VERSION ""

NS_ :

BS_:

BU_: WPC2 RLPSU DPSU APSU PSB SHVU_RR vHS_B2 FCS EMCU SLB ARS RCM CGW_CCU vDummy_HS_B ATS RLHV SGU PFSU ALBCU DSAU SWRC SHVU_FR RCS RRPSU BLTN_CAM SCM DLBCU OHCL RWPC RRHV WPC HOD ASAU

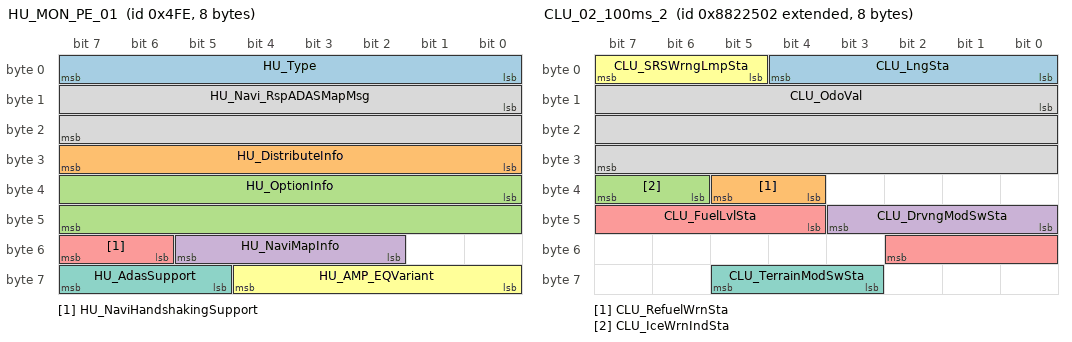
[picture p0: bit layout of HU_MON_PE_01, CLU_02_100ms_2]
BO_ 1278 HU_MON_PE_01: 8 CGW_CCU
 SG_ HU_Type : 0|8@1+ (1,0) [0|0] ""  BLTN_CAM
 SG_ HU_DistributeInfo : 24|8@1+ (1,0) [0|0] ""  BLTN_CAM
 SG_ HU_OptionInfo : 32|16@1+ (1,0) [0|0] ""  RCM,BLTN_CAM,WPC2
 SG_ HU_NaviMapInfo : 50|4@1+ (1,0) [0|0] ""  Vector__XXX
 SG_ HU_NaviHandshakingSupport : 54|2@1+ (1,0) [0|0] ""  Vector__XXX
 SG_ HU_AMP_EQVariant : 56|5@1+ (1,0) [0|0] ""  Vector__XXX
 SG_ HU_AdasSupport : 61|3@1+ (1,0) [0|0] ""  Vector__XXX
 SG_ HU_Navi_RspADASMapMsg : 8|16@1+ (1,0) [0|0] ""  Vector__XXX

BO_ 1279 HU_USM_E_10: 8 CGW_CCU
 SG_ USM_SmartRegen_Map_Set : 11|2@1+ (1,0) [0|0] ""  Vector__XXX
 SG_ USM_SmartRegen_Sens_Set : 13|3@1+ (1,0) [0|0] ""  Vector__XXX
 SG_ AVN_SeatPosMemory_Btn : 16|3@1+ (1,0) [0|0] ""  Vector__XXX
 SG_ AVN_SeatPosPlyBck_Btn : 19|3@1+ (1,0) [0|0] ""  DPSU
 SG_ USM_RhstaLvlEnaSetReq : 22|2@1+ (1,0) [0|0] ""  Vector__XXX
 SG_ USM_CMSDayBrgtnsLvlLHSetReq : 24|4@1+ (1,0) [0|0] ""  Vector__XXX
 SG_ USM_CMSNgtBrgtnsLvlLHSetReq : 28|4@1+ (1,0) [0|0] ""  Vector__XXX
 SG_ USM_CMSDayBrgtnsLvlRHSetReq : 32|4@1+ (1,0) [0|0] ""  Vector__XXX
 SG_ USM_CMSNgtBrgtnsLvlRHSetReq : 36|4@1+ (1,0) [0|0] ""  Vector__XXX
 SG_ USM_CMSBrgtnsReset : 40|2@1+ (1,0) [0|0] ""  Vector__XXX
 SG_ USM_TurnDistLnDispSetReq : 42|2@1+ (1,0) [0|0] ""  Vector__XXX
 SG_ PCA_FrSd_NValueSet : 44|2@1+ (1,0) [0|0] ""  Vector__XXX
 SG_ CF_AVN_1stRrStRmndNValueSet : 46|2@1+ (1,0) [0|0] ""  Vector__XXX
 SG_ C_AllDrOpnNValueSet : 52|3@1+ (1,0) [0|0] ""  Vector__XXX
 SG_ USM_RpmECOSet : 55|2@1+ (1,0) [0|0] ""  Vector__XXX
 SG_ VESS_ChgGuideMdLvl : 57|3@1+ (1,0) [0|0] ""  Vector__XXX
 SG_ Usm_RpmSPORTSet : 60|2@1+ (1,0) [0|0] ""  Vector__XXX
 SG_ Usm_RpmSPORTPLUSSet : 62|2@1+ (1,0) [0|0] ""  Vector__XXX

BO_ 2290230530 CLU_02_100ms_2: 8 CGW_CCU
 SG_ CLU_LngSta : 0|5@1+ (1,0) [0|0] ""  Vector__XXX
 SG_ CLU_RefuelWrnSta : 36|2@1+ (1,0) [0|0] ""  Vector__XXX
 SG_ CLU_IceWrnIndSta : 38|2@1+ (1,0) [0|0] ""  Vector__XXX
 SG_ CLU_DrvngModSwSta : 40|4@1+ (1,0) [0|0] ""  SWRC
 SG_ CLU_FuelLvlSta : 44|7@1+ (1,0) [0|0] "%"  Vector__XXX
 SG_ CLU_SRSWrngLmpSta : 5|3@1+ (1,0) [0|0] ""  Vector__XXX
 SG_ CLU_TerrainModSwSta : 59|3@1+ (1,0) [0|0] ""  SWRC
 SG_ CLU_OdoVal : 8|24@1+ (0.1,0) [0|0] "km"  Vector__XXX

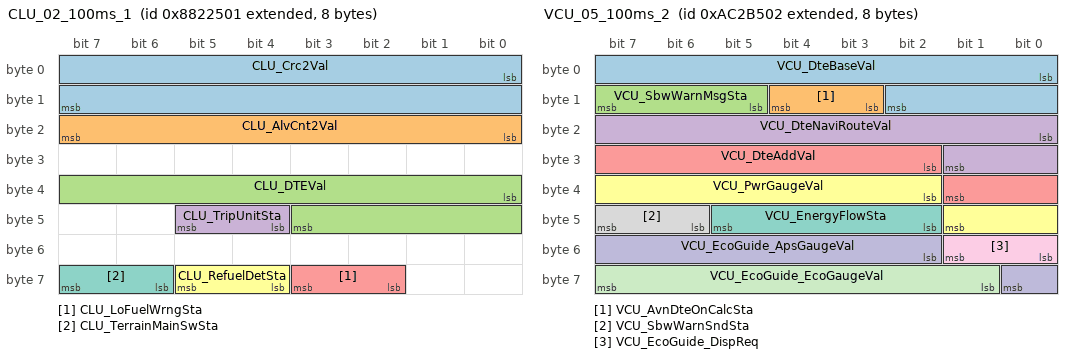
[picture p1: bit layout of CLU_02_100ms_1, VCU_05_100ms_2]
BO_ 2290230529 CLU_02_100ms_1: 8 CGW_CCU
 SG_ CLU_Crc2Val : 0|16@1+ (1,0) [0|0] ""  Vector__XXX
 SG_ CLU_AlvCnt2Val : 16|8@1+ (1,0) [0|0] ""  Vector__XXX
 SG_ CLU_DTEVal : 32|12@1+ (1,0) [0|0] ""  Vector__XXX
 SG_ CLU_TripUnitSta : 44|2@1+ (1,0) [0|0] ""  Vector__XXX
 SG_ CLU_LoFuelWrngSta : 58|2@1+ (1,0) [0|0] ""  Vector__XXX
 SG_ CLU_RefuelDetSta : 60|2@1+ (1,0) [0|0] ""  Vector__XXX
 SG_ CLU_TerrainMainSwSta : 62|2@1+ (1,0) [0|0] ""  Vector__XXX

BO_ 2328016129 VCU_05_100ms_1: 8 CGW_CCU
 SG_ VCU_Crc5Val : 0|16@1+ (1,0) [0|0] ""  Vector__XXX
 SG_ VCU_AlvCnt5Val : 16|8@1+ (1,0) [0|0] ""  Vector__XXX
 SG_ VCU_EvDrvRdyCluDispSta : 24|2@1+ (1,0) [0|3] ""  SWRC
 SG_ VCU_PwrDnModeSta : 26|2@1+ (1,0) [0|3] ""  Vector__XXX
 SG_ VCU_CluWarnMsgSta : 28|4@1+ (1,0) [0|15] ""  Vector__XXX
 SG_ VCU_DteOffDispSta : 32|2@1+ (1,0) [0|0] "flag"  Vector__XXX
 SG_ VCU_LowSocAlertSta : 34|3@1+ (1,0) [0|7] ""  Vector__XXX
 SG_ VCU_VcrmReq : 38|2@1+ (1,0) [0|3] ""  Vector__XXX
 SG_ VCU_PdlWarnMsgSta : 40|2@1+ (1,0) [0|3] ""  Vector__XXX
 SG_ VCU_AwdDiagDispSta : 42|2@1+ (1,0) [0|0] ""  Vector__XXX
 SG_ VCU_AwdLockDispSta : 44|2@1+ (1,0) [0|0] ""  Vector__XXX
 SG_ VCU_VirtualApsActSta : 46|2@1+ (1,0) [0|3] ""  Vector__XXX
 SG_ VCU_VirtualApsVal : 48|8@1+ (0.3906,0) [0|99.61] "%"  Vector__XXX
 SG_ VCU_ServiceLampReq : 56|2@1+ (1,0) [0|3] ""  Vector__XXX
 SG_ VCU_ServiceModeSta : 58|2@1+ (1,0) [0|3] ""  Vector__XXX
 SG_ VCU_NPosWshModSta : 60|2@1+ (1,0) [0|0] "flag"  Vector__XXX
 SG_ VCU_PowerTrainType : 62|2@1+ (1,0) [0|3] ""  Vector__XXX

BO_ 2328016130 VCU_05_100ms_2: 8 CGW_CCU
 SG_ VCU_DteBaseVal : 0|11@1+ (1,0) [0|2047] "km"  Vector__XXX
 SG_ VCU_AvnDteOnCalcSta : 11|2@1+ (1,0) [0|3] ""  Vector__XXX
 SG_ VCU_SbwWarnMsgSta : 13|3@1+ (1,0) [0|0] "flag"  Vector__XXX
 SG_ VCU_DteNaviRouteVal : 16|10@1+ (2,0) [0|1026] "km"  Vector__XXX
 SG_ VCU_DteAddVal : 26|8@1+ (1,0) [0|255] "km"  Vector__XXX
 SG_ VCU_PwrGaugeVal : 34|8@1- (1,0) [-100|100] "%"  Vector__XXX
 SG_ VCU_EnergyFlowSta : 42|4@1+ (1,0) [0|15] ""  Vector__XXX
 SG_ VCU_SbwWarnSndSta : 46|2@1+ (1,0) [0|0] "flag"  Vector__XXX
 SG_ VCU_EcoGuide_DispReq : 48|2@1+ (1,0) [0|3] ""  Vector__XXX
 SG_ VCU_EcoGuide_ApsGaugeVal : 50|7@1+ (1,0) [0|100] "%"  Vector__XXX
 SG_ VCU_EcoGuide_EcoGaugeVal : 57|7@1+ (1,0) [0|100] "%"  Vector__XXX

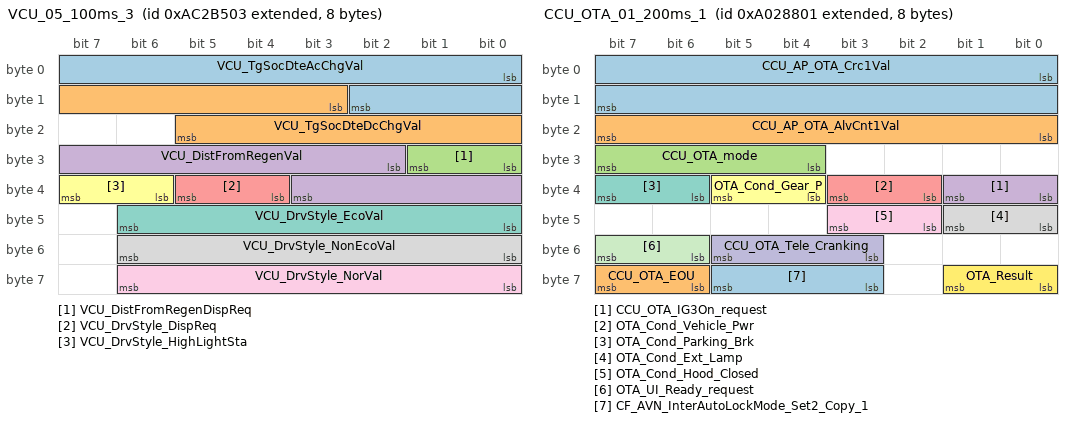
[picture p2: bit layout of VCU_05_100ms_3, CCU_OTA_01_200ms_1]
BO_ 2328016131 VCU_05_100ms_3: 8 CGW_CCU
 SG_ VCU_TgSocDteAcChgVal : 0|11@1+ (1,0) [0|2047] "km"  Vector__XXX
 SG_ VCU_TgSocDteDcChgVal : 11|11@1+ (1,0) [0|2047] "km"  Vector__XXX
 SG_ VCU_DistFromRegenDispReq : 24|2@1+ (1,0) [0|3] ""  Vector__XXX
 SG_ VCU_DistFromRegenVal : 26|10@1+ (10,0) [0|10230] "m"  Vector__XXX
 SG_ VCU_DrvStyle_DispReq : 36|2@1+ (1,0) [0|3] ""  Vector__XXX
 SG_ VCU_DrvStyle_HighLightSta : 38|2@1+ (1,0) [0|3] ""  Vector__XXX
 SG_ VCU_DrvStyle_EcoVal : 40|7@1+ (1,0) [0|100] "%"  Vector__XXX
 SG_ VCU_DrvStyle_NonEcoVal : 48|7@1+ (1,0) [0|100] "%"  Vector__XXX
 SG_ VCU_DrvStyle_NorVal : 56|7@1+ (1,0) [0|100] "%"  Vector__XXX

BO_ 2315421697 CCU_OTA_01_200ms_1: 8 CGW_CCU
 SG_ CCU_AP_OTA_Crc1Val : 0|16@1+ (1,0) [0|0] ""  vDummy_HS_B
 SG_ CCU_AP_OTA_AlvCnt1Val : 16|8@1+ (1,0) [0|0] ""  vDummy_HS_B
 SG_ CCU_OTA_mode : 28|4@1+ (1,0) [0|0] ""  Vector__XXX
 SG_ CCU_OTA_IG3On_request : 32|2@1+ (1,0) [0|0] ""  Vector__XXX
 SG_ OTA_Cond_Vehicle_Pwr : 34|2@1+ (1,0) [0|0] "flag"  Vector__XXX
 SG_ OTA_Cond_Gear_P : 36|2@1+ (1,0) [0|0] "flag"  Vector__XXX
 SG_ OTA_Cond_Parking_Brk : 38|2@1+ (1,0) [0|0] "flag"  Vector__XXX
 SG_ OTA_Cond_Ext_Lamp : 40|2@1+ (1,0) [0|0] "flag"  Vector__XXX
 SG_ OTA_Cond_Hood_Closed : 42|2@1+ (1,0) [0|0] "flag"  Vector__XXX
 SG_ CCU_OTA_Tele_Cranking : 51|3@1+ (1,0) [0|0] ""  Vector__XXX
 SG_ OTA_UI_Ready_request : 54|2@1+ (1,0) [0|0] ""  Vector__XXX
 SG_ OTA_Result : 56|2@1+ (1,0) [0|0] "flag"  Vector__XXX
 SG_ CF_AVN_InterAutoLockMode_Set2_Copy_1 : 59|3@1+ (1,0) [0|0] ""  Vector__XXX
 SG_ CCU_OTA_EOU : 62|2@1+ (1,0) [0|0] ""  Vector__XXX

BO_ 2470763009 CLU_09_00ms_1: 8 CGW_CCU
 SG_ CLU_Crc9Val : 0|16@1+ (1,0) [0|0] ""  Vector__XXX
 SG_ CLU_AlvCnt9Val : 16|8@1+ (1,0) [0|0] ""  Vector__XXX
 SG_ USM_MdLmpClrSetReq : 24|4@1+ (1,0) [0|0] ""  Vector__XXX
 SG_ USM_RrWiperRevSetReq : 28|2@1+ (1,0) [0|0] ""  Vector__XXX
 SG_ USM_RrStRemindSetReq : 30|2@1+ (1,0) [0|0] ""  Vector__XXX
 SG_ USM_RrWpcSetReq : 32|2@1+ (1,0) [0|0] ""  Vector__XXX
 SG_ USM_WpcSetReq : 34|2@1+ (1,0) [0|0] ""  WPC,WPC2
 SG_ USM_SeqLmpSetReq : 36|2@1+ (1,0) [0|0] ""  Vector__XXX
 SG_ USM_UnlckWlcmSetReq : 38|2@1+ (1,0) [0|0] ""  Vector__XXX
 SG_ USM_SmrtWlcmSetReq : 40|2@1+ (1,0) [0|0] ""  Vector__XXX
 SG_ USM_UipSetReq : 42|2@1+ (1,0) [0|0] ""  Vector__XXX
 SG_ USM_DigitalKeyEnblSetReq : 44|2@1+ (1,0) [0|0] ""  Vector__XXX
 SG_ USM_OwnerPhnRegSetReq : 46|2@1+ (1,0) [0|0] ""  Vector__XXX
 SG_ USM_NFCCard1RegSetReq : 48|2@1+ (1,0) [0|0] ""  Vector__XXX
 SG_ USM_NFCCard2RegSetReq : 50|2@1+ (1,0) [0|0] ""  Vector__XXX
 SG_ USM_ProcStpReq : 52|1@1+ (1,0) [0|0] ""  Vector__XXX
 SG_ USM_PwrAutoOffTimeSetReq : 54|3@1+ (1,0) [0|0] ""  Vector__XXX
 SG_ USM_RrStRemindSetReq_RestMode : 57|3@1+ (1,0) [0|0] ""  Vector__XXX
 SG_ USM_1stRrStRemindSetReq : 60|2@1+ (1,0) [0|0] ""  Vector__XXX
 SG_ USM_Wpc2SetReq : 62|2@1+ (1,0) [0|0] ""  WPC2

BO_ 200 HU_USM_E_12: 8 CGW_CCU
 SG_ CF_AVN_ADrLNValueSet_2 : 0|3@1+ (1,0) [0|0] ""  Vector__XXX
 SG_ CF_AVN_FCA_JC_OnOffEquipNvalueSet : 12|2@1+ (1,0) [0|0] ""  Vector__XXX
 SG_ CF_AVN_FCA_FrSdOnOffEquipNvalueSet : 14|2@1+ (1,0) [0|0] ""  Vector__XXX
 SG_ CF_AVN_LKA_OnOffEquip2NvalueSet : 16|2@1+ (1,0) [0|0] ""  Vector__XXX
 SG_ CF_AVN_BCA_OnOffEquip2NvalueSet : 18|2@1+ (1,0) [0|0] ""  Vector__XXX
 SG_ CF_AVN_BVM_OnOffEquipNvalueSet : 20|2@1+ (1,0) [0|0] ""  Vector__XXX
 SG_ CF_AVN_SEA_OnOffEquip3NvalueSet : 22|2@1+ (1,0) [0|0] ""  Vector__XXX
 SG_ CF_AVN_BodySpprtSet_AST : 24|2@1+ (1,0) [0|0] ""  ALBCU
 SG_ CF_AVN_SEW_OnOffEquip3NvalueSet : 26|2@1+ (1,0) [0|0] ""  Vector__XXX
 SG_ CF_AVN_HudImsAutoSave : 28|2@1+ (1,0) [0|0] ""  Vector__XXX
 SG_ USM_PwrDrBuzzerNValueSet : 3|2@1+ (1,0) [0|0] ""  Vector__XXX
 SG_ CF_AVN_DWLNValueSet : 30|3@1+ (1,0) [0|0] ""  Vector__XXX
 SG_ CF_AVN_AirSptTimeNValueSet_AST : 33|3@1+ (1,0) [0|0] ""  ALBCU
 SG_ CF_AVN_AirSptStrNValue_AST : 36|2@1+ (1,0) [0|0] ""  ALBCU
 SG_ CF_AVN_SeatDrvModNvalueSet_AST : 38|2@1+ (1,0) [0|0] ""  ALBCU
 SG_ CF_AVN_TPMS_TireReplaceNValueSet : 40|3@1+ (1,0) [0|0] ""  Vector__XXX
 SG_ CF_AVN_TowModeSet : 43|3@1+ (1,0) [0|0] ""  Vector__XXX
 SG_ USM_PwrDrCloseByBraekNValueSet : 46|2@1+ (1,0) [0|0] ""  Vector__XXX
 SG_ CF_AVN_ISLANAOffstNvalueSet : 50|3@1+ (1,0) [0|0] ""  Vector__XXX
 SG_ CF_Gway_WPC2_NValueSet : 53|2@1+ (1,0) [0|0] ""  WPC2
 SG_ USM_DrvGhostDoorReq : 56|2@1+ (1,0) [0|0] ""  Vector__XXX
 SG_ USM_AstGhostDoorReq : 58|2@1+ (1,0) [0|0] ""  Vector__XXX
 SG_ USM_RLGhostDoorReq : 60|2@1+ (1,0) [0|0] ""  Vector__XXX
 SG_ USM_RRGhostDoorReq : 62|2@1+ (1,0) [0|0] ""  Vector__XXX
 SG_ CF_AVN_FCA_FrOnOffEquipNvalueSet : 7|2@1+ (1,0) [0|0] ""  Vector__XXX
 SG_ CF_AVN_FCA_WarnTimeNvalueSet : 9|3@1+ (1,0) [0|0] ""  Vector__XXX

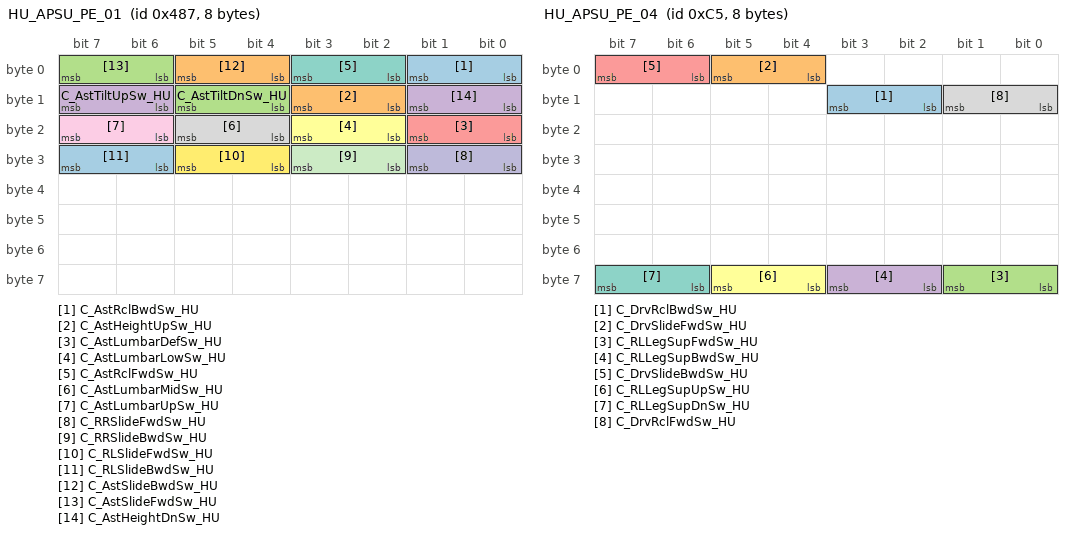
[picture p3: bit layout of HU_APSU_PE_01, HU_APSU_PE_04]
BO_ 1159 HU_APSU_PE_01: 8 CGW_CCU
 SG_ C_AstRclBwdSw_HU : 0|2@1+ (1,0) [0|0] ""  APSU
 SG_ C_AstHeightUpSw_HU : 10|2@1+ (1,0) [0|0] ""  APSU
 SG_ C_AstTiltDnSw_HU : 12|2@1+ (1,0) [0|0] ""  APSU
 SG_ C_AstTiltUpSw_HU : 14|2@1+ (1,0) [0|0] ""  APSU
 SG_ C_AstLumbarDefSw_HU : 16|2@1+ (1,0) [0|0] ""  ASAU,ALBCU
 SG_ C_AstLumbarLowSw_HU : 18|2@1+ (1,0) [0|0] ""  ASAU,ALBCU
 SG_ C_AstRclFwdSw_HU : 2|2@1+ (1,0) [0|0] ""  APSU
 SG_ C_AstLumbarMidSw_HU : 20|2@1+ (1,0) [0|0] ""  ASAU,ALBCU
 SG_ C_AstLumbarUpSw_HU : 22|2@1+ (1,0) [0|0] ""  ASAU,ALBCU
 SG_ C_RRSlideFwdSw_HU : 24|2@1+ (1,0) [0|0] ""  APSU,RRPSU,RLPSU
 SG_ C_RRSlideBwdSw_HU : 26|2@1+ (1,0) [0|0] ""  APSU,RRPSU,RLPSU
 SG_ C_RLSlideFwdSw_HU : 28|2@1+ (1,0) [0|0] ""  APSU,RRPSU,RLPSU
 SG_ C_RLSlideBwdSw_HU : 30|2@1+ (1,0) [0|0] ""  APSU,RRPSU,RLPSU
 SG_ C_AstSlideBwdSw_HU : 4|2@1+ (1,0) [0|0] ""  APSU
 SG_ C_AstSlideFwdSw_HU : 6|2@1+ (1,0) [0|0] ""  APSU
 SG_ C_AstHeightDnSw_HU : 8|2@1+ (1,0) [0|0] ""  APSU

BO_ 197 HU_APSU_PE_04: 8 CGW_CCU
 SG_ C_DrvRclBwdSw_HU : 10|2@1+ (1,0) [0|0] ""  DPSU
 SG_ C_DrvSlideFwdSw_HU : 4|2@1+ (1,0) [0|0] ""  DPSU
 SG_ C_RLLegSupFwdSw_HU : 56|2@1+ (1,0) [0|0] ""  APSU,RRPSU,RLPSU
 SG_ C_RLLegSupBwdSw_HU : 58|2@1+ (1,0) [0|0] ""  APSU,RRPSU,RLPSU
 SG_ C_DrvSlideBwdSw_HU : 6|2@1+ (1,0) [0|0] ""  DPSU
 SG_ C_RLLegSupUpSw_HU : 60|2@1+ (1,0) [0|0] ""  APSU,RRPSU,RLPSU
 SG_ C_RLLegSupDnSw_HU : 62|2@1+ (1,0) [0|0] ""  APSU,RRPSU,RLPSU
 SG_ C_DrvRclFwdSw_HU : 8|2@1+ (1,0) [0|0] ""  DPSU

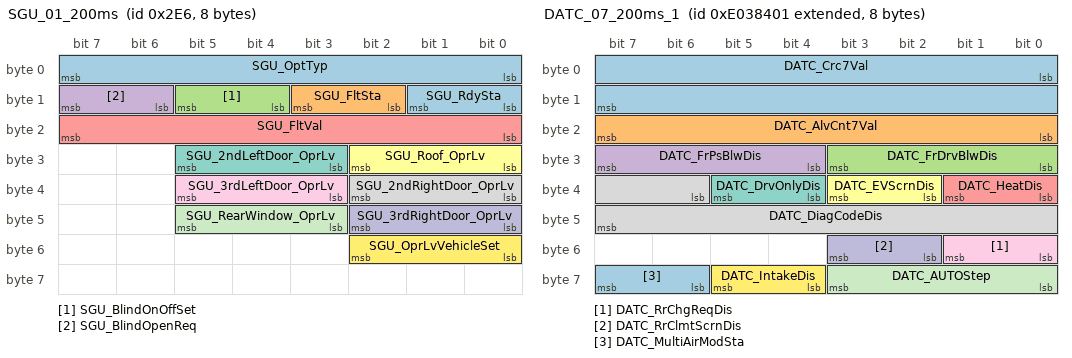
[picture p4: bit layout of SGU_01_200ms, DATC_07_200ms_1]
BO_ 742 SGU_01_200ms: 8 SGU
 SG_ SGU_OptTyp : 0|8@1+ (1,0) [0|0] ""  Vector__XXX
 SG_ SGU_FltSta : 10|2@1+ (1,0) [0|0] ""  Vector__XXX
 SG_ SGU_BlindOnOffSet : 12|2@1+ (1,0) [0|0] ""  CGW_CCU
 SG_ SGU_BlindOpenReq : 14|2@1+ (1,0) [0|0] ""  RCM
 SG_ SGU_FltVal : 16|8@1+ (1,0) [0|0] ""  Vector__XXX
 SG_ SGU_Roof_OprLv : 24|3@1+ (1,0) [0|0] ""  CGW_CCU
 SG_ SGU_2ndLeftDoor_OprLv : 27|3@1+ (1,0) [0|0] ""  CGW_CCU
 SG_ SGU_2ndRightDoor_OprLv : 32|3@1+ (1,0) [0|0] ""  CGW_CCU
 SG_ SGU_3rdLeftDoor_OprLv : 35|3@1+ (1,0) [0|0] ""  CGW_CCU
 SG_ SGU_3rdRightDoor_OprLv : 40|3@1+ (1,0) [0|0] ""  CGW_CCU
 SG_ SGU_RearWindow_OprLv : 43|3@1+ (1,0) [0|0] ""  CGW_CCU
 SG_ SGU_OprLvVehicleSet : 48|3@1+ (1,0) [0|0] ""  CGW_CCU
 SG_ SGU_RdySta : 8|2@1+ (1,0) [0|0] ""  Vector__XXX

BO_ 2382595073 DATC_07_200ms_1: 8 CGW_CCU
 SG_ DATC_Crc7Val : 0|16@1+ (1,0) [0|0] ""  Vector__XXX
 SG_ DATC_AlvCnt7Val : 16|8@1+ (1,0) [0|0] ""  Vector__XXX
 SG_ DATC_FrDrvBlwDis : 24|4@1+ (1,0) [0|0] ""  ATS
 SG_ DATC_FrPsBlwDis : 28|4@1+ (1,0) [0|0] ""  ATS
 SG_ DATC_HeatDis : 32|2@1+ (1,0) [0|0] "flag"  ATS
 SG_ DATC_EVScrnDis : 34|2@1+ (1,0) [0|0] ""  Vector__XXX
 SG_ DATC_DrvOnlyDis : 36|2@1+ (1,0) [0|0] ""  ATS
 SG_ DATC_DiagCodeDis : 38|10@1+ (1,-1) [0|0] ""  Vector__XXX
 SG_ DATC_RrChgReqDis : 48|2@1+ (1,0) [0|0] ""  Vector__XXX
 SG_ DATC_RrClmtScrnDis : 50|2@1+ (1,0) [0|0] ""  ATS
 SG_ DATC_AUTOStep : 56|4@1+ (1,0) [0|0] ""  ATS
 SG_ DATC_IntakeDis : 60|2@1+ (1,0) [0|0] ""  ATS
 SG_ DATC_MultiAirModSta : 62|2@1+ (1,0) [0|0] ""  Vector__XXX

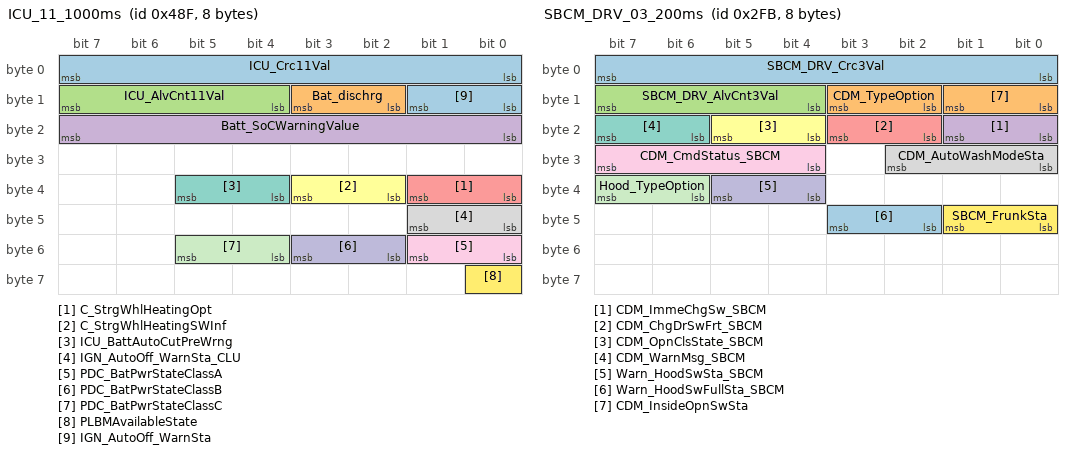
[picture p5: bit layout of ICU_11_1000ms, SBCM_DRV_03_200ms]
BO_ 1167 ICU_11_1000ms: 8 CGW_CCU
 SG_ ICU_Crc11Val : 0|8@1+ (1,0) [0|0] ""  Vector__XXX
 SG_ Bat_dischrg : 10|2@1+ (1,0) [0|0] ""  Vector__XXX
 SG_ ICU_AlvCnt11Val : 12|4@1+ (1,0) [0|0] ""  Vector__XXX
 SG_ Batt_SoCWarningValue : 16|8@1+ (1,0) [0|0] "%"  Vector__XXX
 SG_ C_StrgWhlHeatingOpt : 32|2@1+ (1,0) [0|0] ""  Vector__XXX
 SG_ C_StrgWhlHeatingSWInf : 34|2@1+ (1,0) [0|0] ""  Vector__XXX
 SG_ ICU_BattAutoCutPreWrng : 36|2@1+ (1,0) [0|0] ""  BLTN_CAM
 SG_ IGN_AutoOff_WarnSta_CLU : 40|2@1+ (1,0) [0|0] ""  Vector__XXX
 SG_ PDC_BatPwrStateClassA : 48|2@1+ (1,0) [0|0] ""  Vector__XXX
 SG_ PDC_BatPwrStateClassB : 50|2@1+ (1,0) [0|0] ""  Vector__XXX
 SG_ PDC_BatPwrStateClassC : 52|2@1+ (1,0) [0|0] ""  Vector__XXX
 SG_ PLBMAvailableState : 56|1@1+ (1,0) [0|0] ""  Vector__XXX
 SG_ IGN_AutoOff_WarnSta : 8|2@1+ (1,0) [0|0] ""  Vector__XXX

BO_ 763 SBCM_DRV_03_200ms: 8 CGW_CCU
 SG_ SBCM_DRV_Crc3Val : 0|8@1+ (1,0) [0|0] ""  Vector__XXX
 SG_ CDM_TypeOption : 10|2@1+ (1,0) [0|0] ""  Vector__XXX
 SG_ SBCM_DRV_AlvCnt3Val : 12|4@1+ (1,0) [0|0] ""  Vector__XXX
 SG_ CDM_ImmeChgSw_SBCM : 16|2@1+ (1,0) [0|0] ""  Vector__XXX
 SG_ CDM_ChgDrSwFrt_SBCM : 18|2@1+ (1,0) [0|0] ""  Vector__XXX
 SG_ CDM_OpnClsState_SBCM : 20|2@1+ (1,0) [0|0] ""  Vector__XXX
 SG_ CDM_WarnMsg_SBCM : 22|2@1+ (1,0) [0|0] ""  Vector__XXX
 SG_ CDM_AutoWashModeSta : 24|3@1+ (1,0) [0|0] ""  Vector__XXX
 SG_ CDM_CmdStatus_SBCM : 28|4@1+ (1,0) [0|0] ""  Vector__XXX
 SG_ Warn_HoodSwSta_SBCM : 36|2@1+ (1,0) [0|0] ""  BLTN_CAM
 SG_ Hood_TypeOption : 38|2@1+ (1,0) [0|0] ""  BLTN_CAM
 SG_ SBCM_FrunkSta : 40|2@1+ (1,0) [0|0] ""  Vector__XXX
 SG_ Warn_HoodSwFullSta_SBCM : 42|2@1+ (1,0) [0|0] ""  Vector__XXX
 SG_ CDM_InsideOpnSwSta : 8|2@1+ (1,0) [0|0] ""  Vector__XXX

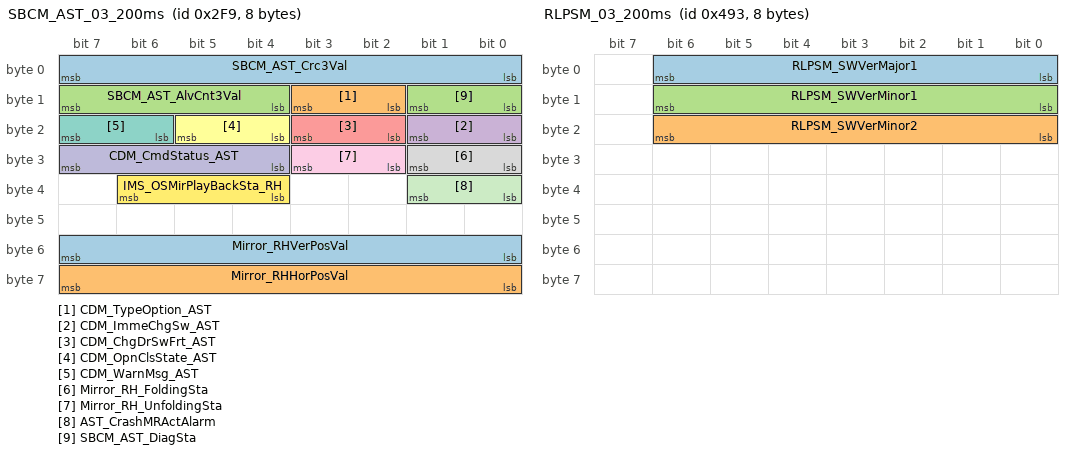
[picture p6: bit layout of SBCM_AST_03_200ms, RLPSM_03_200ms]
BO_ 761 SBCM_AST_03_200ms: 8 CGW_CCU
 SG_ SBCM_AST_Crc3Val : 0|8@1+ (1,0) [0|0] ""  Vector__XXX
 SG_ CDM_TypeOption_AST : 10|2@1+ (1,0) [0|0] ""  Vector__XXX
 SG_ SBCM_AST_AlvCnt3Val : 12|4@1+ (1,0) [0|0] ""  Vector__XXX
 SG_ CDM_ImmeChgSw_AST : 16|2@1+ (1,0) [0|0] ""  Vector__XXX
 SG_ CDM_ChgDrSwFrt_AST : 18|2@1+ (1,0) [0|0] ""  Vector__XXX
 SG_ CDM_OpnClsState_AST : 20|2@1+ (1,0) [0|0] ""  Vector__XXX
 SG_ CDM_WarnMsg_AST : 22|2@1+ (1,0) [0|0] ""  Vector__XXX
 SG_ Mirror_RH_FoldingSta : 24|2@1+ (1,0) [0|0] ""  Vector__XXX
 SG_ Mirror_RH_UnfoldingSta : 26|2@1+ (1,0) [0|0] ""  Vector__XXX
 SG_ CDM_CmdStatus_AST : 28|4@1+ (1,0) [0|0] ""  Vector__XXX
 SG_ AST_CrashMRActAlarm : 32|2@1+ (1,0) [0|0] ""  Vector__XXX
 SG_ IMS_OSMirPlayBackSta_RH : 36|3@1+ (1,0) [0|0] ""  DPSU
 SG_ Mirror_RHVerPosVal : 48|8@1+ (0.02,0) [0|0] "V"  Vector__XXX
 SG_ Mirror_RHHorPosVal : 56|8@1+ (0.02,0) [0|0] "V"  Vector__XXX
 SG_ SBCM_AST_DiagSta : 8|2@1+ (1,0) [0|0] ""  Vector__XXX

BO_ 1171 RLPSM_03_200ms: 8 RLPSU
 SG_ RLPSM_SWVerMajor1 : 0|7@1+ (1,0) [0|0] ""  Vector__XXX
 SG_ RLPSM_SWVerMinor2 : 16|7@1+ (1,0) [0|0] ""  Vector__XXX
 SG_ RLPSM_SWVerMinor1 : 8|7@1+ (1,0) [0|0] ""  Vector__XXX

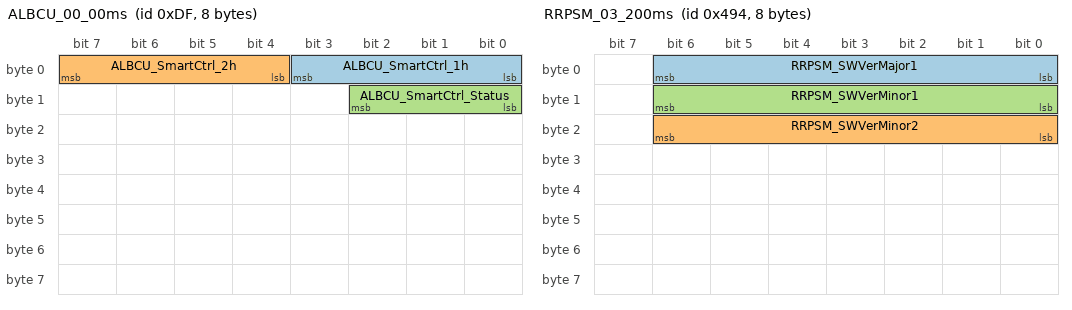
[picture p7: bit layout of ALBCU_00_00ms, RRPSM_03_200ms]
BO_ 223 ALBCU_00_00ms: 8 ALBCU
 SG_ ALBCU_SmartCtrl_1h : 0|4@1+ (1,0) [0|0] ""  CGW_CCU
 SG_ ALBCU_SmartCtrl_2h : 4|4@1+ (1,0) [0|0] ""  CGW_CCU
 SG_ ALBCU_SmartCtrl_Status : 8|3@1+ (1,0) [0|0] ""  CGW_CCU

BO_ 1172 RRPSM_03_200ms: 8 RRPSU
 SG_ RRPSM_SWVerMajor1 : 0|7@1+ (1,0) [0|0] ""  Vector__XXX
 SG_ RRPSM_SWVerMinor2 : 16|7@1+ (1,0) [0|0] ""  Vector__XXX
 SG_ RRPSM_SWVerMinor1 : 8|7@1+ (1,0) [0|0] ""  Vector__XXX

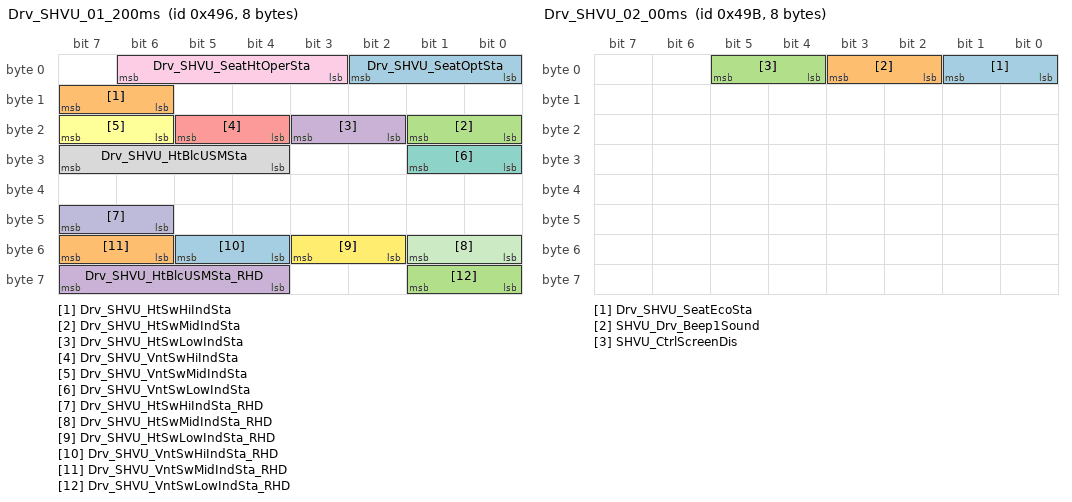
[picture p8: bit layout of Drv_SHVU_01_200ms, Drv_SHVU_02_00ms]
BO_ 1174 Drv_SHVU_01_200ms: 8 APSU
 SG_ Drv_SHVU_SeatOptSta : 0|3@1+ (1,0) [0|0] ""  CGW_CCU,FCS,CGW_CCU
 SG_ Drv_SHVU_HtSwHiIndSta : 14|2@1+ (1,0) [0|0] ""  FCS,CGW_CCU
 SG_ Drv_SHVU_HtSwMidIndSta : 16|2@1+ (1,0) [0|0] ""  FCS,CGW_CCU
 SG_ Drv_SHVU_HtSwLowIndSta : 18|2@1+ (1,0) [0|0] ""  FCS,CGW_CCU
 SG_ Drv_SHVU_VntSwHiIndSta : 20|2@1+ (1,0) [0|0] ""  FCS,CGW_CCU
 SG_ Drv_SHVU_VntSwMidIndSta : 22|2@1+ (1,0) [0|0] ""  FCS,CGW_CCU
 SG_ Drv_SHVU_VntSwLowIndSta : 24|2@1+ (1,0) [0|0] ""  FCS,CGW_CCU
 SG_ Drv_SHVU_HtBlcUSMSta : 28|4@1+ (1,0) [0|0] ""  CGW_CCU
 SG_ Drv_SHVU_SeatHtOperSta : 3|4@1+ (1,0) [0|0] ""  CGW_CCU
 SG_ Drv_SHVU_HtSwHiIndSta_RHD : 46|2@1+ (1,0) [0|0] ""  FCS,CGW_CCU
 SG_ Drv_SHVU_HtSwMidIndSta_RHD : 48|2@1+ (1,0) [0|0] ""  FCS,CGW_CCU
 SG_ Drv_SHVU_HtSwLowIndSta_RHD : 50|2@1+ (1,0) [0|0] ""  FCS,CGW_CCU
 SG_ Drv_SHVU_VntSwHiIndSta_RHD : 52|2@1+ (1,0) [0|0] ""  FCS,CGW_CCU
 SG_ Drv_SHVU_VntSwMidIndSta_RHD : 54|2@1+ (1,0) [0|0] ""  FCS,CGW_CCU
 SG_ Drv_SHVU_VntSwLowIndSta_RHD : 56|2@1+ (1,0) [0|0] ""  FCS,CGW_CCU
 SG_ Drv_SHVU_HtBlcUSMSta_RHD : 60|4@1+ (1,0) [0|0] ""  CGW_CCU

BO_ 1179 Drv_SHVU_02_00ms: 8 APSU
 SG_ Drv_SHVU_SeatEcoSta : 0|2@1+ (1,0) [0|0] ""  CGW_CCU
 SG_ SHVU_Drv_Beep1Sound : 2|2@1+ (1,0) [0|0] ""  CGW_CCU
 SG_ SHVU_CtrlScreenDis : 4|2@1+ (1,0) [0|0] ""  CGW_CCU

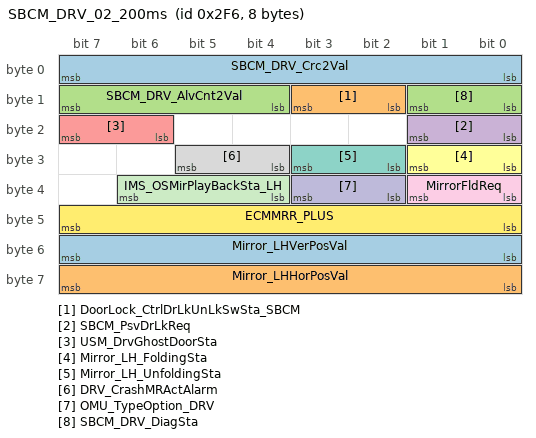
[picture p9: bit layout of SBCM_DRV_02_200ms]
BO_ 758 SBCM_DRV_02_200ms: 8 CGW_CCU
 SG_ SBCM_DRV_Crc2Val : 0|8@1+ (1,0) [0|0] ""  Vector__XXX
 SG_ DoorLock_CtrlDrLkUnLkSwSta_SBCM : 10|2@1+ (1,0) [0|0] ""  Vector__XXX
 SG_ SBCM_DRV_AlvCnt2Val : 12|4@1+ (1,0) [0|0] ""  Vector__XXX
 SG_ SBCM_PsvDrLkReq : 16|2@1+ (1,0) [0|0] ""  Vector__XXX
 SG_ USM_DrvGhostDoorSta : 22|2@1+ (1,0) [0|0] ""  Vector__XXX
 SG_ Mirror_LH_FoldingSta : 24|2@1+ (1,0) [0|0] ""  Vector__XXX
 SG_ Mirror_LH_UnfoldingSta : 26|2@1+ (1,0) [0|0] ""  Vector__XXX
 SG_ DRV_CrashMRActAlarm : 28|2@1+ (1,0) [0|0] ""  Vector__XXX
 SG_ MirrorFldReq : 32|2@1+ (1,0) [0|0] ""  Vector__XXX
 SG_ OMU_TypeOption_DRV : 34|2@1+ (1,0) [0|0] ""  Vector__XXX
 SG_ IMS_OSMirPlayBackSta_LH : 36|3@1+ (1,0) [0|0] ""  DPSU
 SG_ ECMMRR_PLUS : 40|8@1+ (1,0) [0|0] ""  Vector__XXX
 SG_ Mirror_LHVerPosVal : 48|8@1+ (0.02,0) [0|0] "V"  Vector__XXX
 SG_ Mirror_LHHorPosVal : 56|8@1+ (0.02,0) [0|0] "V"  Vector__XXX
 SG_ SBCM_DRV_DiagSta : 8|2@1+ (1,0) [0|0] ""  Vector__XXX

BO_ 208 RR_SHVU_03_200ms: 8 RRHV
 SG_ RR_SHVU_DTCdisplay : 0|8@1+ (1,0) [0|0] ""  ATS
 SG_ RR_SHVU_DiagMode : 8|2@1+ (1,0) [0|0] ""  ATS

BO_ 1180 Ast_SHVU_02_00ms: 8 SHVU_FR
 SG_ SHVU_Ast_Beep1Sound : 2|2@1+ (1,0) [0|0] ""  CGW_CCU
 SG_ Ast_SHVU_SeatEcoSta : 26|2@1+ (1,0) [0|0] ""  CGW_CCU

BO_ 1181 RL_SHVU_02_00ms: 8 SHVU_RR
 SG_ RL_SHVU_SeatEcoSta : 0|2@1+ (1,0) [0|0] ""  ATS,CGW_CCU

BO_ 1182 RR_SHVU_02_00ms: 8 SHVU_FR
 SG_ RR_SHVU_SeatEcoSta : 0|2@1+ (1,0) [0|0] ""  ATS,CGW_CCU

BO_TX_BU_ 1174 : APSU,SHVU_FR,DPSU;
BO_TX_BU_ 1179 : APSU,SHVU_FR;
BO_TX_BU_ 208 : RRHV,SHVU_FR,SHVU_RR;
BO_TX_BU_ 1181 : SHVU_RR,SHVU_FR,RLHV,RLPSU;
BO_TX_BU_ 1182 : SHVU_FR,RRPSU,SHVU_RR,RRHV;
CM_ BO_ 223 "[EC] On Event and On Change";
CM_ SG_ 223 ALBCU_SmartCtrl_1h "Smart Posture Adjust 1hr";
CM_ SG_ 223 ALBCU_SmartCtrl_2h "Smart Posture Adjust AVN Display (2hr)";
CM_ SG_ 223 ALBCU_SmartCtrl_Status "Smart Posture Adjust 2nd Interlocked Move AVN popup request";
CM_ BO_ 1180 "[EC] On Event and On Change";
CM_ SG_ 1180 SHVU_Ast_Beep1Sound "SHVU_FR Assistant's Seat Heater or Ventilation Switch input Beep Request";
CM_ SG_ 1180 Ast_SHVU_SeatEcoSta "Assistant (Passenger) Seat Eco+ Mode Status";
CM_ BO_ 2315421697 "[PE] Periodic and On Event";
CM_ SG_ 2315421697 CCU_OTA_mode "OTA_mode";
CM_ SG_ 2315421697 CCU_OTA_IG3On_request "IG3 Rly ON request";
CM_ SG_ 2315421697 CCU_OTA_Tele_Cranking "Vehicle cranking request signfal for OTA Update";
CM_ SG_ 2315421697 OTA_UI_Ready_request "OTA UI Ready";
CM_ SG_ 2315421697 OTA_Result "¾÷µ¥ÀÌÆ® °á°ú";
CM_ SG_ 2315421697 CF_AVN_InterAutoLockMode_Set2_Copy_1 "USM Request for Charing Connector Locking Mode (Auto/Lock/Unlock)";
CM_ BO_ 2290230529 "[P] Periodic";
CM_ SG_ 2290230529 CLU_Crc2Val "CLU_CyclicRedundancyCheck2Value";
CM_ SG_ 2290230529 CLU_AlvCnt2Val "CLU_AliveCounter2Value";
CM_ SG_ 2290230529 CLU_DTEVal "CLU_DTEValue";
CM_ SG_ 2290230529 CLU_TripUnitSta "CLU_TripUnitStatus";
CM_ SG_ 2290230529 CLU_LoFuelWrngSta "CLU_LowFuelWarningStatus";
CM_ SG_ 2290230529 CLU_RefuelDetSta "CLU_RefuelDetectedStatus";
CM_ SG_ 2290230529 CLU_TerrainMainSwSta "CLU_TerrainMainSwitchStatus";
CM_ BO_ 2290230530 "[P] Periodic";
CM_ SG_ 2290230530 CLU_LngSta "CLU_LanguageStatus";
CM_ SG_ 2290230530 CLU_RefuelWrnSta "CLU_RefuelWarningStatus";
CM_ SG_ 2290230530 CLU_IceWrnIndSta "CLU_IceWarnIndicatorStatus";
CM_ SG_ 2290230530 CLU_DrvngModSwSta "CLU_DrivingModeSwitchStatus";
CM_ SG_ 2290230530 CLU_FuelLvlSta "CLU_FuelLevelStatus";
CM_ SG_ 2290230530 CLU_SRSWrngLmpSta "CLU_SRSWarningLampStatus";
CM_ SG_ 2290230530 CLU_TerrainModSwSta "CLU_TerrainModeSwitchStatus";
CM_ SG_ 2290230530 CLU_OdoVal "CLU_OdometerValue";
CM_ BO_ 2470763009 "[EC] On Event and On Change";
CM_ SG_ 2470763009 CLU_Crc9Val "CLU_CyclicRedundancyCheck9Value";
CM_ SG_ 2470763009 CLU_AlvCnt9Val "CLU_AliveCounter9Value";
CM_ SG_ 2470763009 USM_MdLmpClrSetReq "USM_MoodLampColorSetRequest";
CM_ SG_ 2470763009 USM_RrWiperRevSetReq "USM_RearWiperReverseSetRequest";
CM_ SG_ 2470763009 USM_RrStRemindSetReq "USM_RrseatReminderSetRequest(2nd :General: CLU20/CF_Clu_RrSeatRemindNValueSet)";
CM_ SG_ 2470763009 USM_RrWpcSetReq "USM_RearWpcSetRequest";
CM_ SG_ 2470763009 USM_WpcSetReq "USM_WpcSetRequest";
CM_ SG_ 2470763009 USM_SeqLmpSetReq "USM_SequencialLampSetRequest";
CM_ SG_ 2470763009 USM_UnlckWlcmSetReq "USM_UnlockWelcomeSetRequest";
CM_ SG_ 2470763009 USM_SmrtWlcmSetReq "USM_SmartWelcomeSetRequest";
CM_ SG_ 2470763009 USM_UipSetReq "2nd General: CF_Clu_UIPNValueSet";
CM_ SG_ 2470763009 USM_DigitalKeyEnblSetReq "Request to set the Digital Key ON or OFF(2nd General DB: CF_Clu_DigitalKeyNValueSet)";
CM_ SG_ 2470763009 USM_OwnerPhnRegSetReq "2nd general DB: CF_Clu_OwnerPhoneNValueSet";
CM_ SG_ 2470763009 USM_NFCCard1RegSetReq "2nd General DB:CF_Clu_NFCCard1NValueSet";
CM_ SG_ 2470763009 USM_NFCCard2RegSetReq "2nd General DB:CF_Clu_NFCCard2NValueSet";
CM_ SG_ 2470763009 USM_ProcStpReq "2nd General DB:CF_Clu_ProcessStopReq";
CM_ SG_ 2470763009 USM_PwrAutoOffTimeSetReq "USM_PowerAutoofftimeSetRequest";
CM_ SG_ 2470763009 USM_RrStRemindSetReq_RestMode "Request to set  Restmod of Rear Seat remind";
CM_ SG_ 2470763009 USM_1stRrStRemindSetReq "USM_RrseatReminderSetRequest(2nd :General: CLU21/CF_Clu_1stRrSeatRemindNValueSet)";
CM_ SG_ 2470763009 USM_Wpc2SetReq "USM_Wpc2SetRequest";
CM_ BO_ 2382595073 "[PE] Periodic and On Event";
CM_ SG_ 2382595073 DATC_Crc7Val "DATC_CyclicRedundancyCheck7Value";
CM_ SG_ 2382595073 DATC_AlvCnt7Val "DATC_AliveCounter7Value";
CM_ SG_ 2382595073 DATC_FrDrvBlwDis "DATC_FrontDriverBlowerDisplay";
CM_ SG_ 2382595073 DATC_FrPsBlwDis "DATC_FrontPassengerBlowerDisplay";
CM_ SG_ 2382595073 DATC_HeatDis "DATC_HeatDisplay";
CM_ SG_ 2382595073 DATC_EVScrnDis "DATC_EVScreenDisplay";
CM_ SG_ 2382595073 DATC_DrvOnlyDis "DATC_DriverOnlyDisplay";
CM_ SG_ 2382595073 DATC_DiagCodeDis "DATC_DiagnosisCodeDisplay";
CM_ SG_ 2382595073 DATC_RrChgReqDis "DATC_RearChangeRequestDisplay";
CM_ SG_ 2382595073 DATC_RrClmtScrnDis "DATC_RearClimateScreenDisplay";
CM_ SG_ 2382595073 DATC_AUTOStep "This signal indicates AUTO step status in case Multi Auto Blower type.";
CM_ SG_ 2382595073 DATC_IntakeDis "This signal indicates intake indicator & display";
CM_ SG_ 2382595073 DATC_MultiAirModSta "This signal indicates MultiAirModeStatus";
CM_ BO_ 1174 "[PE] Periodic and On Event";
CM_ SG_ 1174 Drv_SHVU_SeatOptSta "Drv Seat Heater/Vent option info";
CM_ SG_ 1174 Drv_SHVU_HtSwHiIndSta "Drv Seat Heater Switch High Indicator Status";
CM_ SG_ 1174 Drv_SHVU_HtSwMidIndSta "Drv Seat Heater Switch Mid Indicator Status";
CM_ SG_ 1174 Drv_SHVU_HtSwLowIndSta "Drv Seat Heater Switch Low Indicator Status";
CM_ SG_ 1174 Drv_SHVU_VntSwHiIndSta "Drv Seat Vent Switch High Indicator Status";
CM_ SG_ 1174 Drv_SHVU_VntSwMidIndSta "Drv Seat Vent Switch Mid Indicator Status";
CM_ SG_ 1174 Drv_SHVU_VntSwLowIndSta "Drv Seat Vent Switch Low Indicator Status";
CM_ SG_ 1174 Drv_SHVU_HtBlcUSMSta "Hetaer Balance Driver USM R vaule";
CM_ SG_ 1174 Drv_SHVU_SeatHtOperSta "Drv Seat Heater/Vent current operation state";
CM_ SG_ 1174 Drv_SHVU_HtSwHiIndSta_RHD "Drv Seat Heater Switch High Indicator Status(RHD)";
CM_ SG_ 1174 Drv_SHVU_HtSwMidIndSta_RHD "Drv Seat Heater Switch Mid Indicator Status(RHD)";
CM_ SG_ 1174 Drv_SHVU_HtSwLowIndSta_RHD "Drv Seat Heater Switch Low Indicator Status(RHD)";
CM_ SG_ 1174 Drv_SHVU_VntSwHiIndSta_RHD "Drv Seat Vent Switch High Indicator Status(RHD)";
CM_ SG_ 1174 Drv_SHVU_VntSwMidIndSta_RHD "Drv Seat Vent Switch Mid Indicator Status(RHD)";
CM_ SG_ 1174 Drv_SHVU_VntSwLowIndSta_RHD "Drv Seat Vent Switch Low Indicator Status(RHD)";
CM_ SG_ 1174 Drv_SHVU_HtBlcUSMSta_RHD "Hetaer Balance Driver USM R vaule(RHD)";
CM_ BO_ 1179 "[EC] On Event and On Change";
CM_ SG_ 1179 Drv_SHVU_SeatEcoSta "Driver Seat Eco+ Mode Status";
CM_ SG_ 1179 SHVU_Drv_Beep1Sound "SHVU_FR Driver's Seat Heater or Ventilation Switch input Beep Request";
CM_ SG_ 1179 SHVU_CtrlScreenDis "Request AVN screen change for controlling Seat Heater or Ventilation";
CM_ BO_ 1159 "[PE] Periodic and On Event";
CM_ SG_ 1159 C_AstRclBwdSw_HU "Assistant seat Moving control :Recline Backward";
CM_ SG_ 1159 C_AstHeightUpSw_HU "Assistant seat Moving control : Height Up";
CM_ SG_ 1159 C_AstTiltDnSw_HU "Assistant seat Moving control : Tilt Down";
CM_ SG_ 1159 C_AstTiltUpSw_HU "Assistant seat Moving Switch : Tilt Up";
CM_ SG_ 1159 C_AstLumbarDefSw_HU "Assistant seat moving switch: Deflate";
CM_ SG_ 1159 C_AstLumbarLowSw_HU "Assistant seat moving switch:Lumbar Low";
CM_ SG_ 1159 C_AstRclFwdSw_HU "Assistant seat Moving Switch : Recline Forward";
CM_ SG_ 1159 C_AstLumbarMidSw_HU "Assistant seat Moving control : Lumbar Mid";
CM_ SG_ 1159 C_AstLumbarUpSw_HU "Assistant seat Moving control : Lumbar Up";
CM_ SG_ 1159 C_RRSlideFwdSw_HU "2nd Right side seat Moving control :Power Slide Forward";
CM_ SG_ 1159 C_RRSlideBwdSw_HU "2nd Right side seat Moving control :Power Slide Backward";
CM_ SG_ 1159 C_RLSlideFwdSw_HU "2nd Left side seat Moving control :Power Slide Forward";
CM_ SG_ 1159 C_RLSlideBwdSw_HU "2nd Left side seat Moving control :Power Slide Backward";
CM_ SG_ 1159 C_AstSlideBwdSw_HU "Assistant seat moving switch : Slide Backward";
CM_ SG_ 1159 C_AstSlideFwdSw_HU "Assistant seat Moving switch : Slide Forward";
CM_ SG_ 1159 C_AstHeightDnSw_HU "Assistant seat Moving control : Height Down";
CM_ BO_ 197 "[PE] Periodic and On Event";
CM_ SG_ 197 C_DrvRclBwdSw_HU "Driver Seat Recline Backward Control";
CM_ SG_ 197 C_DrvSlideFwdSw_HU "Driver Seat Slide Forward Control";
CM_ SG_ 197 C_RLLegSupFwdSw_HU "2nd Left side seat Moving control : Leg Support Forward";
CM_ SG_ 197 C_RLLegSupBwdSw_HU "2nd Left side seat Moving control : Leg Support Backward";
CM_ SG_ 197 C_DrvSlideBwdSw_HU "Driver Seat Slide Backward Control";
CM_ SG_ 197 C_RLLegSupUpSw_HU "2nd Left side seat Moving control : Leg Support Up";
CM_ SG_ 197 C_RLLegSupDnSw_HU "2nd Left side seat Moving control : Leg Support Down";
CM_ SG_ 197 C_DrvRclFwdSw_HU "Driver Seat Recline Forward Control";
CM_ BO_ 1278 "[PE] Periodic and On Event";
CM_ SG_ 1278 HU_Type "Information for H/U Platform type
- Integrated AVN 1.0 use different value depends on development company (Mobis:0x68/LG:0x70)
- Integrated AVN 1.0 Mobis is developed based on Display Audio
- Integrated AVN 1.0 LG is developed based on Compact AVN

Information for China OPIO Platform
- 0xFC: China OPIO w/o CLU interface (most of phase1)
- 0xFD: China OPIO w/CLU interface (parts of phase1, phase2)

Information for Audio Platform Type
- 0x43 : Audio 4.0 Value";
CM_ SG_ 1278 HU_DistributeInfo "Region :Europe/North America/
Vehicle Type : RHD/LHD
Positionning information";
CM_ SG_ 1278 HU_OptionInfo "Information of H/U functions";
CM_ SG_ 1278 HU_NaviMapInfo "Information about map data  used in Navigation";
CM_ SG_ 1278 HU_NaviHandshakingSupport "This is a signal to send whether handshaking logic is applied related to Navigation's 'Map based ADAS' specification";
CM_ SG_ 1278 HU_AMP_EQVariant "Set EQ Variant for various vehicle cases.
During the AMP initializing process, This signal should be sent before AMP unmute.
This signal is only needed for models that have variant EQ for vehicle types. (Hatchback, Wagon, Hybrid etc..)
Models that doesn¡¯t have variant EQ for vehicle types shouldn¡¯t have this signal.";
CM_ SG_ 1278 HU_AdasSupport "Information about ADAS support
-Classify between General Map and Precise Map Transmission Function
-AVN System Transmission Signal";
CM_ SG_ 1278 HU_Navi_RspADASMapMsg "HU_ResponseADASMapMessage";
CM_ BO_ 1279 "[EC] On Event and On Change";
CM_ SG_ 1279 USM_SmartRegen_Map_Set "Smart Regeneration 2.0 Map information USM User set signal";
CM_ SG_ 1279 USM_SmartRegen_Sens_Set "Smart Regeneration User Personality of Reduction Set Signal";
CM_ SG_ 1279 AVN_SeatPosMemory_Btn "Seat position save signal";
CM_ SG_ 1279 AVN_SeatPosPlyBck_Btn "Seat position move signal";
CM_ SG_ 1279 USM_CMSBrgtnsReset "CMS Brightness Reset (LH/RH)";
CM_ SG_ 1279 CF_AVN_1stRrStRmndNValueSet "This signal is for setting the ROA function when IBU control ROA Function.";
CM_ SG_ 1279 VESS_ChgGuideMdLvl "Releated to VESS Alarm Sound Level";
CM_ BO_ 200 "[EC] On Event and On Change";
CM_ SG_ 200 CF_AVN_BodySpprtSet_AST "This signal is for the Ergo-Motion seat (AST) body support (Smart Posture Assist) USM";
CM_ SG_ 200 CF_AVN_AirSptTimeNValueSet_AST "This signal is for the Ergo-Motion seat (AST) massage function time setting";
CM_ SG_ 200 CF_AVN_AirSptStrNValue_AST "This signal is for the ERGO seat (AST) massage intensity USM";
CM_ SG_ 200 CF_AVN_SeatDrvModNvalueSet_AST "This signal is for the Ergo-Motion seat (AST) smart support (Smart Support) USM";
CM_ BO_ 1167 "[PE] Periodic and On Event";
CM_ SG_ 1167 ICU_Crc11Val "ICU_CyclicRedundancyCheck11Value";
CM_ SG_ 1167 Bat_dischrg "Battery discharge notification flag #2G# Bat_dischrg";
CM_ SG_ 1167 ICU_AlvCnt11Val "ICU_AliveCounter11Value";
CM_ SG_ 1167 Batt_SoCWarningValue "Value of SoC warning level. ##2G## -  - Batt_SoCWarningValue";
CM_ SG_ 1167 ICU_BattAutoCutPreWrng "This is a warning signal before blocking the dark current of the ICU by the battery SOC.";
CM_ SG_ 1167 IGN_AutoOff_WarnSta_CLU "this signal is defined as the warning signal related with battery discharge";
CM_ SG_ 1167 PDC_BatPwrStateClassA "Battery Power State ClassA";
CM_ SG_ 1167 PDC_BatPwrStateClassB "Battery Power State ClassB";
CM_ SG_ 1167 PDC_BatPwrStateClassC "Battery Power State ClassC";
CM_ SG_ 1167 IGN_AutoOff_WarnSta "this signal is defined as the warning signal related with battery discharge";
CM_ BO_ 1171 "[PE] Periodic and On Event";
CM_ SG_ 1171 RLPSM_SWVerMajor1 "First Word(ASCII) in RLPSM S/W Ver";
CM_ SG_ 1171 RLPSM_SWVerMinor2 "Third Word(ASCII) in RLPSM S/W Ver";
CM_ SG_ 1171 RLPSM_SWVerMinor1 "Second Word(ASCII) in RLPSM S/W Ver";
CM_ BO_ 1181 "[EC] On Event and On Change";
CM_ SG_ 1181 RL_SHVU_SeatEcoSta "Rear LH Seat Eco+ Mode Status";
CM_ BO_ 1172 "[PE] Periodic and On Event";
CM_ SG_ 1172 RRPSM_SWVerMajor1 "First Word(ASCII) in RRPSM S/W Ver";
CM_ SG_ 1172 RRPSM_SWVerMinor2 "Third Word(ASCII) in RRPSM S/W Ver";
CM_ SG_ 1172 RRPSM_SWVerMinor1 "Second Word(ASCII) in RRPSM S/W Ver";
CM_ BO_ 1182 "[EC] On Event and On Change";
CM_ SG_ 1182 RR_SHVU_SeatEcoSta "Rear RH Seat Eco+ Mode Status";
CM_ BO_ 208 "[PE] Periodic and On Event";
CM_ SG_ 208 RR_SHVU_DTCdisplay "0x00: DTC is not exist(Fail is not exist)/0x01:IGN2 Fuse Open Detection/0x02:Switch Input Detection at Same Time/0x03:NTC/Heating wire Open Detection/0x04:NTC+/NTC- Terminal Short Detection/0x05:NTC+/Heater+ Terminal Short Detection/0x06:NTC+/Heater-, Heater+/Heater-, Heater+/NTC- Terminal Short Detection/0x07:NTC+/Heater- Wiring Short Detection/0x08:NTC+/Heater-, Heater+/Heater-, Heater+/NTC- Wiring Short Detection/0x09:Target Temperature Dissatisfied/0x0A:Blower+/Blower- Short, Blower+/Blower Speed, Blower-/Blower Speed Wiring Short Detection/0x0B:Blower+/Blower RPM, Blower-/Blower RPM, Blower Speed/Blower RPM Short Detection/0x0C:Blower+, Blower-, Blower Speed Signal open Detection/0x0D:Blower RPM signal Open Detection/0x0E~0xFD:Unused/0xFE:No Display/0xFF:Invalid";
CM_ SG_ 208 RR_SHVU_DiagMode "0x0:Default/0x1:DTC Mode/0x2:Normal Mode/0x3:Invalid";
CM_ BO_ 761 "[PE] Periodic and On Event";
CM_ SG_ 761 SBCM_AST_Crc3Val "SBCM_AST_CyclicRedundancyCheck3Value";
CM_ SG_ 761 SBCM_AST_AlvCnt3Val "SBCM_AST_AliveCounter3Value";
CM_ SG_ 761 Mirror_RHVerPosVal "RH Outside Mirror Vertical Position sensor value";
CM_ SG_ 761 Mirror_RHHorPosVal "RH Outside Mirror Horizontal Position sensor value";
CM_ BO_ 758 "[PE] Periodic and On Event";
CM_ SG_ 758 SBCM_DRV_Crc2Val "SBCM_DRV_CyclicRedundancyCheck2Value";
CM_ SG_ 758 DoorLock_CtrlDrLkUnLkSwSta_SBCM "Central Door Lock/Unlock Switch State";
CM_ SG_ 758 SBCM_DRV_AlvCnt2Val "SBCM_DRV_AliveCounter2Value";
CM_ SG_ 758 ECMMRR_PLUS "ECM Voltage value";
CM_ SG_ 758 Mirror_LHVerPosVal "LH Outside Mirror Vertical Position sensor value";
CM_ SG_ 758 Mirror_LHHorPosVal "LH Outside Mirror Horizontal Position Sensor Voltage";
CM_ BO_ 763 "[PE] Periodic and On Event";
CM_ SG_ 763 SBCM_DRV_Crc3Val "SBCM_DRV_CyclicRedundancyCheck3Value";
CM_ SG_ 763 CDM_TypeOption "CDM_HS_OptionType";
CM_ SG_ 763 SBCM_DRV_AlvCnt3Val "SBCM_DRV_AliveCounter3Value";
CM_ SG_ 763 CDM_ImmeChgSw_SBCM "State of Immediate Charging Switch";
CM_ SG_ 763 CDM_OpnClsState_SBCM "CDM_HS_ OpenCloseState";
CM_ SG_ 763 CDM_WarnMsg_SBCM "CDM_HS_WarningMessage";
CM_ SG_ 763 CDM_CmdStatus_SBCM "CDM_HS_CommandStatus";
CM_ SG_ 763 Hood_TypeOption "E-Hood_Option Type";
CM_ BO_ 742 "[PE] Periodic and On Event";
CM_ SG_ 742 SGU_FltSta "It indicates if SGU is normal or fault";
CM_ SG_ 742 SGU_BlindOnOffSet "It indicates smart glass user setting for roll blind operation.";
CM_ SG_ 742 SGU_BlindOpenReq "Blind Open Command by SGU";
CM_ SG_ 742 SGU_FltVal "It indicates details of SGU fault status";
CM_ SG_ 742 SGU_Roof_OprLv "It indicates tranmittance of Roof Smart Glass";
CM_ SG_ 742 SGU_2ndLeftDoor_OprLv "It indicates tranmittance of 2nd Row Left Door Smart Glass";
CM_ SG_ 742 SGU_2ndRightDoor_OprLv "It indicates transmittance of 2nd Row Right Door Smart Glass";
CM_ SG_ 742 SGU_3rdLeftDoor_OprLv "It Indicates transmittance of 3rd Row Left Door Smart Glass";
CM_ SG_ 742 SGU_3rdRightDoor_OprLv "It Indicates transmittance of 3rd Row Right Door Smart Glass";
CM_ SG_ 742 SGU_RearWindow_OprLv "It indicates transmittance of Rear Window Smart Glass";
CM_ SG_ 742 SGU_OprLvVehicleSet "It indicates Smart Glass Maximum Operation Level Setting Value for each vehicles.";
CM_ SG_ 742 SGU_RdySta "It indicates if SGU is ready or not to operate smart glass";
CM_ BO_ 2328016129 "[P] Periodic";
CM_ SG_ 2328016129 VCU_Crc5Val "VCU_CyclicRedundancyCheck5Value";
CM_ SG_ 2328016129 VCU_AlvCnt5Val "VCU_AliveCounter5Value";
CM_ SG_ 2328016129 VCU_EvDrvRdyCluDispSta "VCU_EvDriveReadyClusterDisplayStatus ##2G##VCU - VCU1 - CF_Vcu_EvRdyClu";
CM_ SG_ 2328016129 VCU_PwrDnModeSta "VCU_PowerDownModeStatus ##2G##VCU - VCU5 - CF_Vcu_PwrDnMode";
CM_ SG_ 2328016129 VCU_CluWarnMsgSta "VCU_ClusterWarningMessageStatus ##2G##VCU - VCU7 - CF_Vcu_WarnMsg";
CM_ SG_ 2328016129 VCU_DteOffDispSta "VCU_DteOffDisplayStatus ##2G##VCU - VCU5 - CF_Vcu_DteOff";
CM_ SG_ 2328016129 VCU_LowSocAlertSta "VCU_LowSocAlertStatus ##2G##VCU - VCU3 - CF_Vcu_LowSocAlert";
CM_ SG_ 2328016129 VCU_VcrmReq "VCU_VcrmRequest ##2G##VCU - VCU3 - CF_Vcu_Vcrm_Req";
CM_ SG_ 2328016129 VCU_PdlWarnMsgSta "VCU_PaddleWarningMassageStatus";
CM_ SG_ 2328016129 VCU_AwdDiagDispSta "VCU_AwdDiagnosisDisplayStatus";
CM_ SG_ 2328016129 VCU_AwdLockDispSta "VCU_AwdLockDisplayStatus";
CM_ SG_ 2328016129 VCU_VirtualApsActSta "VCU_VirtualApsActivatedStatus ##2G##VCU - VCU1 - CF_Vcu_EstApsSel";
CM_ SG_ 2328016129 VCU_VirtualApsVal "VCU_VirtualApsValue ##2G##VCU - VCU1 - CR_Vcu_EstAccPed_PC";
CM_ SG_ 2328016129 VCU_ServiceLampReq "VCU_SeviceLampRequest ##2G##VCU - VCU5 - CF_Vcu_SerLamp";
CM_ SG_ 2328016129 VCU_ServiceModeSta "VCU_ServiceModeStatus ##2G##VCU - VCU2 - CF_Vcu_ServiceMod";
CM_ SG_ 2328016129 VCU_NPosWshModSta "VCU_NPositionWashModeStatus";
CM_ SG_ 2328016129 VCU_PowerTrainType "VCU_PowerTrainType";
CM_ BO_ 2328016130 "[P] Periodic";
CM_ SG_ 2328016130 VCU_DteBaseVal "VCU_DteBaseValue ##2G##VCU - VCU1 - CR_Vcu_DistEmpty_km(VCU6 - CR_Vcu_DistEmpty_km)";
CM_ SG_ 2328016130 VCU_AvnDteOnCalcSta "VCU_AvnDteOnCalculationStatus ##2G##VCU - VCU1 - CF_Vcu_AvnDteCalc(VCU6 - CF_Vcu_AvnDteCalc)";
CM_ SG_ 2328016130 VCU_SbwWarnMsgSta "VCU_SbwWarningMessageStatus ##2G##VCU - VCU20 - CF_Vcu_SbwWarnMsg";
CM_ SG_ 2328016130 VCU_DteNaviRouteVal "VCU_DteNaviRouteValue ##2G##VCU - VCU3 - CR_Vcu_DistEmptyAvn_km";
CM_ SG_ 2328016130 VCU_DteAddVal "VCU_DteAddedValue ##2G##VCU - VCU1 - CR_Vcu_DistEmptyAdd_km(VCU6 - CR_Vcu_DistEmptyAdd_km)";
CM_ SG_ 2328016130 VCU_PwrGaugeVal "VCU_PowerGaugeValue ##2G##VCU - VCU5 - CR_Vcu_TqMotClu_Pc";
CM_ SG_ 2328016130 VCU_EnergyFlowSta "VCU_EnergyFlowStatus ##2G##VCU - VCU5 - CF_Vcu_EvMod";
CM_ SG_ 2328016130 VCU_SbwWarnSndSta "VCU_SbwWarningSoundStatus ##2G##VCU - VCU20 - CF_Vcu_SbwWarnSnd";
CM_ SG_ 2328016130 VCU_EcoGuide_DispReq "VCU_EcoGuide_DisplayRequest ##2G##VCU - VCU7 - CF_Vcu_SmartEcoDisp";
CM_ SG_ 2328016130 VCU_EcoGuide_ApsGaugeVal "VCU_EcoGuide_ApsGaugeValue ##2G##VCU - VCU7 - CR_Vcu_SmartEcoLvl";
CM_ SG_ 2328016130 VCU_EcoGuide_EcoGaugeVal "VCU_EcoGuide_EcoGaugeValue ##2G##VCU - VCU7 - CR_Vcu_SmartEcoRng";
CM_ BO_ 2328016131 "[P] Periodic";
CM_ SG_ 2328016131 VCU_TgSocDteAcChgVal "VCU_TargetSocDte(Sc/Ac)ChargerValue ##2G##VCU - VCU19 - CR_Vcu_TgSocDte_AcChg";
CM_ SG_ 2328016131 VCU_TgSocDteDcChgVal "VCU_TargetSocDte(Qc/Dc)ChargerValue ##2G##VCU - VCU19 - CR_Vcu_TgSocDte_DcChg";
CM_ SG_ 2328016131 VCU_DistFromRegenDispReq "VCU_DistanceFromRegenerationDisplayRequest ##2G##VCU - VCU7 - CR_Vcu_RegenRangeAddSet";
CM_ SG_ 2328016131 VCU_DistFromRegenVal "VCU_DistanceFromRegenerationValue ##2G##VCU - VCU7 - CR_Vcu_RegenRangeAdd";
CM_ SG_ 2328016131 VCU_DrvStyle_DispReq "VCU_DriveStyle_DisplayRequest ##2G##VCU - VCU7 - CF_Vcu_FueEffStat";
CM_ SG_ 2328016131 VCU_DrvStyle_HighLightSta "VCU_DriveStyle_HighLightStatus ##2G##VCU - VCU7 - CF_Vcu_FueEffStatBox";
CM_ SG_ 2328016131 VCU_DrvStyle_EcoVal "VCU_DriveStyle_EcoValue ##2G##VCU - VCU7 - CR_Vcu_HighFueEff_Pc";
CM_ SG_ 2328016131 VCU_DrvStyle_NonEcoVal "VCU_DriveStyle_NonEcoValue ##2G##VCU - VCU7 - CR_Vcu_LowFueEff_Pc";
CM_ SG_ 2328016131 VCU_DrvStyle_NorVal "VCU_DriveStyle_NorValue ##2G##VCU - VCU7 - CR_Vcu_NorFueEff_Pc";
BA_DEF_ BO_ "DiagState" ENUM "No","Yes" ;
BA_DEF_ BO_ "DiagResponse" ENUM "No","Yes" ;
BA_DEF_ BO_ "DiagRequest" ENUM "No","Yes" ;
BA_DEF_ BO_ "TpMessage" ENUM "No","Yes" ;
BA_DEF_ BO_ "UsrMsgIDSforwardDeviation" INT 0 100 ;
BA_DEF_ BO_ "UsrMsgIDSbackwardDeviation" INT 50 1000 ;
BA_DEF_ BO_ "GenMsgCycleTime" INT 0 2000 ;
BA_DEF_ BO_ "GenMsgStartDelayTime" INT 0 2000 ;
BA_DEF_ BO_ "GenMsgSendType" ENUM "Cyclic","NoMsgSendType" ;
BA_DEF_ BO_ "GenMsgCycleTimeFast" INT 0 500 ;
BA_DEF_ BO_ "GenMsgDelayTime" INT 0 20 ;
BA_DEF_ BO_ "GenMsgILSupport" ENUM "No","Yes" ;
BA_DEF_ BO_ "GenMsgNrOfRepetition" INT 0 3 ;
BA_DEF_ BO_ "NmMessage" ENUM "No","Yes" ;
BA_DEF_ BO_ "NWM-Botschaft" ENUM "No","Yes" ;
BA_DEF_ BO_ "TpTxIndex" INT 0 255 ;
BA_DEF_ BO_ "VFrameFormat" ENUM "StandardCAN","ExtendedCAN","reserved","reserved","reserved","reserved","reserved","reserved","reserved","reserved","reserved","reserved","reserved","reserved","StandardCAN_FD","ExtendedCAN_FD" ;
BA_DEF_ SG_ "UserSigValidity" ENUM "B+","ACC","IG","IG1","IG2","IG3","IG1 or IG2","IG1 or IG3","Undef" ;
BA_DEF_ SG_ "TimeoutValue" STRING ;
BA_DEF_ SG_ "UsrSigPurpose" ENUM "Undef","FN","DIAG","DIAG(Req)","DIAG(Res)","DIAG(Phy)","DEV","CCP(Req)","CCP(Res)","NM","TP" ;
BA_DEF_ SG_ "GenSigStartValue" INT 0 1215752192 ;
BA_DEF_ SG_ "NetworkRequest" ENUM "Yes","No" ;
BA_DEF_ SG_ "NetworkRequestHoldingTime" INT 0 65535 ;
BA_DEF_ SG_ "Description" STRING ;
BA_DEF_ SG_ "Version" STRING ;
BA_DEF_ SG_ "GenSigEnvVarType" ENUM "Int","Float","Undef" ;
BA_DEF_ SG_ "GenSigSendType" ENUM "Cyclic","OnWrite","OnWriteWithRepetition","OnChange","OnChangeWithRepetition","IfActive","IfActiveWithRepetition","NoSigSendType","OnChangeAndIfActive","OnChangeAndIfActiveWithRepetition" ;
BA_DEF_ SG_ "GwSigLatencyTime" INT 0 65536 ;
BA_DEF_ SG_ "GwSigMissingSourceType" ENUM "Undef","OldValue","DefaultValue","InitialValue" ;
BA_DEF_ SG_ "NWM-WakeupAllowed" ENUM "<n.a.>" ;
BA_DEF_ SG_ "RoutingFactor" INT 1 1215752192 ;
BA_DEF_REL_ BU_SG_REL_ "GenSigTimeoutTime" INT 0 7000 ;
BA_DEF_DEF_ "DiagState" "No" ;
BA_DEF_DEF_ "DiagResponse" "No" ;
BA_DEF_DEF_ "DiagRequest" "No" ;
BA_DEF_DEF_ "TpMessage" "No" ;
BA_DEF_DEF_ "UsrMsgIDSforwardDeviation" 10 ;
BA_DEF_DEF_ "UsrMsgIDSbackwardDeviation" 100 ;
BA_DEF_DEF_ "GenMsgCycleTime" 200 ;
BA_DEF_DEF_ "GenMsgStartDelayTime" 0 ;
BA_DEF_DEF_ "GenMsgSendType" "NoMsgSendType" ;
BA_DEF_DEF_ "GenMsgCycleTimeFast" 40 ;
BA_DEF_DEF_ "GenMsgDelayTime" 20 ;
BA_DEF_DEF_ "GenMsgILSupport" "Yes" ;
BA_DEF_DEF_ "GenMsgNrOfRepetition" 3 ;
BA_DEF_DEF_ "NmMessage" "No" ;
BA_DEF_DEF_ "NWM-Botschaft" "No" ;
BA_DEF_DEF_ "TpTxIndex" 0 ;
BA_DEF_DEF_ "VFrameFormat" "StandardCAN" ;
BA_DEF_DEF_ "UserSigValidity" "IG" ;
BA_DEF_DEF_ "TimeoutValue" "" ;
BA_DEF_DEF_ "UsrSigPurpose" "FN" ;
BA_DEF_DEF_ "GenSigStartValue" 0 ;
BA_DEF_DEF_ "NetworkRequest" "No" ;
BA_DEF_DEF_ "NetworkRequestHoldingTime" 0 ;
BA_DEF_DEF_ "Description" "" ;
BA_DEF_DEF_ "Version" "" ;
BA_DEF_DEF_ "GenSigEnvVarType" "Undef" ;
BA_DEF_DEF_ "GenSigSendType" "NoSigSendType" ;
BA_DEF_DEF_ "GwSigLatencyTime" 40 ;
BA_DEF_DEF_ "GwSigMissingSourceType" "Undef" ;
BA_DEF_DEF_ "NWM-WakeupAllowed" "<n.a.>" ;
BA_DEF_DEF_ "RoutingFactor" 1 ;
BA_DEF_DEF_REL_ "GenSigTimeoutTime" 500 ;
BA_ "GenMsgCycleTime" BO_ 223 0;
BA_ "Description" SG_ 223 ALBCU_SmartCtrl_1h "Smart Posture Adjust AVN Display (1hr)";
BA_ "GenSigSendType" SG_ 223 ALBCU_SmartCtrl_1h 4;
BA_ "UserSigValidity" SG_ 223 ALBCU_SmartCtrl_1h 1;
BA_REL_ "GenSigTimeoutTime" BU_SG_REL_ CGW_CCU SG_ 223 ALBCU_SmartCtrl_1h 0;
BA_ "RoutingFactor" SG_ 223 ALBCU_SmartCtrl_1h 0;
BA_ "Version" SG_ 223 ALBCU_SmartCtrl_1h "20.10.02";
BA_ "Description" SG_ 223 ALBCU_SmartCtrl_2h "Smart Posture Adjust AVN Display (2hr)";
BA_ "GenSigSendType" SG_ 223 ALBCU_SmartCtrl_2h 4;
BA_ "UserSigValidity" SG_ 223 ALBCU_SmartCtrl_2h 1;
BA_REL_ "GenSigTimeoutTime" BU_SG_REL_ CGW_CCU SG_ 223 ALBCU_SmartCtrl_2h 0;
BA_ "RoutingFactor" SG_ 223 ALBCU_SmartCtrl_2h 0;
BA_ "Version" SG_ 223 ALBCU_SmartCtrl_2h "20.10.02";
BA_ "Description" SG_ 223 ALBCU_SmartCtrl_Status "Smart Posture Adjust 2nd Interlocked Move AVN popup request";
BA_ "GenSigSendType" SG_ 223 ALBCU_SmartCtrl_Status 4;
BA_ "UserSigValidity" SG_ 223 ALBCU_SmartCtrl_Status 1;
BA_REL_ "GenSigTimeoutTime" BU_SG_REL_ CGW_CCU SG_ 223 ALBCU_SmartCtrl_Status 0;
BA_ "RoutingFactor" SG_ 223 ALBCU_SmartCtrl_Status 0;
BA_ "Version" SG_ 223 ALBCU_SmartCtrl_Status "20.10.02";
BA_ "GenMsgCycleTime" BO_ 1180 0;
BA_ "Description" SG_ 1180 SHVU_Ast_Beep1Sound "Play touch beep sound one time

Beep sound on/off

Default : Off

Goes On when play beep sound";
BA_ "GenSigSendType" SG_ 1180 SHVU_Ast_Beep1Sound 4;
BA_ "UserSigValidity" SG_ 1180 SHVU_Ast_Beep1Sound 3;
BA_REL_ "GenSigTimeoutTime" BU_SG_REL_ CGW_CCU SG_ 1180 SHVU_Ast_Beep1Sound 0;
BA_ "Version" SG_ 1180 SHVU_Ast_Beep1Sound "20.01.02";
BA_ "Description" SG_ 1180 Ast_SHVU_SeatEcoSta "Ast ½ÃÆ® ¿¡ÄÚÇÃ·¯½º ¸ðµå ÁøÀÔ Á¤º¸";
BA_ "GenSigSendType" SG_ 1180 Ast_SHVU_SeatEcoSta 4;
BA_ "UserSigValidity" SG_ 1180 Ast_SHVU_SeatEcoSta 3;
BA_REL_ "GenSigTimeoutTime" BU_SG_REL_ CGW_CCU SG_ 1180 Ast_SHVU_SeatEcoSta 0;
BA_ "NetworkRequest" SG_ 1180 Ast_SHVU_SeatEcoSta 0;
BA_ "NetworkRequestHoldingTime" SG_ 1180 Ast_SHVU_SeatEcoSta 5000;
BA_ "Version" SG_ 1180 Ast_SHVU_SeatEcoSta "20.01.01";
BA_ "GenMsgSendType" BO_ 2315421697 0;
BA_ "VFrameFormat" BO_ 2315421697 1;
BA_ "Description" SG_ 2315421697 CCU_AP_OTA_Crc1Val "The data area for CRC calculation is based on the data length (DLC) of the message DB.

The CRC shall be calculated over the entire data block (excluding the CRC bytes) including the user data, alive counter and Data ID

 

- CRC Polynomial (0x1021) , Initial Value : 0xFFFF, XOR value : 0x0000, Data ID : Message ID + 0xF800 

- The initial value is for CRC calculation and the message should be sent with the calculated result value. 

- The mathematical expression to 16 bit CRC polynomial is given here. G(x) = x16 + x12 + x5 + 1";
BA_ "GenSigSendType" SG_ 2315421697 CCU_AP_OTA_Crc1Val 4;
BA_ "GenSigStartValue" SG_ 2315421697 CCU_AP_OTA_Crc1Val 65535;
BA_ "UserSigValidity" SG_ 2315421697 CCU_AP_OTA_Crc1Val 3;
BA_REL_ "GenSigTimeoutTime" BU_SG_REL_ vDummy_HS_B SG_ 2315421697 CCU_AP_OTA_Crc1Val 1500;
BA_ "Version" SG_ 2315421697 CCU_AP_OTA_Crc1Val "19.12.02";
BA_ "Description" SG_ 2315421697 CCU_AP_OTA_AlvCnt1Val "For the first transmission request for a data element the counter shall be initialized with 0 and shall be incremented by 1 for every subsequent send request. 

When the counter reaches the maximum value(0xFF), then it shall restart with 0 for the next send request";
BA_ "GenSigSendType" SG_ 2315421697 CCU_AP_OTA_AlvCnt1Val 4;
BA_ "UserSigValidity" SG_ 2315421697 CCU_AP_OTA_AlvCnt1Val 3;
BA_REL_ "GenSigTimeoutTime" BU_SG_REL_ vDummy_HS_B SG_ 2315421697 CCU_AP_OTA_AlvCnt1Val 1500;
BA_ "Version" SG_ 2315421697 CCU_AP_OTA_AlvCnt1Val "19.12.02";
BA_ "GenSigSendType" SG_ 2315421697 CCU_OTA_mode 4;
BA_ "UserSigValidity" SG_ 2315421697 CCU_OTA_mode 0;
BA_ "Version" SG_ 2315421697 CCU_OTA_mode "20.01.01";
BA_ "GenSigSendType" SG_ 2315421697 CCU_OTA_IG3On_request 4;
BA_ "UserSigValidity" SG_ 2315421697 CCU_OTA_IG3On_request 0;
BA_ "Version" SG_ 2315421697 CCU_OTA_IG3On_request "20.01.02";
BA_ "GenSigSendType" SG_ 2315421697 OTA_Cond_Vehicle_Pwr 4;
BA_ "GenSigStartValue" SG_ 2315421697 OTA_Cond_Vehicle_Pwr 1;
BA_ "UserSigValidity" SG_ 2315421697 OTA_Cond_Vehicle_Pwr 0;
BA_ "Version" SG_ 2315421697 OTA_Cond_Vehicle_Pwr "20.11.03";
BA_ "GenSigSendType" SG_ 2315421697 OTA_Cond_Gear_P 4;
BA_ "GenSigStartValue" SG_ 2315421697 OTA_Cond_Gear_P 1;
BA_ "UserSigValidity" SG_ 2315421697 OTA_Cond_Gear_P 0;
BA_ "Version" SG_ 2315421697 OTA_Cond_Gear_P "20.11.03";
BA_ "GenSigSendType" SG_ 2315421697 OTA_Cond_Parking_Brk 4;
BA_ "GenSigStartValue" SG_ 2315421697 OTA_Cond_Parking_Brk 1;
BA_ "UserSigValidity" SG_ 2315421697 OTA_Cond_Parking_Brk 0;
BA_ "Version" SG_ 2315421697 OTA_Cond_Parking_Brk "20.11.03";
BA_ "GenSigSendType" SG_ 2315421697 OTA_Cond_Ext_Lamp 4;
BA_ "GenSigStartValue" SG_ 2315421697 OTA_Cond_Ext_Lamp 1;
BA_ "UserSigValidity" SG_ 2315421697 OTA_Cond_Ext_Lamp 0;
BA_ "Version" SG_ 2315421697 OTA_Cond_Ext_Lamp "20.11.03";
BA_ "GenSigSendType" SG_ 2315421697 OTA_Cond_Hood_Closed 4;
BA_ "GenSigStartValue" SG_ 2315421697 OTA_Cond_Hood_Closed 1;
BA_ "UserSigValidity" SG_ 2315421697 OTA_Cond_Hood_Closed 0;
BA_ "Version" SG_ 2315421697 OTA_Cond_Hood_Closed "20.11.03";
BA_ "GenSigSendType" SG_ 2315421697 CCU_OTA_Tele_Cranking 4;
BA_ "UserSigValidity" SG_ 2315421697 CCU_OTA_Tele_Cranking 0;
BA_ "NetworkRequest" SG_ 2315421697 CCU_OTA_Tele_Cranking 0;
BA_ "NetworkRequestHoldingTime" SG_ 2315421697 CCU_OTA_Tele_Cranking 2000;
BA_ "Version" SG_ 2315421697 CCU_OTA_Tele_Cranking "22.02.02";
BA_ "Description" SG_ 2315421697 OTA_UI_Ready_request "OTA User Approval Popup Request Signal (to ccIC)";
BA_ "GenSigSendType" SG_ 2315421697 OTA_UI_Ready_request 4;
BA_ "UserSigValidity" SG_ 2315421697 OTA_UI_Ready_request 0;
BA_ "Version" SG_ 2315421697 OTA_UI_Ready_request "21.04.00";
BA_ "GenSigSendType" SG_ 2315421697 OTA_Result 4;
BA_ "UserSigValidity" SG_ 2315421697 OTA_Result 0;
BA_ "Version" SG_ 2315421697 OTA_Result "21.02.02";
BA_ "GenSigSendType" SG_ 2315421697 CF_AVN_InterAutoLockMode_Set2_Copy_1 4;
BA_ "UserSigValidity" SG_ 2315421697 CF_AVN_InterAutoLockMode_Set2_Copy_1 3;
BA_ "Version" SG_ 2315421697 CF_AVN_InterAutoLockMode_Set2_Copy_1 "20.09.00";
BA_ "GenSigSendType" SG_ 2315421697 CCU_OTA_EOU 4;
BA_ "UserSigValidity" SG_ 2315421697 CCU_OTA_EOU 0;
BA_ "Version" SG_ 2315421697 CCU_OTA_EOU "20.09.00";
BA_ "GenMsgSendType" BO_ 2290230529 0;
BA_ "GenMsgCycleTimeFast" BO_ 2290230529 0;
BA_ "GenMsgNrOfRepetition" BO_ 2290230529 0;
BA_ "VFrameFormat" BO_ 2290230529 1;
BA_ "Description" SG_ 2290230529 CLU_Crc2Val "The data area for CRC calculation is based on the data length (DLC) of the message DB.

The CRC shall be calculated over the entire data block (excluding the CRC bytes) including the user data, alive counter and Data ID

 

- CRC Polynomial (0x1021) , Initial Value : 0xFFFF, XOR value : 0x0000, Data ID : Message ID + 0xF800 

- The initial value is for CRC calculation and the message should be sent with the calculated result value. 

- The mathematical expression to 16 bit CRC polynomial is given here. G(x) = x16 + x12 + x5 + 1";
BA_ "GenSigStartValue" SG_ 2290230529 CLU_Crc2Val 65535;
BA_ "UserSigValidity" SG_ 2290230529 CLU_Crc2Val 3;
BA_ "RoutingFactor" SG_ 2290230529 CLU_Crc2Val 2;
BA_ "Version" SG_ 2290230529 CLU_Crc2Val "18.11.08";
BA_ "Description" SG_ 2290230529 CLU_AlvCnt2Val "For the first transmission request for a data element the counter shall be initialized with 0 and shall be incremented by 1 for every subsequent send request. 

When the counter reaches the maximum value(0xFF), then it shall restart with 0 for the next send request";
BA_ "UserSigValidity" SG_ 2290230529 CLU_AlvCnt2Val 3;
BA_ "RoutingFactor" SG_ 2290230529 CLU_AlvCnt2Val 2;
BA_ "Version" SG_ 2290230529 CLU_AlvCnt2Val "18.11.08";
BA_ "Description" SG_ 2290230529 CLU_DTEVal "This signal indicates DTE.

0x0: Valid DTE 0 (Display '---')

0x1~0xFFE: Valid DTE (1 ~ 4094 km)

(DTE >4094 km : 0xFFE)

0xFFF : Invalid(Display '---' Blink)";
BA_ "UserSigValidity" SG_ 2290230529 CLU_DTEVal 3;
BA_ "RoutingFactor" SG_ 2290230529 CLU_DTEVal 2;
BA_ "Version" SG_ 2290230529 CLU_DTEVal "19.02.07";
BA_ "Description" SG_ 2290230529 CLU_TripUnitSta "This signal indicates Distance to Empty UNIT";
BA_ "UserSigValidity" SG_ 2290230529 CLU_TripUnitSta 3;
BA_ "RoutingFactor" SG_ 2290230529 CLU_TripUnitSta 2;
BA_ "Version" SG_ 2290230529 CLU_TripUnitSta "17.11.00";
BA_ "Description" SG_ 2290230529 CLU_LoFuelWrngSta "This signal indicates that the Low fuel warning in the cluster is On or Off. When Low Fuel Warning is On, its value is 01H otherwise its value is 00H.";
BA_ "UserSigValidity" SG_ 2290230529 CLU_LoFuelWrngSta 3;
BA_ "RoutingFactor" SG_ 2290230529 CLU_LoFuelWrngSta 2;
BA_ "Version" SG_ 2290230529 CLU_LoFuelWrngSta "17.11.00";
BA_ "Description" SG_ 2290230529 CLU_RefuelDetSta "This signal sends the refuel detected status to the tele-matics control unit. 

It transfers 3 times during refuel detected event why if valid one is missing, valid signals are used for extra signal.";
BA_ "UserSigValidity" SG_ 2290230529 CLU_RefuelDetSta 3;
BA_ "RoutingFactor" SG_ 2290230529 CLU_RefuelDetSta 2;
BA_ "Version" SG_ 2290230529 CLU_RefuelDetSta "17.11.00";
BA_ "Description" SG_ 2290230529 CLU_TerrainMainSwSta "This signal represents the terrain mode main switch's state.

0x1:On-Road /0x2:Off-Road";
BA_ "UserSigValidity" SG_ 2290230529 CLU_TerrainMainSwSta 3;
BA_ "RoutingFactor" SG_ 2290230529 CLU_TerrainMainSwSta 2;
BA_ "Version" SG_ 2290230529 CLU_TerrainMainSwSta "18.04.00";
BA_ "GenMsgSendType" BO_ 2290230530 0;
BA_ "GenMsgCycleTimeFast" BO_ 2290230530 0;
BA_ "GenMsgNrOfRepetition" BO_ 2290230530 0;
BA_ "VFrameFormat" BO_ 2290230530 1;
BA_ "Description" SG_ 2290230530 CLU_LngSta "Language Info. for Display Font";
BA_ "UserSigValidity" SG_ 2290230530 CLU_LngSta 3;
BA_ "RoutingFactor" SG_ 2290230530 CLU_LngSta 2;
BA_ "Version" SG_ 2290230530 CLU_LngSta "17.11.00";
BA_ "Description" SG_ 2290230530 CLU_RefuelWrnSta "This signal indicates that the Refuel popup is the cluster is On or Off.

When Refuel popup is on, its value is 0x1 otherwise its value is 0x0.";
BA_ "UserSigValidity" SG_ 2290230530 CLU_RefuelWrnSta 3;
BA_ "RoutingFactor" SG_ 2290230530 CLU_RefuelWrnSta 2;
BA_ "Version" SG_ 2290230530 CLU_RefuelWrnSta "17.11.00";
BA_ "Description" SG_ 2290230530 CLU_IceWrnIndSta "This signal indicates that the Ice warning indicator in the cluster is on or off.

When Ice warning indicator is on, its value is 0x1 otherwise its value is 0x0.";
BA_ "UserSigValidity" SG_ 2290230530 CLU_IceWrnIndSta 3;
BA_ "RoutingFactor" SG_ 2290230530 CLU_IceWrnIndSta 2;
BA_ "Version" SG_ 2290230530 CLU_IceWrnIndSta "17.11.00";
BA_ "Description" SG_ 2290230530 CLU_DrvngModSwSta "This signal occurs when drive mode switch is selected either 'Normal' or 'Eco' or 'Sport' or 'Sport+' or 'Smart' or 'Custom' or 'N-mode'.";
BA_ "UserSigValidity" SG_ 2290230530 CLU_DrvngModSwSta 3;
BA_REL_ "GenSigTimeoutTime" BU_SG_REL_ SWRC SG_ 2290230530 CLU_DrvngModSwSta 1500;
BA_ "RoutingFactor" SG_ 2290230530 CLU_DrvngModSwSta 2;
BA_ "Version" SG_ 2290230530 CLU_DrvngModSwSta "20.04.02";
BA_ "Description" SG_ 2290230530 CLU_FuelLvlSta "The signal is fuel level of the cluster that fuel gauge indicate (Unit: %)";
BA_ "UserSigValidity" SG_ 2290230530 CLU_FuelLvlSta 3;
BA_ "RoutingFactor" SG_ 2290230530 CLU_FuelLvlSta 2;
BA_ "Version" SG_ 2290230530 CLU_FuelLvlSta "17.12.03";
BA_ "Description" SG_ 2290230530 CLU_SRSWrngLmpSta "This signal is generated by one of the following 5 self-diagnostic result of micro-controller of Cluster.

1) ¡°Lamp ON¡± status as a self-status diagnostic result of cluster

2) ¡°Lamp OFF¡± status as a self-status diagnostic result of cluster

3) ¡°Lamp flashing with 1hz frequency / 50% duty ratio¡± as a self-status result diagnostic result of cluster

4) ¡°Lamp Circuit Failure¡± as a self-diagnostic result of cluster circuit 

5) ¡°No Valid ACU message¡± as ACU4 message check result by cluster



Note to be taken that CLU2 message does not include judgment on ¡°SRS W/Lamp failure in terms of airbag system¡±. CLU2 message only contains ¡°status and diagnostic result of Cluster itself¡±.";
BA_ "UserSigValidity" SG_ 2290230530 CLU_SRSWrngLmpSta 3;
BA_ "RoutingFactor" SG_ 2290230530 CLU_SRSWrngLmpSta 2;
BA_ "Version" SG_ 2290230530 CLU_SRSWrngLmpSta "17.12.03";
BA_ "Description" SG_ 2290230530 CLU_TerrainModSwSta "This signal occurs when terrain mode switch is selected either 'Snow' or 'Sand' or 'Mud' or 'Auto'.";
BA_ "UserSigValidity" SG_ 2290230530 CLU_TerrainModSwSta 3;
BA_REL_ "GenSigTimeoutTime" BU_SG_REL_ SWRC SG_ 2290230530 CLU_TerrainModSwSta 1500;
BA_ "RoutingFactor" SG_ 2290230530 CLU_TerrainModSwSta 2;
BA_ "Version" SG_ 2290230530 CLU_TerrainModSwSta "20.09.00";
BA_ "Description" SG_ 2290230530 CLU_OdoVal "This signal indicates mileage counter of a vehicle. Cluster calculates total mileage and sends it to SCC and CUBIS. This value shall be the same with the mileage that is displayed to a driver.";
BA_ "UserSigValidity" SG_ 2290230530 CLU_OdoVal 3;
BA_ "RoutingFactor" SG_ 2290230530 CLU_OdoVal 2;
BA_ "Version" SG_ 2290230530 CLU_OdoVal "17.11.00";
BA_ "GenMsgCycleTime" BO_ 2470763009 0;
BA_ "VFrameFormat" BO_ 2470763009 1;
BA_ "Description" SG_ 2470763009 CLU_Crc9Val "The data area for CRC calculation is based on the data length (DLC) of the message DB.

The CRC shall be calculated over the entire data block (excluding the CRC bytes) including the user data, alive counter and Data ID

 

- CRC Polynomial (0x1021) , Initial Value : 0xFFFF, XOR value : 0x0000, Data ID : Message ID + 0xF800 

- The initial value is for CRC calculation and the message should be sent with the calculated result value. 

- The mathematical expression to 16 bit CRC polynomial is given here. G(x) = x16 + x12 + x5 + 1";
BA_ "GenSigSendType" SG_ 2470763009 CLU_Crc9Val 4;
BA_ "GenSigStartValue" SG_ 2470763009 CLU_Crc9Val 65535;
BA_ "UserSigValidity" SG_ 2470763009 CLU_Crc9Val 3;
BA_ "Version" SG_ 2470763009 CLU_Crc9Val "18.11.08";
BA_ "Description" SG_ 2470763009 CLU_AlvCnt9Val "For the first transmission request for a data element the counter shall be initialized with 0 and shall be incremented by 1 for every subsequent send request. 

When the counter reaches the maximum value(0xFF), then it shall restart with 0 for the next send request";
BA_ "GenSigSendType" SG_ 2470763009 CLU_AlvCnt9Val 4;
BA_ "UserSigValidity" SG_ 2470763009 CLU_AlvCnt9Val 3;
BA_ "Version" SG_ 2470763009 CLU_AlvCnt9Val "18.11.08";
BA_ "Description" SG_ 2470763009 USM_MdLmpClrSetReq "Request set the Mood Lamp Color";
BA_ "GenSigSendType" SG_ 2470763009 USM_MdLmpClrSetReq 4;
BA_ "UserSigValidity" SG_ 2470763009 USM_MdLmpClrSetReq 3;
BA_ "Version" SG_ 2470763009 USM_MdLmpClrSetReq "20.08.06";
BA_ "Description" SG_ 2470763009 USM_RrWiperRevSetReq "Request to set RearWiper Reverse Mode";
BA_ "GenSigSendType" SG_ 2470763009 USM_RrWiperRevSetReq 4;
BA_ "UserSigValidity" SG_ 2470763009 USM_RrWiperRevSetReq 3;
BA_ "Version" SG_ 2470763009 USM_RrWiperRevSetReq "17.11.00";
BA_ "Description" SG_ 2470763009 USM_RrStRemindSetReq "USM Function for RearSeatReminder on/off SW";
BA_ "GenSigSendType" SG_ 2470763009 USM_RrStRemindSetReq 4;
BA_ "UserSigValidity" SG_ 2470763009 USM_RrStRemindSetReq 3;
BA_ "Version" SG_ 2470763009 USM_RrStRemindSetReq "19.01.04";
BA_ "Description" SG_ 2470763009 USM_RrWpcSetReq "USM Function for REAR WPC(Wireless Phone Chager) on/off SW";
BA_ "GenSigSendType" SG_ 2470763009 USM_RrWpcSetReq 4;
BA_ "UserSigValidity" SG_ 2470763009 USM_RrWpcSetReq 3;
BA_ "Version" SG_ 2470763009 USM_RrWpcSetReq "17.11.00";
BA_ "Description" SG_ 2470763009 USM_WpcSetReq "USM Function for WPC(Wireless Phone Chager) on/off SW";
BA_ "GenSigSendType" SG_ 2470763009 USM_WpcSetReq 4;
BA_ "UserSigValidity" SG_ 2470763009 USM_WpcSetReq 3;
BA_REL_ "GenSigTimeoutTime" BU_SG_REL_ WPC SG_ 2470763009 USM_WpcSetReq 0;
BA_REL_ "GenSigTimeoutTime" BU_SG_REL_ WPC2 SG_ 2470763009 USM_WpcSetReq 0;
BA_ "Version" SG_ 2470763009 USM_WpcSetReq "17.11.00";
BA_ "Description" SG_ 2470763009 USM_SeqLmpSetReq "This signal is used for a request to set the value of USM Menus. This signal requests to change status of SequencialLamp ON/OFF setting.





When this signal change, the message (CLU18) is sent 3 times.";
BA_ "GenSigSendType" SG_ 2470763009 USM_SeqLmpSetReq 4;
BA_ "UserSigValidity" SG_ 2470763009 USM_SeqLmpSetReq 3;
BA_ "Version" SG_ 2470763009 USM_SeqLmpSetReq "17.11.00";
BA_ "Description" SG_ 2470763009 USM_UnlckWlcmSetReq "This signal is used for a request to set the value of USM Menus. This signal requests to change status of Welcome System setting.





When this signal change, the message (CLU18) is sent 3 times.";
BA_ "GenSigSendType" SG_ 2470763009 USM_UnlckWlcmSetReq 4;
BA_ "UserSigValidity" SG_ 2470763009 USM_UnlckWlcmSetReq 3;
BA_ "Version" SG_ 2470763009 USM_UnlckWlcmSetReq "17.11.00";
BA_ "Description" SG_ 2470763009 USM_SmrtWlcmSetReq "This signal is used for a request to set the value of USM Menus. This signal requests to change status of Welcome System setting.





When this signal change, the message (CLU18) is sent 3 times.";
BA_ "GenSigSendType" SG_ 2470763009 USM_SmrtWlcmSetReq 4;
BA_ "UserSigValidity" SG_ 2470763009 USM_SmrtWlcmSetReq 3;
BA_ "Version" SG_ 2470763009 USM_SmrtWlcmSetReq "17.11.00";
BA_ "Description" SG_ 2470763009 USM_UipSetReq "Request to set Uip(Ultrasonic Intrusion Protection)

This signal is used for a request to set the value of USM Menus. 

When this signal change, the message is sent 3 times.";
BA_ "GenSigSendType" SG_ 2470763009 USM_UipSetReq 4;
BA_ "UserSigValidity" SG_ 2470763009 USM_UipSetReq 3;
BA_ "Version" SG_ 2470763009 USM_UipSetReq "18.11.07";
BA_ "Description" SG_ 2470763009 USM_DigitalKeyEnblSetReq "This signal is used for a request to set the value of USM Menus. This signal requests to set Digital Key On/Off.";
BA_ "GenSigSendType" SG_ 2470763009 USM_DigitalKeyEnblSetReq 4;
BA_ "UserSigValidity" SG_ 2470763009 USM_DigitalKeyEnblSetReq 3;
BA_ "Version" SG_ 2470763009 USM_DigitalKeyEnblSetReq "18.11.00";
BA_ "Description" SG_ 2470763009 USM_OwnerPhnRegSetReq "This signal is used for a request to set the value of USM Menus.

This signal requests to set Digital Key On/Off";
BA_ "GenSigSendType" SG_ 2470763009 USM_OwnerPhnRegSetReq 4;
BA_ "UserSigValidity" SG_ 2470763009 USM_OwnerPhnRegSetReq 3;
BA_ "Version" SG_ 2470763009 USM_OwnerPhnRegSetReq "18.11.00";
BA_ "Description" SG_ 2470763009 USM_NFCCard1RegSetReq "This signal is used for a request to set the value of USM Menus. This signal requests to go through the process for NFC Card 1 recoding.";
BA_ "GenSigSendType" SG_ 2470763009 USM_NFCCard1RegSetReq 4;
BA_ "UserSigValidity" SG_ 2470763009 USM_NFCCard1RegSetReq 3;
BA_ "Version" SG_ 2470763009 USM_NFCCard1RegSetReq "18.11.00";
BA_ "Description" SG_ 2470763009 USM_NFCCard2RegSetReq "This signal is used for arequest to set the value of usm menus.

This signal requests to go through the process NFC Card 2 recording";
BA_ "GenSigSendType" SG_ 2470763009 USM_NFCCard2RegSetReq 4;
BA_ "UserSigValidity" SG_ 2470763009 USM_NFCCard2RegSetReq 3;
BA_ "Version" SG_ 2470763009 USM_NFCCard2RegSetReq "18.11.00";
BA_ "Description" SG_ 2470763009 USM_ProcStpReq "This signal is used for a request to escape the IAU Authorizaton processing";
BA_ "GenSigSendType" SG_ 2470763009 USM_ProcStpReq 4;
BA_ "UserSigValidity" SG_ 2470763009 USM_ProcStpReq 3;
BA_ "Version" SG_ 2470763009 USM_ProcStpReq "18.11.00";
BA_ "Description" SG_ 2470763009 USM_PwrAutoOffTimeSetReq "This signal is used for a request to set the value of USM Menus. This signal requests to change status of Power auto off time setting.";
BA_ "GenSigSendType" SG_ 2470763009 USM_PwrAutoOffTimeSetReq 4;
BA_ "UserSigValidity" SG_ 2470763009 USM_PwrAutoOffTimeSetReq 3;
BA_ "Version" SG_ 2470763009 USM_PwrAutoOffTimeSetReq "18.12.02";
BA_ "Description" SG_ 2470763009 USM_RrStRemindSetReq_RestMode "This is a signal for Rear Seat remind USM 

Request to set  Restmod of Rear Seat remind";
BA_ "GenSigSendType" SG_ 2470763009 USM_RrStRemindSetReq_RestMode 4;
BA_ "UserSigValidity" SG_ 2470763009 USM_RrStRemindSetReq_RestMode 3;
BA_ "Version" SG_ 2470763009 USM_RrStRemindSetReq_RestMode "19.09.04";
BA_ "Description" SG_ 2470763009 USM_1stRrStRemindSetReq "USM Function for RearSeatReminder on/off SW for IBU only Type";
BA_ "GenSigSendType" SG_ 2470763009 USM_1stRrStRemindSetReq 4;
BA_ "UserSigValidity" SG_ 2470763009 USM_1stRrStRemindSetReq 3;
BA_ "Version" SG_ 2470763009 USM_1stRrStRemindSetReq "20.02.06";
BA_ "Description" SG_ 2470763009 USM_Wpc2SetReq "USM Function for WPC(Wireless Phone Chager) on/off SW";
BA_ "GenSigSendType" SG_ 2470763009 USM_Wpc2SetReq 4;
BA_ "UserSigValidity" SG_ 2470763009 USM_Wpc2SetReq 3;
BA_REL_ "GenSigTimeoutTime" BU_SG_REL_ WPC2 SG_ 2470763009 USM_Wpc2SetReq 0;
BA_ "Version" SG_ 2470763009 USM_Wpc2SetReq "22.02.06";
BA_ "GenMsgSendType" BO_ 2382595073 0;
BA_ "VFrameFormat" BO_ 2382595073 1;
BA_ "Description" SG_ 2382595073 DATC_Crc7Val "The data area for CRC calculation is based on the data length (DLC) of the message DB.

The CRC shall be calculated over the entire data block (excluding the CRC bytes) including the user data, alive counter and Data ID

 

- CRC Polynomial (0x1021) , Initial Value : 0xFFFF, XOR value : 0x0000, Data ID : Message ID + 0xF800 

- The initial value is for CRC calculation and the message should be sent with the calculated result value. 

- The mathematical expression to 16 bit CRC polynomial is given here. G(x) = x16 + x12 + x5 + 1";
BA_ "GenSigSendType" SG_ 2382595073 DATC_Crc7Val 4;
BA_ "GenSigStartValue" SG_ 2382595073 DATC_Crc7Val 65535;
BA_ "UserSigValidity" SG_ 2382595073 DATC_Crc7Val 3;
BA_ "Version" SG_ 2382595073 DATC_Crc7Val "18.11.08";
BA_ "Description" SG_ 2382595073 DATC_AlvCnt7Val "For the first transmission request for a data element the counter shall be initialized with 0 and shall be incremented by 1 for every subsequent send request. 

When the counter reaches the maximum value(0xFF), then it shall restart with 0 for the next send request";
BA_ "GenSigSendType" SG_ 2382595073 DATC_AlvCnt7Val 4;
BA_ "UserSigValidity" SG_ 2382595073 DATC_AlvCnt7Val 3;
BA_ "Version" SG_ 2382595073 DATC_AlvCnt7Val "18.11.08";
BA_ "Description" SG_ 2382595073 DATC_FrDrvBlwDis "This signal indicates step of Front blower Graphic.

This signal occurs when Front Blower switch(button) is selected either manually or automatically.";
BA_ "GenSigSendType" SG_ 2382595073 DATC_FrDrvBlwDis 4;
BA_ "UserSigValidity" SG_ 2382595073 DATC_FrDrvBlwDis 7;
BA_REL_ "GenSigTimeoutTime" BU_SG_REL_ ATS SG_ 2382595073 DATC_FrDrvBlwDis 1500;
BA_ "Version" SG_ 2382595073 DATC_FrDrvBlwDis "18.11.06";
BA_ "GenSigSendType" SG_ 2382595073 DATC_FrPsBlwDis 4;
BA_ "UserSigValidity" SG_ 2382595073 DATC_FrPsBlwDis 7;
BA_REL_ "GenSigTimeoutTime" BU_SG_REL_ ATS SG_ 2382595073 DATC_FrPsBlwDis 1500;
BA_ "Version" SG_ 2382595073 DATC_FrPsBlwDis "19.05.03";
BA_ "Description" SG_ 2382595073 DATC_HeatDis "This signal indicates Heat symbol Display";
BA_ "GenSigSendType" SG_ 2382595073 DATC_HeatDis 4;
BA_ "GenSigStartValue" SG_ 2382595073 DATC_HeatDis 3;
BA_ "UserSigValidity" SG_ 2382595073 DATC_HeatDis 6;
BA_REL_ "GenSigTimeoutTime" BU_SG_REL_ ATS SG_ 2382595073 DATC_HeatDis 1500;
BA_ "Version" SG_ 2382595073 DATC_HeatDis "17.11.00";
BA_ "Description" SG_ 2382595073 DATC_EVScrnDis "EV Only Screen Display";
BA_ "GenSigSendType" SG_ 2382595073 DATC_EVScrnDis 4;
BA_ "GenSigStartValue" SG_ 2382595073 DATC_EVScrnDis 3;
BA_ "UserSigValidity" SG_ 2382595073 DATC_EVScrnDis 4;
BA_ "Version" SG_ 2382595073 DATC_EVScrnDis "17.11.00";
BA_ "GenSigSendType" SG_ 2382595073 DATC_DrvOnlyDis 4;
BA_ "UserSigValidity" SG_ 2382595073 DATC_DrvOnlyDis 6;
BA_REL_ "GenSigTimeoutTime" BU_SG_REL_ ATS SG_ 2382595073 DATC_DrvOnlyDis 1500;
BA_ "Version" SG_ 2382595073 DATC_DrvOnlyDis "17.11.00";
BA_ "GenSigSendType" SG_ 2382595073 DATC_DiagCodeDis 4;
BA_ "UserSigValidity" SG_ 2382595073 DATC_DiagCodeDis 6;
BA_ "Version" SG_ 2382595073 DATC_DiagCodeDis "22.01.00";
BA_ "Description" SG_ 2382595073 DATC_RrChgReqDis "This signal indicates to show Climate Pop-up screen.

This signal occurs when any kinds of climate switch(button)s are selected manually.";
BA_ "GenSigSendType" SG_ 2382595073 DATC_RrChgReqDis 4;
BA_ "UserSigValidity" SG_ 2382595073 DATC_RrChgReqDis 6;
BA_ "Version" SG_ 2382595073 DATC_RrChgReqDis "17.11.00";
BA_ "Description" SG_ 2382595073 DATC_RrClmtScrnDis "This signal indicates that screen change to Climate Full screen.



This signal occurs when Climate switch(button) is selected manually.";
BA_ "GenSigSendType" SG_ 2382595073 DATC_RrClmtScrnDis 4;
BA_ "UserSigValidity" SG_ 2382595073 DATC_RrClmtScrnDis 6;
BA_REL_ "GenSigTimeoutTime" BU_SG_REL_ ATS SG_ 2382595073 DATC_RrClmtScrnDis 1500;
BA_ "Version" SG_ 2382595073 DATC_RrClmtScrnDis "17.11.00";
BA_ "Description" SG_ 2382595073 DATC_AUTOStep "This signal indicates AUTO step status in case Multi Auto Blower type.";
BA_ "GenSigSendType" SG_ 2382595073 DATC_AUTOStep 4;
BA_ "UserSigValidity" SG_ 2382595073 DATC_AUTOStep 7;
BA_REL_ "GenSigTimeoutTime" BU_SG_REL_ ATS SG_ 2382595073 DATC_AUTOStep 1500;
BA_ "Version" SG_ 2382595073 DATC_AUTOStep "18.12.08";
BA_ "Description" SG_ 2382595073 DATC_IntakeDis "This signal indicates intake indicator & display";
BA_ "GenSigSendType" SG_ 2382595073 DATC_IntakeDis 4;
BA_ "UserSigValidity" SG_ 2382595073 DATC_IntakeDis 7;
BA_REL_ "GenSigTimeoutTime" BU_SG_REL_ ATS SG_ 2382595073 DATC_IntakeDis 1500;
BA_ "Version" SG_ 2382595073 DATC_IntakeDis "18.12.08";
BA_ "Description" SG_ 2382595073 DATC_MultiAirModSta "This signal indicates MultiAirModeStatus";
BA_ "GenSigSendType" SG_ 2382595073 DATC_MultiAirModSta 4;
BA_ "UserSigValidity" SG_ 2382595073 DATC_MultiAirModSta 7;
BA_ "Version" SG_ 2382595073 DATC_MultiAirModSta "18.12.08";
BA_ "GenMsgSendType" BO_ 1174 0;
BA_ "Description" SG_ 1174 Drv_SHVU_SeatOptSta "¿îÀü¼® ½ÃÆ®¿¡ Àû¿ëµÈ È÷ÅÍ/ÅëÇ³ ¿É¼Ç »ç¾ç";
BA_ "GenSigSendType" SG_ 1174 Drv_SHVU_SeatOptSta 4;
BA_ "UserSigValidity" SG_ 1174 Drv_SHVU_SeatOptSta 3;
BA_REL_ "GenSigTimeoutTime" BU_SG_REL_ CGW_CCU SG_ 1174 Drv_SHVU_SeatOptSta 1500;
BA_REL_ "GenSigTimeoutTime" BU_SG_REL_ FCS SG_ 1174 Drv_SHVU_SeatOptSta 1500;
BA_REL_ "GenSigTimeoutTime" BU_SG_REL_ CGW_CCU SG_ 1174 Drv_SHVU_SeatOptSta 1500;
BA_ "NetworkRequest" SG_ 1174 Drv_SHVU_SeatOptSta 0;
BA_ "NetworkRequestHoldingTime" SG_ 1174 Drv_SHVU_SeatOptSta 5000;
BA_ "Version" SG_ 1174 Drv_SHVU_SeatOptSta "19.01.04";
BA_ "Description" SG_ 1174 Drv_SHVU_HtSwHiIndSta "¿îÀü¼® ½ÃÆ® ¿­¼± ½ºÀ§Ä¡ High Indicator Á¤º¸";
BA_ "GenSigSendType" SG_ 1174 Drv_SHVU_HtSwHiIndSta 4;
BA_ "UserSigValidity" SG_ 1174 Drv_SHVU_HtSwHiIndSta 3;
BA_REL_ "GenSigTimeoutTime" BU_SG_REL_ FCS SG_ 1174 Drv_SHVU_HtSwHiIndSta 1500;
BA_REL_ "GenSigTimeoutTime" BU_SG_REL_ CGW_CCU SG_ 1174 Drv_SHVU_HtSwHiIndSta 1500;
BA_ "NetworkRequest" SG_ 1174 Drv_SHVU_HtSwHiIndSta 0;
BA_ "NetworkRequestHoldingTime" SG_ 1174 Drv_SHVU_HtSwHiIndSta 5000;
BA_ "Version" SG_ 1174 Drv_SHVU_HtSwHiIndSta "21.07.06";
BA_ "Description" SG_ 1174 Drv_SHVU_HtSwMidIndSta "¿îÀü¼® ½ÃÆ® ¿­¼± ½ºÀ§Ä¡ Mid Indicator Á¤º¸";
BA_ "GenSigSendType" SG_ 1174 Drv_SHVU_HtSwMidIndSta 4;
BA_ "UserSigValidity" SG_ 1174 Drv_SHVU_HtSwMidIndSta 3;
BA_REL_ "GenSigTimeoutTime" BU_SG_REL_ FCS SG_ 1174 Drv_SHVU_HtSwMidIndSta 1500;
BA_REL_ "GenSigTimeoutTime" BU_SG_REL_ CGW_CCU SG_ 1174 Drv_SHVU_HtSwMidIndSta 1500;
BA_ "NetworkRequest" SG_ 1174 Drv_SHVU_HtSwMidIndSta 0;
BA_ "NetworkRequestHoldingTime" SG_ 1174 Drv_SHVU_HtSwMidIndSta 5000;
BA_ "Version" SG_ 1174 Drv_SHVU_HtSwMidIndSta "21.07.06";
BA_ "Description" SG_ 1174 Drv_SHVU_HtSwLowIndSta "¿îÀü¼® ½ÃÆ® ¿­¼± ½ºÀ§Ä¡ Low Indicator Á¤º¸";
BA_ "GenSigSendType" SG_ 1174 Drv_SHVU_HtSwLowIndSta 4;
BA_ "UserSigValidity" SG_ 1174 Drv_SHVU_HtSwLowIndSta 3;
BA_REL_ "GenSigTimeoutTime" BU_SG_REL_ FCS SG_ 1174 Drv_SHVU_HtSwLowIndSta 1500;
BA_REL_ "GenSigTimeoutTime" BU_SG_REL_ CGW_CCU SG_ 1174 Drv_SHVU_HtSwLowIndSta 1500;
BA_ "NetworkRequest" SG_ 1174 Drv_SHVU_HtSwLowIndSta 0;
BA_ "NetworkRequestHoldingTime" SG_ 1174 Drv_SHVU_HtSwLowIndSta 5000;
BA_ "Version" SG_ 1174 Drv_SHVU_HtSwLowIndSta "21.07.06";
BA_ "Description" SG_ 1174 Drv_SHVU_VntSwHiIndSta "¿îÀü¼® ½ÃÆ® ÅëÇ³ ½ºÀ§Ä¡ High Indicator Á¤º¸";
BA_ "GenSigSendType" SG_ 1174 Drv_SHVU_VntSwHiIndSta 4;
BA_ "UserSigValidity" SG_ 1174 Drv_SHVU_VntSwHiIndSta 3;
BA_REL_ "GenSigTimeoutTime" BU_SG_REL_ FCS SG_ 1174 Drv_SHVU_VntSwHiIndSta 1500;
BA_REL_ "GenSigTimeoutTime" BU_SG_REL_ CGW_CCU SG_ 1174 Drv_SHVU_VntSwHiIndSta 1500;
BA_ "NetworkRequest" SG_ 1174 Drv_SHVU_VntSwHiIndSta 0;
BA_ "NetworkRequestHoldingTime" SG_ 1174 Drv_SHVU_VntSwHiIndSta 5000;
BA_ "Version" SG_ 1174 Drv_SHVU_VntSwHiIndSta "21.07.06";
BA_ "Description" SG_ 1174 Drv_SHVU_VntSwMidIndSta "¿îÀü¼® ½ÃÆ® ÅëÇ³ ½ºÀ§Ä¡ Mid Indicator Á¤º¸";
BA_ "GenSigSendType" SG_ 1174 Drv_SHVU_VntSwMidIndSta 4;
BA_ "UserSigValidity" SG_ 1174 Drv_SHVU_VntSwMidIndSta 3;
BA_REL_ "GenSigTimeoutTime" BU_SG_REL_ FCS SG_ 1174 Drv_SHVU_VntSwMidIndSta 1500;
BA_REL_ "GenSigTimeoutTime" BU_SG_REL_ CGW_CCU SG_ 1174 Drv_SHVU_VntSwMidIndSta 1500;
BA_ "NetworkRequest" SG_ 1174 Drv_SHVU_VntSwMidIndSta 0;
BA_ "NetworkRequestHoldingTime" SG_ 1174 Drv_SHVU_VntSwMidIndSta 5000;
BA_ "Version" SG_ 1174 Drv_SHVU_VntSwMidIndSta "21.07.06";
BA_ "Description" SG_ 1174 Drv_SHVU_VntSwLowIndSta "¿îÀü¼® ½ÃÆ® ÅëÇ³ ½ºÀ§Ä¡ Low Indicator Á¤º¸";
BA_ "GenSigSendType" SG_ 1174 Drv_SHVU_VntSwLowIndSta 4;
BA_ "UserSigValidity" SG_ 1174 Drv_SHVU_VntSwLowIndSta 3;
BA_REL_ "GenSigTimeoutTime" BU_SG_REL_ FCS SG_ 1174 Drv_SHVU_VntSwLowIndSta 1500;
BA_REL_ "GenSigTimeoutTime" BU_SG_REL_ CGW_CCU SG_ 1174 Drv_SHVU_VntSwLowIndSta 1500;
BA_ "NetworkRequest" SG_ 1174 Drv_SHVU_VntSwLowIndSta 0;
BA_ "NetworkRequestHoldingTime" SG_ 1174 Drv_SHVU_VntSwLowIndSta 5000;
BA_ "Version" SG_ 1174 Drv_SHVU_VntSwLowIndSta "21.07.06";
BA_ "Description" SG_ 1174 Drv_SHVU_HtBlcUSMSta "Hetaer Balance Driver USM R vaule";
BA_ "GenSigSendType" SG_ 1174 Drv_SHVU_HtBlcUSMSta 4;
BA_ "UserSigValidity" SG_ 1174 Drv_SHVU_HtBlcUSMSta 0;
BA_REL_ "GenSigTimeoutTime" BU_SG_REL_ CGW_CCU SG_ 1174 Drv_SHVU_HtBlcUSMSta 1500;
BA_ "Version" SG_ 1174 Drv_SHVU_HtBlcUSMSta "19.01.04";
BA_ "Description" SG_ 1174 Drv_SHVU_SeatHtOperSta "¿îÀü¼® ½ÃÆ® ÇöÀç ÀÛµ¿ ÁßÀÎ È÷ÅÍ/ÅëÇ³ ´Ü¼ö »óÅÂ";
BA_ "GenSigSendType" SG_ 1174 Drv_SHVU_SeatHtOperSta 4;
BA_ "UserSigValidity" SG_ 1174 Drv_SHVU_SeatHtOperSta 3;
BA_REL_ "GenSigTimeoutTime" BU_SG_REL_ CGW_CCU SG_ 1174 Drv_SHVU_SeatHtOperSta 1500;
BA_ "NetworkRequest" SG_ 1174 Drv_SHVU_SeatHtOperSta 0;
BA_ "NetworkRequestHoldingTime" SG_ 1174 Drv_SHVU_SeatHtOperSta 5000;
BA_ "Version" SG_ 1174 Drv_SHVU_SeatHtOperSta "21.09.07";
BA_ "Description" SG_ 1174 Drv_SHVU_HtSwHiIndSta_RHD "¿îÀü¼® ½ÃÆ® ¿­¼± ½ºÀ§Ä¡ High Indicator Á¤º¸(RHD)";
BA_ "GenSigSendType" SG_ 1174 Drv_SHVU_HtSwHiIndSta_RHD 4;
BA_ "UserSigValidity" SG_ 1174 Drv_SHVU_HtSwHiIndSta_RHD 3;
BA_REL_ "GenSigTimeoutTime" BU_SG_REL_ FCS SG_ 1174 Drv_SHVU_HtSwHiIndSta_RHD 1500;
BA_REL_ "GenSigTimeoutTime" BU_SG_REL_ CGW_CCU SG_ 1174 Drv_SHVU_HtSwHiIndSta_RHD 1500;
BA_ "NetworkRequest" SG_ 1174 Drv_SHVU_HtSwHiIndSta_RHD 0;
BA_ "NetworkRequestHoldingTime" SG_ 1174 Drv_SHVU_HtSwHiIndSta_RHD 5000;
BA_ "Version" SG_ 1174 Drv_SHVU_HtSwHiIndSta_RHD "21.07.06";
BA_ "Description" SG_ 1174 Drv_SHVU_HtSwMidIndSta_RHD "¿îÀü¼® ½ÃÆ® ¿­¼± ½ºÀ§Ä¡ Mid Indicator Á¤º¸(RHD)";
BA_ "GenSigSendType" SG_ 1174 Drv_SHVU_HtSwMidIndSta_RHD 4;
BA_ "UserSigValidity" SG_ 1174 Drv_SHVU_HtSwMidIndSta_RHD 3;
BA_REL_ "GenSigTimeoutTime" BU_SG_REL_ FCS SG_ 1174 Drv_SHVU_HtSwMidIndSta_RHD 1500;
BA_REL_ "GenSigTimeoutTime" BU_SG_REL_ CGW_CCU SG_ 1174 Drv_SHVU_HtSwMidIndSta_RHD 1500;
BA_ "NetworkRequest" SG_ 1174 Drv_SHVU_HtSwMidIndSta_RHD 0;
BA_ "NetworkRequestHoldingTime" SG_ 1174 Drv_SHVU_HtSwMidIndSta_RHD 5000;
BA_ "Version" SG_ 1174 Drv_SHVU_HtSwMidIndSta_RHD "21.07.06";
BA_ "Description" SG_ 1174 Drv_SHVU_HtSwLowIndSta_RHD "¿îÀü¼® ½ÃÆ® ¿­¼± ½ºÀ§Ä¡ Low Indicator Á¤º¸(RHD)";
BA_ "GenSigSendType" SG_ 1174 Drv_SHVU_HtSwLowIndSta_RHD 4;
BA_ "UserSigValidity" SG_ 1174 Drv_SHVU_HtSwLowIndSta_RHD 3;
BA_REL_ "GenSigTimeoutTime" BU_SG_REL_ FCS SG_ 1174 Drv_SHVU_HtSwLowIndSta_RHD 1500;
BA_REL_ "GenSigTimeoutTime" BU_SG_REL_ CGW_CCU SG_ 1174 Drv_SHVU_HtSwLowIndSta_RHD 1500;
BA_ "NetworkRequest" SG_ 1174 Drv_SHVU_HtSwLowIndSta_RHD 0;
BA_ "NetworkRequestHoldingTime" SG_ 1174 Drv_SHVU_HtSwLowIndSta_RHD 5000;
BA_ "Version" SG_ 1174 Drv_SHVU_HtSwLowIndSta_RHD "21.07.06";
BA_ "Description" SG_ 1174 Drv_SHVU_VntSwHiIndSta_RHD "¿îÀü¼® ½ÃÆ® ÅëÇ³ ½ºÀ§Ä¡ High Indicator Á¤º¸(RHD)";
BA_ "GenSigSendType" SG_ 1174 Drv_SHVU_VntSwHiIndSta_RHD 4;
BA_ "UserSigValidity" SG_ 1174 Drv_SHVU_VntSwHiIndSta_RHD 3;
BA_REL_ "GenSigTimeoutTime" BU_SG_REL_ FCS SG_ 1174 Drv_SHVU_VntSwHiIndSta_RHD 1500;
BA_REL_ "GenSigTimeoutTime" BU_SG_REL_ CGW_CCU SG_ 1174 Drv_SHVU_VntSwHiIndSta_RHD 1500;
BA_ "NetworkRequest" SG_ 1174 Drv_SHVU_VntSwHiIndSta_RHD 0;
BA_ "NetworkRequestHoldingTime" SG_ 1174 Drv_SHVU_VntSwHiIndSta_RHD 5000;
BA_ "Version" SG_ 1174 Drv_SHVU_VntSwHiIndSta_RHD "21.07.06";
BA_ "Description" SG_ 1174 Drv_SHVU_VntSwMidIndSta_RHD "¿îÀü¼® ½ÃÆ® ÅëÇ³ ½ºÀ§Ä¡ Mid Indicator Á¤º¸(RHD)";
BA_ "GenSigSendType" SG_ 1174 Drv_SHVU_VntSwMidIndSta_RHD 4;
BA_ "UserSigValidity" SG_ 1174 Drv_SHVU_VntSwMidIndSta_RHD 3;
BA_REL_ "GenSigTimeoutTime" BU_SG_REL_ FCS SG_ 1174 Drv_SHVU_VntSwMidIndSta_RHD 1500;
BA_REL_ "GenSigTimeoutTime" BU_SG_REL_ CGW_CCU SG_ 1174 Drv_SHVU_VntSwMidIndSta_RHD 1500;
BA_ "NetworkRequest" SG_ 1174 Drv_SHVU_VntSwMidIndSta_RHD 0;
BA_ "NetworkRequestHoldingTime" SG_ 1174 Drv_SHVU_VntSwMidIndSta_RHD 5000;
BA_ "Version" SG_ 1174 Drv_SHVU_VntSwMidIndSta_RHD "21.07.06";
BA_ "Description" SG_ 1174 Drv_SHVU_VntSwLowIndSta_RHD "¿îÀü¼® ½ÃÆ® ÅëÇ³ ½ºÀ§Ä¡ Low Indicator Á¤º¸(RHD)";
BA_ "GenSigSendType" SG_ 1174 Drv_SHVU_VntSwLowIndSta_RHD 4;
BA_ "UserSigValidity" SG_ 1174 Drv_SHVU_VntSwLowIndSta_RHD 3;
BA_REL_ "GenSigTimeoutTime" BU_SG_REL_ FCS SG_ 1174 Drv_SHVU_VntSwLowIndSta_RHD 1500;
BA_REL_ "GenSigTimeoutTime" BU_SG_REL_ CGW_CCU SG_ 1174 Drv_SHVU_VntSwLowIndSta_RHD 1500;
BA_ "NetworkRequest" SG_ 1174 Drv_SHVU_VntSwLowIndSta_RHD 0;
BA_ "NetworkRequestHoldingTime" SG_ 1174 Drv_SHVU_VntSwLowIndSta_RHD 5000;
BA_ "Version" SG_ 1174 Drv_SHVU_VntSwLowIndSta_RHD "21.07.06";
BA_ "Description" SG_ 1174 Drv_SHVU_HtBlcUSMSta_RHD "Hetaer Balance Driver USM R vaule(RHD)";
BA_ "GenSigSendType" SG_ 1174 Drv_SHVU_HtBlcUSMSta_RHD 4;
BA_ "UserSigValidity" SG_ 1174 Drv_SHVU_HtBlcUSMSta_RHD 0;
BA_REL_ "GenSigTimeoutTime" BU_SG_REL_ CGW_CCU SG_ 1174 Drv_SHVU_HtBlcUSMSta_RHD 1500;
BA_ "Version" SG_ 1174 Drv_SHVU_HtBlcUSMSta_RHD "19.01.04";
BA_ "GenMsgCycleTime" BO_ 1179 0;
BA_ "Description" SG_ 1179 Drv_SHVU_SeatEcoSta "Drv ½ÃÆ® ¿¡ÄÚÇÃ·¯½º ¸ðµå ÁøÀÔ Á¤º¸";
BA_ "GenSigSendType" SG_ 1179 Drv_SHVU_SeatEcoSta 4;
BA_ "UserSigValidity" SG_ 1179 Drv_SHVU_SeatEcoSta 3;
BA_REL_ "GenSigTimeoutTime" BU_SG_REL_ CGW_CCU SG_ 1179 Drv_SHVU_SeatEcoSta 0;
BA_ "NetworkRequest" SG_ 1179 Drv_SHVU_SeatEcoSta 0;
BA_ "NetworkRequestHoldingTime" SG_ 1179 Drv_SHVU_SeatEcoSta 5000;
BA_ "Version" SG_ 1179 Drv_SHVU_SeatEcoSta "21.07.06";
BA_ "Description" SG_ 1179 SHVU_Drv_Beep1Sound "Play touch beep sound one time

Beep sound on/off

Default : Off

Goes On when play beep sound";
BA_ "GenSigSendType" SG_ 1179 SHVU_Drv_Beep1Sound 4;
BA_ "UserSigValidity" SG_ 1179 SHVU_Drv_Beep1Sound 3;
BA_REL_ "GenSigTimeoutTime" BU_SG_REL_ CGW_CCU SG_ 1179 SHVU_Drv_Beep1Sound 0;
BA_ "Version" SG_ 1179 SHVU_Drv_Beep1Sound "21.07.06";
BA_ "Description" SG_ 1179 SHVU_CtrlScreenDis "Change AVN Screen to control Seat Heater or Ventilation

Screen Display On : Pop up the menu of controlling Seat Heater & Ventilation

Default : Off";
BA_ "GenSigSendType" SG_ 1179 SHVU_CtrlScreenDis 4;
BA_ "UserSigValidity" SG_ 1179 SHVU_CtrlScreenDis 3;
BA_REL_ "GenSigTimeoutTime" BU_SG_REL_ CGW_CCU SG_ 1179 SHVU_CtrlScreenDis 0;
BA_ "Version" SG_ 1179 SHVU_CtrlScreenDis "21.07.06";
BA_ "GenMsgSendType" BO_ 1159 0;
BA_ "GenMsgStartDelayTime" BO_ 1159 90;
BA_ "GenSigSendType" SG_ 1159 C_AstRclBwdSw_HU 4;
BA_ "UserSigValidity" SG_ 1159 C_AstRclBwdSw_HU 0;
BA_REL_ "GenSigTimeoutTime" BU_SG_REL_ APSU SG_ 1159 C_AstRclBwdSw_HU 1500;
BA_ "Version" SG_ 1159 C_AstRclBwdSw_HU "19.11.05";
BA_ "GenSigSendType" SG_ 1159 C_AstHeightUpSw_HU 4;
BA_ "UserSigValidity" SG_ 1159 C_AstHeightUpSw_HU 0;
BA_REL_ "GenSigTimeoutTime" BU_SG_REL_ APSU SG_ 1159 C_AstHeightUpSw_HU 1500;
BA_ "Version" SG_ 1159 C_AstHeightUpSw_HU "19.11.05";
BA_ "GenSigSendType" SG_ 1159 C_AstTiltDnSw_HU 4;
BA_ "UserSigValidity" SG_ 1159 C_AstTiltDnSw_HU 0;
BA_REL_ "GenSigTimeoutTime" BU_SG_REL_ APSU SG_ 1159 C_AstTiltDnSw_HU 1500;
BA_ "Version" SG_ 1159 C_AstTiltDnSw_HU "19.11.05";
BA_ "GenSigSendType" SG_ 1159 C_AstTiltUpSw_HU 4;
BA_ "UserSigValidity" SG_ 1159 C_AstTiltUpSw_HU 0;
BA_REL_ "GenSigTimeoutTime" BU_SG_REL_ APSU SG_ 1159 C_AstTiltUpSw_HU 1500;
BA_ "Version" SG_ 1159 C_AstTiltUpSw_HU "19.11.05";
BA_ "GenSigSendType" SG_ 1159 C_AstLumbarDefSw_HU 4;
BA_ "UserSigValidity" SG_ 1159 C_AstLumbarDefSw_HU 0;
BA_REL_ "GenSigTimeoutTime" BU_SG_REL_ ASAU SG_ 1159 C_AstLumbarDefSw_HU 1500;
BA_REL_ "GenSigTimeoutTime" BU_SG_REL_ ALBCU SG_ 1159 C_AstLumbarDefSw_HU 1500;
BA_ "Version" SG_ 1159 C_AstLumbarDefSw_HU "19.11.05";
BA_ "GenSigSendType" SG_ 1159 C_AstLumbarLowSw_HU 4;
BA_ "UserSigValidity" SG_ 1159 C_AstLumbarLowSw_HU 0;
BA_REL_ "GenSigTimeoutTime" BU_SG_REL_ ASAU SG_ 1159 C_AstLumbarLowSw_HU 1500;
BA_REL_ "GenSigTimeoutTime" BU_SG_REL_ ALBCU SG_ 1159 C_AstLumbarLowSw_HU 1500;
BA_ "Version" SG_ 1159 C_AstLumbarLowSw_HU "19.11.05";
BA_ "GenSigSendType" SG_ 1159 C_AstRclFwdSw_HU 4;
BA_ "UserSigValidity" SG_ 1159 C_AstRclFwdSw_HU 0;
BA_REL_ "GenSigTimeoutTime" BU_SG_REL_ APSU SG_ 1159 C_AstRclFwdSw_HU 1500;
BA_ "Version" SG_ 1159 C_AstRclFwdSw_HU "19.11.05";
BA_ "GenSigSendType" SG_ 1159 C_AstLumbarMidSw_HU 4;
BA_ "UserSigValidity" SG_ 1159 C_AstLumbarMidSw_HU 0;
BA_REL_ "GenSigTimeoutTime" BU_SG_REL_ ASAU SG_ 1159 C_AstLumbarMidSw_HU 1500;
BA_REL_ "GenSigTimeoutTime" BU_SG_REL_ ALBCU SG_ 1159 C_AstLumbarMidSw_HU 1500;
BA_ "Version" SG_ 1159 C_AstLumbarMidSw_HU "19.11.05";
BA_ "GenSigSendType" SG_ 1159 C_AstLumbarUpSw_HU 4;
BA_ "UserSigValidity" SG_ 1159 C_AstLumbarUpSw_HU 0;
BA_REL_ "GenSigTimeoutTime" BU_SG_REL_ ASAU SG_ 1159 C_AstLumbarUpSw_HU 1500;
BA_REL_ "GenSigTimeoutTime" BU_SG_REL_ ALBCU SG_ 1159 C_AstLumbarUpSw_HU 1500;
BA_ "Version" SG_ 1159 C_AstLumbarUpSw_HU "19.11.05";
BA_ "GenSigSendType" SG_ 1159 C_RRSlideFwdSw_HU 4;
BA_ "UserSigValidity" SG_ 1159 C_RRSlideFwdSw_HU 0;
BA_REL_ "GenSigTimeoutTime" BU_SG_REL_ APSU SG_ 1159 C_RRSlideFwdSw_HU 1500;
BA_REL_ "GenSigTimeoutTime" BU_SG_REL_ RRPSU SG_ 1159 C_RRSlideFwdSw_HU 1500;
BA_REL_ "GenSigTimeoutTime" BU_SG_REL_ RLPSU SG_ 1159 C_RRSlideFwdSw_HU 1500;
BA_ "Version" SG_ 1159 C_RRSlideFwdSw_HU "19.11.05";
BA_ "GenSigSendType" SG_ 1159 C_RRSlideBwdSw_HU 4;
BA_ "UserSigValidity" SG_ 1159 C_RRSlideBwdSw_HU 0;
BA_REL_ "GenSigTimeoutTime" BU_SG_REL_ APSU SG_ 1159 C_RRSlideBwdSw_HU 1500;
BA_REL_ "GenSigTimeoutTime" BU_SG_REL_ RRPSU SG_ 1159 C_RRSlideBwdSw_HU 1500;
BA_REL_ "GenSigTimeoutTime" BU_SG_REL_ RLPSU SG_ 1159 C_RRSlideBwdSw_HU 1500;
BA_ "Version" SG_ 1159 C_RRSlideBwdSw_HU "19.11.05";
BA_ "GenSigSendType" SG_ 1159 C_RLSlideFwdSw_HU 4;
BA_ "UserSigValidity" SG_ 1159 C_RLSlideFwdSw_HU 0;
BA_REL_ "GenSigTimeoutTime" BU_SG_REL_ APSU SG_ 1159 C_RLSlideFwdSw_HU 1500;
BA_REL_ "GenSigTimeoutTime" BU_SG_REL_ RRPSU SG_ 1159 C_RLSlideFwdSw_HU 1500;
BA_REL_ "GenSigTimeoutTime" BU_SG_REL_ RLPSU SG_ 1159 C_RLSlideFwdSw_HU 1500;
BA_ "Version" SG_ 1159 C_RLSlideFwdSw_HU "19.11.05";
BA_ "GenSigSendType" SG_ 1159 C_RLSlideBwdSw_HU 4;
BA_ "UserSigValidity" SG_ 1159 C_RLSlideBwdSw_HU 0;
BA_REL_ "GenSigTimeoutTime" BU_SG_REL_ APSU SG_ 1159 C_RLSlideBwdSw_HU 1500;
BA_REL_ "GenSigTimeoutTime" BU_SG_REL_ RRPSU SG_ 1159 C_RLSlideBwdSw_HU 1500;
BA_REL_ "GenSigTimeoutTime" BU_SG_REL_ RLPSU SG_ 1159 C_RLSlideBwdSw_HU 1500;
BA_ "Version" SG_ 1159 C_RLSlideBwdSw_HU "19.11.05";
BA_ "GenSigSendType" SG_ 1159 C_AstSlideBwdSw_HU 4;
BA_ "UserSigValidity" SG_ 1159 C_AstSlideBwdSw_HU 0;
BA_REL_ "GenSigTimeoutTime" BU_SG_REL_ APSU SG_ 1159 C_AstSlideBwdSw_HU 1500;
BA_ "Version" SG_ 1159 C_AstSlideBwdSw_HU "19.11.05";
BA_ "GenSigSendType" SG_ 1159 C_AstSlideFwdSw_HU 4;
BA_ "UserSigValidity" SG_ 1159 C_AstSlideFwdSw_HU 0;
BA_REL_ "GenSigTimeoutTime" BU_SG_REL_ APSU SG_ 1159 C_AstSlideFwdSw_HU 1500;
BA_ "Version" SG_ 1159 C_AstSlideFwdSw_HU "19.11.05";
BA_ "GenSigSendType" SG_ 1159 C_AstHeightDnSw_HU 4;
BA_ "UserSigValidity" SG_ 1159 C_AstHeightDnSw_HU 0;
BA_REL_ "GenSigTimeoutTime" BU_SG_REL_ APSU SG_ 1159 C_AstHeightDnSw_HU 1500;
BA_ "Version" SG_ 1159 C_AstHeightDnSw_HU "19.11.05";
BA_ "GenMsgSendType" BO_ 197 0;
BA_ "GenSigSendType" SG_ 197 C_DrvRclBwdSw_HU 4;
BA_ "UserSigValidity" SG_ 197 C_DrvRclBwdSw_HU 0;
BA_REL_ "GenSigTimeoutTime" BU_SG_REL_ DPSU SG_ 197 C_DrvRclBwdSw_HU 1500;
BA_ "RoutingFactor" SG_ 197 C_DrvRclBwdSw_HU 0;
BA_ "Version" SG_ 197 C_DrvRclBwdSw_HU "20.01.02";
BA_ "GenSigSendType" SG_ 197 C_DrvSlideFwdSw_HU 4;
BA_ "UserSigValidity" SG_ 197 C_DrvSlideFwdSw_HU 0;
BA_REL_ "GenSigTimeoutTime" BU_SG_REL_ DPSU SG_ 197 C_DrvSlideFwdSw_HU 1500;
BA_ "RoutingFactor" SG_ 197 C_DrvSlideFwdSw_HU 0;
BA_ "Version" SG_ 197 C_DrvSlideFwdSw_HU "20.01.02";
BA_ "GenSigSendType" SG_ 197 C_RLLegSupFwdSw_HU 4;
BA_ "UserSigValidity" SG_ 197 C_RLLegSupFwdSw_HU 0;
BA_REL_ "GenSigTimeoutTime" BU_SG_REL_ APSU SG_ 197 C_RLLegSupFwdSw_HU 1500;
BA_REL_ "GenSigTimeoutTime" BU_SG_REL_ RRPSU SG_ 197 C_RLLegSupFwdSw_HU 1500;
BA_REL_ "GenSigTimeoutTime" BU_SG_REL_ RLPSU SG_ 197 C_RLLegSupFwdSw_HU 1500;
BA_ "RoutingFactor" SG_ 197 C_RLLegSupFwdSw_HU 0;
BA_ "Version" SG_ 197 C_RLLegSupFwdSw_HU "20.05.03";
BA_ "GenSigSendType" SG_ 197 C_RLLegSupBwdSw_HU 4;
BA_ "UserSigValidity" SG_ 197 C_RLLegSupBwdSw_HU 0;
BA_REL_ "GenSigTimeoutTime" BU_SG_REL_ APSU SG_ 197 C_RLLegSupBwdSw_HU 1500;
BA_REL_ "GenSigTimeoutTime" BU_SG_REL_ RRPSU SG_ 197 C_RLLegSupBwdSw_HU 1500;
BA_REL_ "GenSigTimeoutTime" BU_SG_REL_ RLPSU SG_ 197 C_RLLegSupBwdSw_HU 1500;
BA_ "RoutingFactor" SG_ 197 C_RLLegSupBwdSw_HU 0;
BA_ "Version" SG_ 197 C_RLLegSupBwdSw_HU "20.05.03";
BA_ "GenSigSendType" SG_ 197 C_DrvSlideBwdSw_HU 4;
BA_ "UserSigValidity" SG_ 197 C_DrvSlideBwdSw_HU 0;
BA_REL_ "GenSigTimeoutTime" BU_SG_REL_ DPSU SG_ 197 C_DrvSlideBwdSw_HU 1500;
BA_ "RoutingFactor" SG_ 197 C_DrvSlideBwdSw_HU 0;
BA_ "Version" SG_ 197 C_DrvSlideBwdSw_HU "20.01.02";
BA_ "GenSigSendType" SG_ 197 C_RLLegSupUpSw_HU 4;
BA_ "UserSigValidity" SG_ 197 C_RLLegSupUpSw_HU 0;
BA_REL_ "GenSigTimeoutTime" BU_SG_REL_ APSU SG_ 197 C_RLLegSupUpSw_HU 1500;
BA_REL_ "GenSigTimeoutTime" BU_SG_REL_ RRPSU SG_ 197 C_RLLegSupUpSw_HU 1500;
BA_REL_ "GenSigTimeoutTime" BU_SG_REL_ RLPSU SG_ 197 C_RLLegSupUpSw_HU 1500;
BA_ "RoutingFactor" SG_ 197 C_RLLegSupUpSw_HU 0;
BA_ "Version" SG_ 197 C_RLLegSupUpSw_HU "20.05.03";
BA_ "GenSigSendType" SG_ 197 C_RLLegSupDnSw_HU 4;
BA_ "UserSigValidity" SG_ 197 C_RLLegSupDnSw_HU 0;
BA_REL_ "GenSigTimeoutTime" BU_SG_REL_ APSU SG_ 197 C_RLLegSupDnSw_HU 1500;
BA_REL_ "GenSigTimeoutTime" BU_SG_REL_ RRPSU SG_ 197 C_RLLegSupDnSw_HU 1500;
BA_REL_ "GenSigTimeoutTime" BU_SG_REL_ RLPSU SG_ 197 C_RLLegSupDnSw_HU 1500;
BA_ "RoutingFactor" SG_ 197 C_RLLegSupDnSw_HU 0;
BA_ "Version" SG_ 197 C_RLLegSupDnSw_HU "20.05.03";
BA_ "GenSigSendType" SG_ 197 C_DrvRclFwdSw_HU 4;
BA_ "UserSigValidity" SG_ 197 C_DrvRclFwdSw_HU 0;
BA_REL_ "GenSigTimeoutTime" BU_SG_REL_ DPSU SG_ 197 C_DrvRclFwdSw_HU 1500;
BA_ "RoutingFactor" SG_ 197 C_DrvRclFwdSw_HU 0;
BA_ "Version" SG_ 197 C_DrvRclFwdSw_HU "20.01.02";
BA_ "GenMsgSendType" BO_ 1278 0;
BA_ "GenMsgCycleTime" BO_ 1278 2000;
BA_ "GenSigSendType" SG_ 1278 HU_Type 4;
BA_ "GenSigStartValue" SG_ 1278 HU_Type 255;
BA_ "UserSigValidity" SG_ 1278 HU_Type 1;
BA_REL_ "GenSigTimeoutTime" BU_SG_REL_ BLTN_CAM SG_ 1278 HU_Type 5000;
BA_ "NetworkRequest" SG_ 1278 HU_Type 0;
BA_ "NetworkRequestHoldingTime" SG_ 1278 HU_Type 7000;
BA_ "Version" SG_ 1278 HU_Type "21.05.00";
BA_ "GenSigSendType" SG_ 1278 HU_DistributeInfo 4;
BA_ "GenSigStartValue" SG_ 1278 HU_DistributeInfo 255;
BA_ "UserSigValidity" SG_ 1278 HU_DistributeInfo 1;
BA_REL_ "GenSigTimeoutTime" BU_SG_REL_ BLTN_CAM SG_ 1278 HU_DistributeInfo 5000;
BA_ "NetworkRequest" SG_ 1278 HU_DistributeInfo 0;
BA_ "NetworkRequestHoldingTime" SG_ 1278 HU_DistributeInfo 7000;
BA_ "Version" SG_ 1278 HU_DistributeInfo "20.09.00";
BA_ "Description" SG_ 1278 HU_OptionInfo "Bit0 : Navi (0: Not Support / 1: Support)

Bit1 : USM (0: Not Support / 1: Support)

Bit2 : TMS (0: Not Support / 1: Support)

Bit3 : Multi Profile (0: Not Support(No Profile or Single Profile)  / 1: Support)

Bit4 : Camera Guideline (0: Displayed by Camera / 1: Displayed by H/U)

Bit5 : LVDS Interface (0:MIPI, 1:Non-MIPI)

Bit6 : Welcome/Goodbye Animation Support (0: Not Support / 1: Support)

Bit7 : Drive/Custom Mode Support (0: Not Support / 1 : Support)

Bit8 : Automatic brightness adjustment function Support (0: Not Support / 1 : Support) 

Bit9~Bit14 : Reserved

Bit15 : 1 Invalid";
BA_ "GenSigSendType" SG_ 1278 HU_OptionInfo 4;
BA_ "GenSigStartValue" SG_ 1278 HU_OptionInfo 32768;
BA_ "UserSigValidity" SG_ 1278 HU_OptionInfo 0;
BA_REL_ "GenSigTimeoutTime" BU_SG_REL_ RCM SG_ 1278 HU_OptionInfo 5000;
BA_REL_ "GenSigTimeoutTime" BU_SG_REL_ BLTN_CAM SG_ 1278 HU_OptionInfo 5000;
BA_REL_ "GenSigTimeoutTime" BU_SG_REL_ WPC2 SG_ 1278 HU_OptionInfo 5000;
BA_ "Version" SG_ 1278 HU_OptionInfo "21.04.03";
BA_ "Description" SG_ 1278 HU_NaviMapInfo "Information about map data  used in Navigation";
BA_ "GenSigSendType" SG_ 1278 HU_NaviMapInfo 4;
BA_ "UserSigValidity" SG_ 1278 HU_NaviMapInfo 1;
BA_ "Version" SG_ 1278 HU_NaviMapInfo "20.05.03";
BA_ "Description" SG_ 1278 HU_NaviHandshakingSupport "This is a signal to send whether handshaking logic is applied related to Navigation's 'Map based ADAS' specification";
BA_ "GenSigSendType" SG_ 1278 HU_NaviHandshakingSupport 4;
BA_ "UserSigValidity" SG_ 1278 HU_NaviHandshakingSupport 1;
BA_ "Version" SG_ 1278 HU_NaviHandshakingSupport "20.05.02";
BA_ "GenSigSendType" SG_ 1278 HU_AMP_EQVariant 4;
BA_ "GenSigStartValue" SG_ 1278 HU_AMP_EQVariant 31;
BA_ "UserSigValidity" SG_ 1278 HU_AMP_EQVariant 1;
BA_ "Version" SG_ 1278 HU_AMP_EQVariant "20.08.06";
BA_ "Description" SG_ 1278 HU_AdasSupport "0x0 : Not Support

0x1 : ADAS Support (General Map) - Send map information based on General Map

0x2 : ADAS Support (Map based ADAS v1) - Send map information based on Map based ADAS v1 or v1.5

0x3 : ADAS Support (Map based ADAS v2) - Send map information based on Map based ADAS v2.0

0x4 : ADAS Support (Map based ADAS v2.0 & Handshaking) - Send map information based on Map based ADAS v2.0 & Support Handshaking 

0x5 : ADAS Support (Map based ADAS v2.3)  

 - 2nd CAN DB :  Send map information based on Map based ADAS v2.3 

 - 3rd CAN DB : Send map information based on Map based ADAS v2.3 & Support Handshaking";
BA_ "GenSigSendType" SG_ 1278 HU_AdasSupport 4;
BA_ "GenSigStartValue" SG_ 1278 HU_AdasSupport 7;
BA_ "UserSigValidity" SG_ 1278 HU_AdasSupport 1;
BA_ "NetworkRequest" SG_ 1278 HU_AdasSupport 0;
BA_ "NetworkRequestHoldingTime" SG_ 1278 HU_AdasSupport 5000;
BA_ "Version" SG_ 1278 HU_AdasSupport "20.05.02";
BA_ "Description" SG_ 1278 HU_Navi_RspADASMapMsg "This signal indicates an ADAS map message response from H_U to ECU 

which is stored the  required Map based ADAS messages for each ECU



Each bit indicates the request messages as follows.

(1: Sending message / 0 : Doens't sending message)

- Bit 0 : H_U_NAVI_V2_STUB_E

- Bit 1 : HU_NAVI_V2_PROSHORT_E_00 (Curvature info)

- Bit 2 : HU_NAVI_V2_PROSHORT_E_00 (Info execpt curvature)

- Bit 3 : HU_NAVI_V2_PROSHORT_E_01

- Bit 4 : HU_NAVI_V2_PROSHORT_E_02

- Bit 5 : HU_NAVI_V2_PROLONG_E

- Bit 6 : HU_NAVI_V2_SEG_SUB_E, 

             HU_NAVI_V2_STUB_SUB_E, 

             HU_NAVI_V2_PROSHORT_SUB_E, 

             HU_NAVI_V2_PROLONG_SUB_E

- Bit 7 : HU_NAVI_V2_PATH_PE_00, 

             HU_NAVI_V2_PATH_PE_01

- Bit 8~15 : Reserved";
BA_ "GenSigSendType" SG_ 1278 HU_Navi_RspADASMapMsg 4;
BA_ "UserSigValidity" SG_ 1278 HU_Navi_RspADASMapMsg 3;
BA_ "Version" SG_ 1278 HU_Navi_RspADASMapMsg "21.11.04";
BA_ "GenMsgCycleTime" BO_ 1279 0;
BA_ "Description" SG_ 1279 USM_SmartRegen_Map_Set "Smart Regeneration 2.0 Map information USM User set signal";
BA_ "GenSigSendType" SG_ 1279 USM_SmartRegen_Map_Set 4;
BA_ "UserSigValidity" SG_ 1279 USM_SmartRegen_Map_Set 3;
BA_ "Version" SG_ 1279 USM_SmartRegen_Map_Set "19.11.05";
BA_ "Description" SG_ 1279 USM_SmartRegen_Sens_Set "Smart Regeneration User Personality of Reduction Set Signal";
BA_ "GenSigSendType" SG_ 1279 USM_SmartRegen_Sens_Set 4;
BA_ "UserSigValidity" SG_ 1279 USM_SmartRegen_Sens_Set 3;
BA_ "Version" SG_ 1279 USM_SmartRegen_Sens_Set "19.11.05";
BA_ "Description" SG_ 1279 AVN_SeatPosMemory_Btn "Seat position save signal";
BA_ "GenSigSendType" SG_ 1279 AVN_SeatPosMemory_Btn 4;
BA_ "UserSigValidity" SG_ 1279 AVN_SeatPosMemory_Btn 3;
BA_ "Version" SG_ 1279 AVN_SeatPosMemory_Btn "19.11.11";
BA_ "Description" SG_ 1279 AVN_SeatPosPlyBck_Btn "Seat position move signal";
BA_ "GenSigSendType" SG_ 1279 AVN_SeatPosPlyBck_Btn 4;
BA_ "UserSigValidity" SG_ 1279 AVN_SeatPosPlyBck_Btn 3;
BA_REL_ "GenSigTimeoutTime" BU_SG_REL_ DPSU SG_ 1279 AVN_SeatPosPlyBck_Btn 0;
BA_ "Version" SG_ 1279 AVN_SeatPosPlyBck_Btn "19.11.11";
BA_ "Description" SG_ 1279 USM_RhstaLvlEnaSetReq "USM Request for CMS Brightness with Rheostat";
BA_ "GenSigSendType" SG_ 1279 USM_RhstaLvlEnaSetReq 4;
BA_ "UserSigValidity" SG_ 1279 USM_RhstaLvlEnaSetReq 0;
BA_ "Version" SG_ 1279 USM_RhstaLvlEnaSetReq "19.12.00";
BA_ "Description" SG_ 1279 USM_CMSDayBrgtnsLvlLHSetReq "USM Request for Day Brightness Level of CMS LH";
BA_ "GenSigSendType" SG_ 1279 USM_CMSDayBrgtnsLvlLHSetReq 4;
BA_ "GenSigStartValue" SG_ 1279 USM_CMSDayBrgtnsLvlLHSetReq 15;
BA_ "UserSigValidity" SG_ 1279 USM_CMSDayBrgtnsLvlLHSetReq 0;
BA_ "Version" SG_ 1279 USM_CMSDayBrgtnsLvlLHSetReq "19.12.00";
BA_ "Description" SG_ 1279 USM_CMSNgtBrgtnsLvlLHSetReq "USM Request for Night Brightness Level of CMS LH";
BA_ "GenSigSendType" SG_ 1279 USM_CMSNgtBrgtnsLvlLHSetReq 4;
BA_ "GenSigStartValue" SG_ 1279 USM_CMSNgtBrgtnsLvlLHSetReq 15;
BA_ "UserSigValidity" SG_ 1279 USM_CMSNgtBrgtnsLvlLHSetReq 0;
BA_ "Version" SG_ 1279 USM_CMSNgtBrgtnsLvlLHSetReq "19.12.00";
BA_ "Description" SG_ 1279 USM_CMSDayBrgtnsLvlRHSetReq "USM Request for Day Brightness Level of CMS RH";
BA_ "GenSigSendType" SG_ 1279 USM_CMSDayBrgtnsLvlRHSetReq 4;
BA_ "GenSigStartValue" SG_ 1279 USM_CMSDayBrgtnsLvlRHSetReq 15;
BA_ "UserSigValidity" SG_ 1279 USM_CMSDayBrgtnsLvlRHSetReq 0;
BA_ "Version" SG_ 1279 USM_CMSDayBrgtnsLvlRHSetReq "19.12.00";
BA_ "Description" SG_ 1279 USM_CMSNgtBrgtnsLvlRHSetReq "USM Request for Night Brightness Level of CMS RH";
BA_ "GenSigSendType" SG_ 1279 USM_CMSNgtBrgtnsLvlRHSetReq 4;
BA_ "GenSigStartValue" SG_ 1279 USM_CMSNgtBrgtnsLvlRHSetReq 15;
BA_ "UserSigValidity" SG_ 1279 USM_CMSNgtBrgtnsLvlRHSetReq 0;
BA_ "Version" SG_ 1279 USM_CMSNgtBrgtnsLvlRHSetReq "19.12.00";
BA_ "Description" SG_ 1279 USM_CMSBrgtnsReset "CMS Brightness Reset (LH/RH)";
BA_ "GenSigSendType" SG_ 1279 USM_CMSBrgtnsReset 4;
BA_ "UserSigValidity" SG_ 1279 USM_CMSBrgtnsReset 3;
BA_ "Version" SG_ 1279 USM_CMSBrgtnsReset "20.06.01";
BA_ "Description" SG_ 1279 USM_TurnDistLnDispSetReq "USM Request for CMS Distance Lane Display";
BA_ "GenSigSendType" SG_ 1279 USM_TurnDistLnDispSetReq 4;
BA_ "UserSigValidity" SG_ 1279 USM_TurnDistLnDispSetReq 0;
BA_ "Version" SG_ 1279 USM_TurnDistLnDispSetReq "19.12.00";
BA_ "Description" SG_ 1279 PCA_FrSd_NValueSet "USM Request for PCA Front/Side";
BA_ "GenSigSendType" SG_ 1279 PCA_FrSd_NValueSet 4;
BA_ "UserSigValidity" SG_ 1279 PCA_FrSd_NValueSet 3;
BA_ "Version" SG_ 1279 PCA_FrSd_NValueSet "19.12.00";
BA_ "Description" SG_ 1279 CF_AVN_1stRrStRmndNValueSet "This signal is for seting the ROA function when IBU control ROA Function.";
BA_ "GenSigSendType" SG_ 1279 CF_AVN_1stRrStRmndNValueSet 4;
BA_ "UserSigValidity" SG_ 1279 CF_AVN_1stRrStRmndNValueSet 3;
BA_ "Version" SG_ 1279 CF_AVN_1stRrStRmndNValueSet "20.03.05";
BA_ "Description" SG_ 1279 C_AllDrOpnNValueSet "ALL Door (PSD PTG) Open Function by FOB Unlock Long Key USM Setting Signal

0x0 : Not Display in USM

0x1 : All Door Open Function Off

0x2 : Only PSD Open By FOB Unlock Long KEY

0x3 : PSD and PTG Open by FOB Unlock Long KEY

0x4 ~ 0x6 : Reserved

0x7 : Invalid";
BA_ "GenSigSendType" SG_ 1279 C_AllDrOpnNValueSet 4;
BA_ "UserSigValidity" SG_ 1279 C_AllDrOpnNValueSet 3;
BA_ "Version" SG_ 1279 C_AllDrOpnNValueSet "19.12.07";
BA_ "Description" SG_ 1279 USM_RpmECOSet "Relation To cluster Gauge Display";
BA_ "GenSigSendType" SG_ 1279 USM_RpmECOSet 4;
BA_ "UserSigValidity" SG_ 1279 USM_RpmECOSet 3;
BA_ "Version" SG_ 1279 USM_RpmECOSet "20.06.01";
BA_ "Description" SG_ 1279 VESS_ChgGuideMdLvl "Charging Guide Volume Level function USM signal";
BA_ "GenSigSendType" SG_ 1279 VESS_ChgGuideMdLvl 4;
BA_ "UserSigValidity" SG_ 1279 VESS_ChgGuideMdLvl 3;
BA_ "Version" SG_ 1279 VESS_ChgGuideMdLvl "20.05.01";
BA_ "Description" SG_ 1279 Usm_RpmSPORTSet "Relation to cluster RPM Gauge Display";
BA_ "GenSigSendType" SG_ 1279 Usm_RpmSPORTSet 4;
BA_ "UserSigValidity" SG_ 1279 Usm_RpmSPORTSet 3;
BA_ "Version" SG_ 1279 Usm_RpmSPORTSet "20.02.04";
BA_ "Description" SG_ 1279 Usm_RpmSPORTPLUSSet "RElation to Cluster RPM Gauge Display";
BA_ "GenSigSendType" SG_ 1279 Usm_RpmSPORTPLUSSet 4;
BA_ "UserSigValidity" SG_ 1279 Usm_RpmSPORTPLUSSet 3;
BA_ "Version" SG_ 1279 Usm_RpmSPORTPLUSSet "20.02.04";
BA_ "GenMsgCycleTime" BO_ 200 0;
BA_ "Description" SG_ 200 CF_AVN_ADrLNValueSet_2 "USM Reqeust for Auto Door Lock";
BA_ "GenSigSendType" SG_ 200 CF_AVN_ADrLNValueSet_2 4;
BA_ "UserSigValidity" SG_ 200 CF_AVN_ADrLNValueSet_2 3;
BA_ "RoutingFactor" SG_ 200 CF_AVN_ADrLNValueSet_2 0;
BA_ "Version" SG_ 200 CF_AVN_ADrLNValueSet_2 "21.01.06";
BA_ "Description" SG_ 200 CF_AVN_FCA_JC_OnOffEquipNvalueSet "USM Set signal for Forward Corss-traffic";
BA_ "GenSigSendType" SG_ 200 CF_AVN_FCA_JC_OnOffEquipNvalueSet 4;
BA_ "UserSigValidity" SG_ 200 CF_AVN_FCA_JC_OnOffEquipNvalueSet 3;
BA_ "RoutingFactor" SG_ 200 CF_AVN_FCA_JC_OnOffEquipNvalueSet 0;
BA_ "Version" SG_ 200 CF_AVN_FCA_JC_OnOffEquipNvalueSet "20.12.00";
BA_ "Description" SG_ 200 CF_AVN_FCA_FrSdOnOffEquipNvalueSet "USM Set signal for Forward/Side Safety";
BA_ "GenSigSendType" SG_ 200 CF_AVN_FCA_FrSdOnOffEquipNvalueSet 4;
BA_ "UserSigValidity" SG_ 200 CF_AVN_FCA_FrSdOnOffEquipNvalueSet 3;
BA_ "RoutingFactor" SG_ 200 CF_AVN_FCA_FrSdOnOffEquipNvalueSet 0;
BA_ "Version" SG_ 200 CF_AVN_FCA_FrSdOnOffEquipNvalueSet "20.12.00";
BA_ "Description" SG_ 200 CF_AVN_LKA_OnOffEquip2NvalueSet "USM Set Signal for Lane safety";
BA_ "GenSigSendType" SG_ 200 CF_AVN_LKA_OnOffEquip2NvalueSet 4;
BA_ "UserSigValidity" SG_ 200 CF_AVN_LKA_OnOffEquip2NvalueSet 3;
BA_ "RoutingFactor" SG_ 200 CF_AVN_LKA_OnOffEquip2NvalueSet 0;
BA_ "Version" SG_ 200 CF_AVN_LKA_OnOffEquip2NvalueSet "20.12.00";
BA_ "Description" SG_ 200 CF_AVN_BCA_OnOffEquip2NvalueSet "USM Set signal for Side/Rear Safety";
BA_ "GenSigSendType" SG_ 200 CF_AVN_BCA_OnOffEquip2NvalueSet 4;
BA_ "UserSigValidity" SG_ 200 CF_AVN_BCA_OnOffEquip2NvalueSet 3;
BA_ "RoutingFactor" SG_ 200 CF_AVN_BCA_OnOffEquip2NvalueSet 0;
BA_ "Version" SG_ 200 CF_AVN_BCA_OnOffEquip2NvalueSet "20.12.00";
BA_ "Description" SG_ 200 CF_AVN_BVM_OnOffEquipNvalueSet "USM Set signal for Blind Spot View";
BA_ "GenSigSendType" SG_ 200 CF_AVN_BVM_OnOffEquipNvalueSet 4;
BA_ "UserSigValidity" SG_ 200 CF_AVN_BVM_OnOffEquipNvalueSet 3;
BA_ "RoutingFactor" SG_ 200 CF_AVN_BVM_OnOffEquipNvalueSet 0;
BA_ "Version" SG_ 200 CF_AVN_BVM_OnOffEquipNvalueSet "20.12.00";
BA_ "Description" SG_ 200 CF_AVN_SEA_OnOffEquip3NvalueSet "Usm Set signal for safety exit assist";
BA_ "GenSigSendType" SG_ 200 CF_AVN_SEA_OnOffEquip3NvalueSet 4;
BA_ "UserSigValidity" SG_ 200 CF_AVN_SEA_OnOffEquip3NvalueSet 3;
BA_ "RoutingFactor" SG_ 200 CF_AVN_SEA_OnOffEquip3NvalueSet 0;
BA_ "Version" SG_ 200 CF_AVN_SEA_OnOffEquip3NvalueSet "20.12.00";
BA_ "Description" SG_ 200 CF_AVN_BodySpprtSet_AST "Ergo-Motion Seat Smart Posture Assist";
BA_ "GenSigSendType" SG_ 200 CF_AVN_BodySpprtSet_AST 4;
BA_ "GenSigStartValue" SG_ 200 CF_AVN_BodySpprtSet_AST 3;
BA_ "UserSigValidity" SG_ 200 CF_AVN_BodySpprtSet_AST 3;
BA_REL_ "GenSigTimeoutTime" BU_SG_REL_ ALBCU SG_ 200 CF_AVN_BodySpprtSet_AST 0;
BA_ "RoutingFactor" SG_ 200 CF_AVN_BodySpprtSet_AST 0;
BA_ "Version" SG_ 200 CF_AVN_BodySpprtSet_AST "20.10.02";
BA_ "Description" SG_ 200 CF_AVN_SEW_OnOffEquip3NvalueSet "Usm Set signal for Safety exit warning";
BA_ "GenSigSendType" SG_ 200 CF_AVN_SEW_OnOffEquip3NvalueSet 4;
BA_ "UserSigValidity" SG_ 200 CF_AVN_SEW_OnOffEquip3NvalueSet 3;
BA_ "RoutingFactor" SG_ 200 CF_AVN_SEW_OnOffEquip3NvalueSet 0;
BA_ "Version" SG_ 200 CF_AVN_SEW_OnOffEquip3NvalueSet "20.12.00";
BA_ "Description" SG_ 200 CF_AVN_HudImsAutoSave "USM request for auto save HUD setting with IMS";
BA_ "GenSigSendType" SG_ 200 CF_AVN_HudImsAutoSave 4;
BA_ "UserSigValidity" SG_ 200 CF_AVN_HudImsAutoSave 3;
BA_ "RoutingFactor" SG_ 200 CF_AVN_HudImsAutoSave 0;
BA_ "Version" SG_ 200 CF_AVN_HudImsAutoSave "20.12.05";
BA_ "Description" SG_ 200 USM_PwrDrBuzzerNValueSet "USM Request for Power Door Buzzer";
BA_ "GenSigSendType" SG_ 200 USM_PwrDrBuzzerNValueSet 4;
BA_ "UserSigValidity" SG_ 200 USM_PwrDrBuzzerNValueSet 3;
BA_ "RoutingFactor" SG_ 200 USM_PwrDrBuzzerNValueSet 0;
BA_ "Version" SG_ 200 USM_PwrDrBuzzerNValueSet "21.01.06";
BA_ "Description" SG_ 200 CF_AVN_DWLNValueSet "Request for USM Dynamic Welcome Light";
BA_ "GenSigSendType" SG_ 200 CF_AVN_DWLNValueSet 4;
BA_ "UserSigValidity" SG_ 200 CF_AVN_DWLNValueSet 3;
BA_ "RoutingFactor" SG_ 200 CF_AVN_DWLNValueSet 0;
BA_ "Version" SG_ 200 CF_AVN_DWLNValueSet "21.01.01";
BA_ "Description" SG_ 200 CF_AVN_AirSptTimeNValueSet_AST "Ergo-Motion Seat Comfortable Stretch Operational Time";
BA_ "GenSigSendType" SG_ 200 CF_AVN_AirSptTimeNValueSet_AST 4;
BA_ "GenSigStartValue" SG_ 200 CF_AVN_AirSptTimeNValueSet_AST 7;
BA_ "UserSigValidity" SG_ 200 CF_AVN_AirSptTimeNValueSet_AST 3;
BA_REL_ "GenSigTimeoutTime" BU_SG_REL_ ALBCU SG_ 200 CF_AVN_AirSptTimeNValueSet_AST 0;
BA_ "RoutingFactor" SG_ 200 CF_AVN_AirSptTimeNValueSet_AST 0;
BA_ "Version" SG_ 200 CF_AVN_AirSptTimeNValueSet_AST "20.10.02";
BA_ "Description" SG_ 200 CF_AVN_AirSptStrNValue_AST "Ergo-Motion Seat Comfortable Stretch Strong/Normal";
BA_ "GenSigSendType" SG_ 200 CF_AVN_AirSptStrNValue_AST 4;
BA_ "GenSigStartValue" SG_ 200 CF_AVN_AirSptStrNValue_AST 3;
BA_ "UserSigValidity" SG_ 200 CF_AVN_AirSptStrNValue_AST 3;
BA_REL_ "GenSigTimeoutTime" BU_SG_REL_ ALBCU SG_ 200 CF_AVN_AirSptStrNValue_AST 0;
BA_ "RoutingFactor" SG_ 200 CF_AVN_AirSptStrNValue_AST 0;
BA_ "Version" SG_ 200 CF_AVN_AirSptStrNValue_AST "20.10.02";
BA_ "Description" SG_ 200 CF_AVN_SeatDrvModNvalueSet_AST "Ergo-Motion Seat Smart Support";
BA_ "GenSigSendType" SG_ 200 CF_AVN_SeatDrvModNvalueSet_AST 4;
BA_ "GenSigStartValue" SG_ 200 CF_AVN_SeatDrvModNvalueSet_AST 3;
BA_ "UserSigValidity" SG_ 200 CF_AVN_SeatDrvModNvalueSet_AST 3;
BA_REL_ "GenSigTimeoutTime" BU_SG_REL_ ALBCU SG_ 200 CF_AVN_SeatDrvModNvalueSet_AST 0;
BA_ "RoutingFactor" SG_ 200 CF_AVN_SeatDrvModNvalueSet_AST 0;
BA_ "Version" SG_ 200 CF_AVN_SeatDrvModNvalueSet_AST "20.12.00";
BA_ "Description" SG_ 200 CF_AVN_TPMS_TireReplaceNValueSet "USM Set Signal for Standard Tire to Wnter Tire";
BA_ "GenSigSendType" SG_ 200 CF_AVN_TPMS_TireReplaceNValueSet 4;
BA_ "UserSigValidity" SG_ 200 CF_AVN_TPMS_TireReplaceNValueSet 3;
BA_ "RoutingFactor" SG_ 200 CF_AVN_TPMS_TireReplaceNValueSet 0;
BA_ "Version" SG_ 200 CF_AVN_TPMS_TireReplaceNValueSet "20.12.04";
BA_ "Description" SG_ 200 CF_AVN_TowModeSet "USM Set signal For TowMode";
BA_ "GenSigSendType" SG_ 200 CF_AVN_TowModeSet 4;
BA_ "UserSigValidity" SG_ 200 CF_AVN_TowModeSet 3;
BA_ "RoutingFactor" SG_ 200 CF_AVN_TowModeSet 0;
BA_ "Version" SG_ 200 CF_AVN_TowModeSet "20.12.04";
BA_ "Description" SG_ 200 USM_PwrDrCloseByBraekNValueSet "USM Reqeust for Power Door Close by Brake";
BA_ "GenSigSendType" SG_ 200 USM_PwrDrCloseByBraekNValueSet 4;
BA_ "UserSigValidity" SG_ 200 USM_PwrDrCloseByBraekNValueSet 3;
BA_ "RoutingFactor" SG_ 200 USM_PwrDrCloseByBraekNValueSet 0;
BA_ "Version" SG_ 200 USM_PwrDrCloseByBraekNValueSet "21.01.06";
BA_ "Description" SG_ 200 CF_AVN_ISLANAOffstNvalueSet "Control ISLA offset on USM Fucntion (North America)";
BA_ "GenSigSendType" SG_ 200 CF_AVN_ISLANAOffstNvalueSet 4;
BA_ "UserSigValidity" SG_ 200 CF_AVN_ISLANAOffstNvalueSet 3;
BA_ "RoutingFactor" SG_ 200 CF_AVN_ISLANAOffstNvalueSet 0;
BA_ "Version" SG_ 200 CF_AVN_ISLANAOffstNvalueSet "21.03.10";
BA_ "Description" SG_ 200 CF_Gway_WPC2_NValueSet "USM Set signal for 2nd WPC setting";
BA_ "GenSigSendType" SG_ 200 CF_Gway_WPC2_NValueSet 4;
BA_ "UserSigValidity" SG_ 200 CF_Gway_WPC2_NValueSet 3;
BA_REL_ "GenSigTimeoutTime" BU_SG_REL_ WPC2 SG_ 200 CF_Gway_WPC2_NValueSet 0;
BA_ "RoutingFactor" SG_ 200 CF_Gway_WPC2_NValueSet 0;
BA_ "Version" SG_ 200 CF_Gway_WPC2_NValueSet "22.02.05";
BA_ "Description" SG_ 200 USM_DrvGhostDoorReq "USM Request for Driver Door Ghost Door Closing On/Off";
BA_ "GenSigSendType" SG_ 200 USM_DrvGhostDoorReq 4;
BA_ "UserSigValidity" SG_ 200 USM_DrvGhostDoorReq 3;
BA_ "RoutingFactor" SG_ 200 USM_DrvGhostDoorReq 0;
BA_ "Version" SG_ 200 USM_DrvGhostDoorReq "21.03.11";
BA_ "Description" SG_ 200 USM_AstGhostDoorReq "USM Request for Assistant Ghost Door Closing On/Off";
BA_ "GenSigSendType" SG_ 200 USM_AstGhostDoorReq 4;
BA_ "UserSigValidity" SG_ 200 USM_AstGhostDoorReq 3;
BA_ "RoutingFactor" SG_ 200 USM_AstGhostDoorReq 0;
BA_ "Version" SG_ 200 USM_AstGhostDoorReq "21.03.11";
BA_ "Description" SG_ 200 USM_RLGhostDoorReq "USM Request for Rear Left Ghost Door Closing On/Off";
BA_ "GenSigSendType" SG_ 200 USM_RLGhostDoorReq 4;
BA_ "UserSigValidity" SG_ 200 USM_RLGhostDoorReq 3;
BA_ "RoutingFactor" SG_ 200 USM_RLGhostDoorReq 0;
BA_ "Version" SG_ 200 USM_RLGhostDoorReq "21.03.11";
BA_ "Description" SG_ 200 USM_RRGhostDoorReq "USM Request for Rear Right Ghost Door Closing On/Off";
BA_ "GenSigSendType" SG_ 200 USM_RRGhostDoorReq 4;
BA_ "UserSigValidity" SG_ 200 USM_RRGhostDoorReq 3;
BA_ "RoutingFactor" SG_ 200 USM_RRGhostDoorReq 0;
BA_ "Version" SG_ 200 USM_RRGhostDoorReq "21.03.11";
BA_ "Description" SG_ 200 CF_AVN_FCA_FrOnOffEquipNvalueSet "USM Set Signal for Forward Safety";
BA_ "GenSigSendType" SG_ 200 CF_AVN_FCA_FrOnOffEquipNvalueSet 4;
BA_ "UserSigValidity" SG_ 200 CF_AVN_FCA_FrOnOffEquipNvalueSet 3;
BA_ "RoutingFactor" SG_ 200 CF_AVN_FCA_FrOnOffEquipNvalueSet 0;
BA_ "Version" SG_ 200 CF_AVN_FCA_FrOnOffEquipNvalueSet "20.12.00";
BA_ "Description" SG_ 200 CF_AVN_FCA_WarnTimeNvalueSet "USM Set signal for Forward Warntime";
BA_ "GenSigSendType" SG_ 200 CF_AVN_FCA_WarnTimeNvalueSet 4;
BA_ "UserSigValidity" SG_ 200 CF_AVN_FCA_WarnTimeNvalueSet 3;
BA_ "RoutingFactor" SG_ 200 CF_AVN_FCA_WarnTimeNvalueSet 0;
BA_ "Version" SG_ 200 CF_AVN_FCA_WarnTimeNvalueSet "20.12.00";
BA_ "GenMsgSendType" BO_ 1167 0;
BA_ "GenMsgCycleTime" BO_ 1167 1000;
BA_ "Description" SG_ 1167 ICU_Crc11Val "The data area for CRC calculation is based on the data length (DLC) of the message DB.

The CRC shall be calculated over the entire data block (excluding the CRC bytes) including the user data, alive counter and Data ID 

 

- CRC Polynomial (0x1D) , Initial Value : 0x00, XOR value : 0xFF, Data ID Mode : Both, Data ID : Message ID + 0xF800 

- The initial value is for CRC calculation and the message should be sent with the calculated result value. 

The mathematical expression to 8 bit CRC polynomial is given here. G(x) = x8 + x4 + x3 + x2 + 1";
BA_ "GenSigSendType" SG_ 1167 ICU_Crc11Val 4;
BA_ "GenSigStartValue" SG_ 1167 ICU_Crc11Val 255;
BA_ "UserSigValidity" SG_ 1167 ICU_Crc11Val 0;
BA_ "Version" SG_ 1167 ICU_Crc11Val "18.11.08";
BA_ "Description" SG_ 1167 Bat_dischrg "Battery discharge notification flag";
BA_ "GenSigSendType" SG_ 1167 Bat_dischrg 4;
BA_ "UserSigValidity" SG_ 1167 Bat_dischrg 3;
BA_ "Version" SG_ 1167 Bat_dischrg "21.07.05";
BA_ "Description" SG_ 1167 ICU_AlvCnt11Val "For the first transmission request for a data element the counter shall be initialized with 0 and shall be incremented by 1

for every subsequent send request. When the counter reaches the maximum value(0xE), then it shall restart with 0 for the next send request";
BA_ "GenSigSendType" SG_ 1167 ICU_AlvCnt11Val 4;
BA_ "UserSigValidity" SG_ 1167 ICU_AlvCnt11Val 0;
BA_ "Version" SG_ 1167 ICU_AlvCnt11Val "18.11.08";
BA_ "Description" SG_ 1167 Batt_SoCWarningValue "This signal is Battery SOC from battery sensor.";
BA_ "GenSigSendType" SG_ 1167 Batt_SoCWarningValue 4;
BA_ "GenSigStartValue" SG_ 1167 Batt_SoCWarningValue 255;
BA_ "UserSigValidity" SG_ 1167 Batt_SoCWarningValue 0;
BA_ "Version" SG_ 1167 Batt_SoCWarningValue "17.12.00";
BA_ "Description" SG_ 1167 C_StrgWhlHeatingOpt "Steering wheel heating option signal";
BA_ "GenSigSendType" SG_ 1167 C_StrgWhlHeatingOpt 4;
BA_ "UserSigValidity" SG_ 1167 C_StrgWhlHeatingOpt 3;
BA_ "Version" SG_ 1167 C_StrgWhlHeatingOpt "18.12.02";
BA_ "Description" SG_ 1167 C_StrgWhlHeatingSWInf "Steering wheel heating Step information signal";
BA_ "GenSigSendType" SG_ 1167 C_StrgWhlHeatingSWInf 4;
BA_ "UserSigValidity" SG_ 1167 C_StrgWhlHeatingSWInf 3;
BA_ "Version" SG_ 1167 C_StrgWhlHeatingSWInf "19.11.11";
BA_ "Description" SG_ 1167 ICU_BattAutoCutPreWrng "This is a warning signal before blocking the dark current of the ICU by the battery SOC.";
BA_ "GenSigSendType" SG_ 1167 ICU_BattAutoCutPreWrng 4;
BA_ "GenSigStartValue" SG_ 1167 ICU_BattAutoCutPreWrng 3;
BA_ "UserSigValidity" SG_ 1167 ICU_BattAutoCutPreWrng 0;
BA_REL_ "GenSigTimeoutTime" BU_SG_REL_ BLTN_CAM SG_ 1167 ICU_BattAutoCutPreWrng 5000;
BA_ "Version" SG_ 1167 ICU_BattAutoCutPreWrng "20.04.06";
BA_ "Description" SG_ 1167 IGN_AutoOff_WarnSta_CLU "This signal is for battery discharge warning (engine not running && IGN/ACC on)

To prevent battery discharge, ICU requests the Cluster to display warning and requests IBU to turn IGN/ACC off.";
BA_ "GenSigSendType" SG_ 1167 IGN_AutoOff_WarnSta_CLU 4;
BA_ "UserSigValidity" SG_ 1167 IGN_AutoOff_WarnSta_CLU 3;
BA_ "Version" SG_ 1167 IGN_AutoOff_WarnSta_CLU "20.07.10";
BA_ "Description" SG_ 1167 PDC_BatPwrStateClassA "Battery Power State ClassA 

Battery Power State ClassC

0x0 : This signal is not used.

The target function is operated based on the main battery SoC value.(Legacy mode)

0x3 : PDC Logic is not ready because of battery Sensor Error or other reason.  Target function-operation is recommanded according to low(0x1) power mode.";
BA_ "GenSigSendType" SG_ 1167 PDC_BatPwrStateClassA 4;
BA_ "UserSigValidity" SG_ 1167 PDC_BatPwrStateClassA 0;
BA_ "Version" SG_ 1167 PDC_BatPwrStateClassA "21.06.08";
BA_ "Description" SG_ 1167 PDC_BatPwrStateClassB "Battery Power State ClassB

Battery Power State ClassC

0x0 : This signal is not used.

The target function is operated based on the main battery SoC value.(Legacy mode)

0x3 : PDC Logic is not ready because of battery Sensor Error or other reason.  Target function-operation is recommanded according to low(0x1) power mode.";
BA_ "GenSigSendType" SG_ 1167 PDC_BatPwrStateClassB 4;
BA_ "UserSigValidity" SG_ 1167 PDC_BatPwrStateClassB 0;
BA_ "Version" SG_ 1167 PDC_BatPwrStateClassB "21.06.08";
BA_ "Description" SG_ 1167 PDC_BatPwrStateClassC "Battery Power State ClassC

0x0 : This signal is not used.

The target function is operated based on the main battery SoC value.(Legacy mode)

0x3 : PDC Logic is not ready because of battery Sensor Error or other reason.  Target function-operation is recommanded according to low(0x1) power mode.";
BA_ "GenSigSendType" SG_ 1167 PDC_BatPwrStateClassC 4;
BA_ "UserSigValidity" SG_ 1167 PDC_BatPwrStateClassC 0;
BA_ "Version" SG_ 1167 PDC_BatPwrStateClassC "21.06.08";
BA_ "Description" SG_ 1167 PLBMAvailableState "Power supply Available status notification at PLBM. If this value is Set, BMS can request Discharge-request to PDC during parking mode";
BA_ "GenSigSendType" SG_ 1167 PLBMAvailableState 4;
BA_ "UserSigValidity" SG_ 1167 PLBMAvailableState 0;
BA_ "Version" SG_ 1167 PLBMAvailableState "21.06.11";
BA_ "Description" SG_ 1167 IGN_AutoOff_WarnSta "This signal is for battery discharge warning (engine not running && IGN/ACC on)

To prevent battery discharge, ICU requests the head unit to display warning and requests IBU to turn IGN/ACC off.";
BA_ "GenSigSendType" SG_ 1167 IGN_AutoOff_WarnSta 4;
BA_ "UserSigValidity" SG_ 1167 IGN_AutoOff_WarnSta 3;
BA_ "Version" SG_ 1167 IGN_AutoOff_WarnSta "20.03.03";
BA_ "GenMsgSendType" BO_ 1171 0;
BA_ "Description" SG_ 1171 RLPSM_SWVerMajor1 "Indicate the SCM software version as follows:

- The software version is displayed in three digits.

- The Major and Minor digits are separated by '.'

- Signal values are transmitted to ASCII codes.



¡Ø Example

RLPSM_SWVerMajor1 : 0x41 (HEX) -> ASCII CODE : 'A' 

RLPSM_SWVerMinor1 : 0x30 (HEX) -> ASCII CODE : '0'

RLPSM_SWVerMinor2 : 0x33 (HEX) -> ASCII CODE : '3'

=> RLPSM S/W Ver is displayed 'A.03'";
BA_ "GenSigSendType" SG_ 1171 RLPSM_SWVerMajor1 4;
BA_ "UserSigValidity" SG_ 1171 RLPSM_SWVerMajor1 0;
BA_ "RoutingFactor" SG_ 1171 RLPSM_SWVerMajor1 0;
BA_ "Version" SG_ 1171 RLPSM_SWVerMajor1 "21.07.00";
BA_ "Description" SG_ 1171 RLPSM_SWVerMinor2 "Indicate the APSM software version as follows:

- The software version is displayed in three digits.

- The Major and Minor digits are separated by '.'

- Signal values are transmitted to ASCII codes.



¡Ø Example

RLPSM_SWVerMajor1 : 0x41 (HEX) -> ASCII CODE : 'A' 

RLPSM_SWVerMinor1 : 0x30 (HEX) -> ASCII CODE : '0'

RLPSM_SWVerMinor2 : 0x33 (HEX) -> ASCII CODE : '3'

=> RLPSM S/W Ver is displayed 'A.03'";
BA_ "GenSigSendType" SG_ 1171 RLPSM_SWVerMinor2 4;
BA_ "UserSigValidity" SG_ 1171 RLPSM_SWVerMinor2 0;
BA_ "RoutingFactor" SG_ 1171 RLPSM_SWVerMinor2 0;
BA_ "Version" SG_ 1171 RLPSM_SWVerMinor2 "20.04.06";
BA_ "Description" SG_ 1171 RLPSM_SWVerMinor1 "Indicate the APSM software version as follows:

- The software version is displayed in three digits.

- The Major and Minor digits are separated by '.'

- Signal values are transmitted to ASCII codes.



¡Ø Example

RLPSM_SWVerMajor1 : 0x41 (HEX) -> ASCII CODE : 'A' 

RLPSM_SWVerMinor1 : 0x30 (HEX) -> ASCII CODE : '0'

RLPSM_SWVerMinor2 : 0x33 (HEX) -> ASCII CODE : '3'

=> RLPSM S/W Ver is displayed 'A.03'";
BA_ "GenSigSendType" SG_ 1171 RLPSM_SWVerMinor1 4;
BA_ "UserSigValidity" SG_ 1171 RLPSM_SWVerMinor1 0;
BA_ "RoutingFactor" SG_ 1171 RLPSM_SWVerMinor1 0;
BA_ "Version" SG_ 1171 RLPSM_SWVerMinor1 "20.04.06";
BA_ "GenMsgCycleTime" BO_ 1181 0;
BA_ "Description" SG_ 1181 RL_SHVU_SeatEcoSta "ÈÄ¼® LH ½ÃÆ® ¿¡ÄÚÇÃ·¯½º ¸ðµå ÁøÀÔ Á¤º¸";
BA_ "GenSigSendType" SG_ 1181 RL_SHVU_SeatEcoSta 4;
BA_ "UserSigValidity" SG_ 1181 RL_SHVU_SeatEcoSta 3;
BA_REL_ "GenSigTimeoutTime" BU_SG_REL_ ATS SG_ 1181 RL_SHVU_SeatEcoSta 0;
BA_REL_ "GenSigTimeoutTime" BU_SG_REL_ CGW_CCU SG_ 1181 RL_SHVU_SeatEcoSta 0;
BA_ "NetworkRequest" SG_ 1181 RL_SHVU_SeatEcoSta 0;
BA_ "NetworkRequestHoldingTime" SG_ 1181 RL_SHVU_SeatEcoSta 5000;
BA_ "Version" SG_ 1181 RL_SHVU_SeatEcoSta "21.07.06";
BA_ "GenMsgSendType" BO_ 1172 0;
BA_ "Description" SG_ 1172 RRPSM_SWVerMajor1 "Indicate the SCM software version as follows:

- The software version is displayed in three digits.

- The Major and Minor digits are separated by '.'

- Signal values are transmitted to ASCII codes.



¡Ø Example

RRPSM_SWVerMajor1 : 0x41 (HEX) -> ASCII CODE : 'A' 

RRPSM_SWVerMinor1 : 0x30 (HEX) -> ASCII CODE : '0'

RRPSM_SWVerMinor2 : 0x33 (HEX) -> ASCII CODE : '3'

=> RRPSM S/W Ver is displayed 'A.03'";
BA_ "GenSigSendType" SG_ 1172 RRPSM_SWVerMajor1 4;
BA_ "UserSigValidity" SG_ 1172 RRPSM_SWVerMajor1 0;
BA_ "RoutingFactor" SG_ 1172 RRPSM_SWVerMajor1 0;
BA_ "Version" SG_ 1172 RRPSM_SWVerMajor1 "21.07.00";
BA_ "Description" SG_ 1172 RRPSM_SWVerMinor2 "Indicate the APSM software version as follows:

- The software version is displayed in three digits.

- The Major and Minor digits are separated by '.'

- Signal values are transmitted to ASCII codes.



¡Ø Example

RRPSM_SWVerMajor1 : 0x41 (HEX) -> ASCII CODE : 'A' 

RRPSM_SWVerMinor1 : 0x30 (HEX) -> ASCII CODE : '0'

RRPSM_SWVerMinor2 : 0x33 (HEX) -> ASCII CODE : '3'

=> RRPSM S/W Ver is displayed 'A.03'";
BA_ "GenSigSendType" SG_ 1172 RRPSM_SWVerMinor2 4;
BA_ "UserSigValidity" SG_ 1172 RRPSM_SWVerMinor2 0;
BA_ "RoutingFactor" SG_ 1172 RRPSM_SWVerMinor2 0;
BA_ "Version" SG_ 1172 RRPSM_SWVerMinor2 "20.04.06";
BA_ "Description" SG_ 1172 RRPSM_SWVerMinor1 "Indicate the APSM software version as follows:

- The software version is displayed in three digits.

- The Major and Minor digits are separated by '.'

- Signal values are transmitted to ASCII codes.



¡Ø Example

RRPSM_SWVerMajor1 : 0x41 (HEX) -> ASCII CODE : 'A' 

RRPSM_SWVerMinor1 : 0x30 (HEX) -> ASCII CODE : '0'

RRPSM_SWVerMinor2 : 0x33 (HEX) -> ASCII CODE : '3'

=> RRPSM S/W Ver is displayed 'A.03'";
BA_ "GenSigSendType" SG_ 1172 RRPSM_SWVerMinor1 4;
BA_ "UserSigValidity" SG_ 1172 RRPSM_SWVerMinor1 0;
BA_ "RoutingFactor" SG_ 1172 RRPSM_SWVerMinor1 0;
BA_ "Version" SG_ 1172 RRPSM_SWVerMinor1 "20.04.06";
BA_ "GenMsgCycleTime" BO_ 1182 0;
BA_ "Description" SG_ 1182 RR_SHVU_SeatEcoSta "ÈÄ¼® RH ½ÃÆ® ¿¡ÄÚÇÃ·¯½º ¸ðµå ÁøÀÔ Á¤º¸";
BA_ "GenSigSendType" SG_ 1182 RR_SHVU_SeatEcoSta 4;
BA_ "UserSigValidity" SG_ 1182 RR_SHVU_SeatEcoSta 3;
BA_REL_ "GenSigTimeoutTime" BU_SG_REL_ ATS SG_ 1182 RR_SHVU_SeatEcoSta 0;
BA_REL_ "GenSigTimeoutTime" BU_SG_REL_ CGW_CCU SG_ 1182 RR_SHVU_SeatEcoSta 0;
BA_ "NetworkRequest" SG_ 1182 RR_SHVU_SeatEcoSta 0;
BA_ "NetworkRequestHoldingTime" SG_ 1182 RR_SHVU_SeatEcoSta 5000;
BA_ "Version" SG_ 1182 RR_SHVU_SeatEcoSta "21.07.06";
BA_ "GenMsgSendType" BO_ 208 0;
BA_ "Description" SG_ 208 RR_SHVU_DTCdisplay "0x00: DTC is not exist(Fail is not exist)/0x01:IGN2 Fuse Open Detection/0x02:Switch Input Detection at Same Time/0x03:NTC/Heating wire Open Detection/0x04:NTC+/NTC- Terminal Short Detection/0x05:NTC+/Heater+ Terminal Short Detection/0x06:NTC+/Heater-, Heater+/Heater-, Heater+/NTC- Terminal Short Detection/0x07:NTC+/Heater- Wiring Short Detection/0x08:NTC+/Heater-, Heater+/Heater-, Heater+/NTC- Wiring Short Detection/0x09:Target Temperature Dissatisfied/0x0A:Blower+/Blower- Short, Blower+/Blower Speed, Blower-/Blower Speed Wiring Short Detection/0x0B:Blower+/Blower RPM, Blower-/Blower RPM, Blower Speed/Blower RPM Short Detection/0x0C:Blower+, Blower-, Blower Speed Signal open Detection/0x0D:Blower RPM signal Open Detection/0x0E~0xFD:Unused/0xFE:No Display/0xFF:Invalid";
BA_ "GenSigSendType" SG_ 208 RR_SHVU_DTCdisplay 4;
BA_ "UserSigValidity" SG_ 208 RR_SHVU_DTCdisplay 3;
BA_REL_ "GenSigTimeoutTime" BU_SG_REL_ ATS SG_ 208 RR_SHVU_DTCdisplay 1500;
BA_ "NetworkRequest" SG_ 208 RR_SHVU_DTCdisplay 0;
BA_ "NetworkRequestHoldingTime" SG_ 208 RR_SHVU_DTCdisplay 5000;
BA_ "Version" SG_ 208 RR_SHVU_DTCdisplay "19.11.06";
BA_ "Description" SG_ 208 RR_SHVU_DiagMode "0x0:Default/0x1:DTC Mode/0x2:Normal Mode/0x3:Invalid";
BA_ "GenSigSendType" SG_ 208 RR_SHVU_DiagMode 4;
BA_ "UserSigValidity" SG_ 208 RR_SHVU_DiagMode 3;
BA_REL_ "GenSigTimeoutTime" BU_SG_REL_ ATS SG_ 208 RR_SHVU_DiagMode 1500;
BA_ "NetworkRequest" SG_ 208 RR_SHVU_DiagMode 0;
BA_ "NetworkRequestHoldingTime" SG_ 208 RR_SHVU_DiagMode 5000;
BA_ "Version" SG_ 208 RR_SHVU_DiagMode "19.11.06";
BA_ "GenMsgSendType" BO_ 761 0;
BA_ "Description" SG_ 761 SBCM_AST_Crc3Val "The data area for CRC calculation is based on the data length (DLC) of the message DB.

The CRC shall be calculated over the entire data block (excluding the CRC bytes) including the user data, alive counter and Data ID 

 

- CRC Polynomial (0x1D) , Initial Value : 0x00, XOR value : 0xFF, Data ID Mode : Both, Data ID : Message ID + 0xF800 

- The initial value is for CRC calculation and the message should be sent with the calculated result value. 

The mathematical expression to 8 bit CRC polynomial is given here. G(x) = x8 + x4 + x3 + x2 + 1";
BA_ "GenSigSendType" SG_ 761 SBCM_AST_Crc3Val 4;
BA_ "GenSigStartValue" SG_ 761 SBCM_AST_Crc3Val 255;
BA_ "UserSigValidity" SG_ 761 SBCM_AST_Crc3Val 3;
BA_ "RoutingFactor" SG_ 761 SBCM_AST_Crc3Val 0;
BA_ "Version" SG_ 761 SBCM_AST_Crc3Val "20.12.04";
BA_ "GenSigSendType" SG_ 761 CDM_TypeOption_AST 4;
BA_ "UserSigValidity" SG_ 761 CDM_TypeOption_AST 7;
BA_ "NetworkRequest" SG_ 761 CDM_TypeOption_AST 0;
BA_ "NetworkRequestHoldingTime" SG_ 761 CDM_TypeOption_AST 5000;
BA_ "RoutingFactor" SG_ 761 CDM_TypeOption_AST 0;
BA_ "Version" SG_ 761 CDM_TypeOption_AST "20.12.04";
BA_ "Description" SG_ 761 SBCM_AST_AlvCnt3Val "For the first transmission request for a data element the counter shall be initialized with 0 and shall be incremented by 1

for every subsequent send request. When the counter reaches the maximum value(0xE), then it shall restart with 0 for the next send request";
BA_ "GenSigSendType" SG_ 761 SBCM_AST_AlvCnt3Val 4;
BA_ "UserSigValidity" SG_ 761 SBCM_AST_AlvCnt3Val 3;
BA_ "RoutingFactor" SG_ 761 SBCM_AST_AlvCnt3Val 0;
BA_ "Version" SG_ 761 SBCM_AST_AlvCnt3Val "20.12.04";
BA_ "GenSigSendType" SG_ 761 CDM_ImmeChgSw_AST 4;
BA_ "UserSigValidity" SG_ 761 CDM_ImmeChgSw_AST 7;
BA_ "NetworkRequest" SG_ 761 CDM_ImmeChgSw_AST 0;
BA_ "NetworkRequestHoldingTime" SG_ 761 CDM_ImmeChgSw_AST 5000;
BA_ "RoutingFactor" SG_ 761 CDM_ImmeChgSw_AST 0;
BA_ "Version" SG_ 761 CDM_ImmeChgSw_AST "20.12.04";
BA_ "GenSigSendType" SG_ 761 CDM_ChgDrSwFrt_AST 4;
BA_ "UserSigValidity" SG_ 761 CDM_ChgDrSwFrt_AST 7;
BA_ "NetworkRequest" SG_ 761 CDM_ChgDrSwFrt_AST 0;
BA_ "NetworkRequestHoldingTime" SG_ 761 CDM_ChgDrSwFrt_AST 5000;
BA_ "RoutingFactor" SG_ 761 CDM_ChgDrSwFrt_AST 0;
BA_ "Version" SG_ 761 CDM_ChgDrSwFrt_AST "20.12.04";
BA_ "GenSigSendType" SG_ 761 CDM_OpnClsState_AST 4;
BA_ "UserSigValidity" SG_ 761 CDM_OpnClsState_AST 7;
BA_ "NetworkRequest" SG_ 761 CDM_OpnClsState_AST 0;
BA_ "NetworkRequestHoldingTime" SG_ 761 CDM_OpnClsState_AST 5000;
BA_ "RoutingFactor" SG_ 761 CDM_OpnClsState_AST 0;
BA_ "Version" SG_ 761 CDM_OpnClsState_AST "20.12.04";
BA_ "GenSigSendType" SG_ 761 CDM_WarnMsg_AST 4;
BA_ "UserSigValidity" SG_ 761 CDM_WarnMsg_AST 7;
BA_ "NetworkRequest" SG_ 761 CDM_WarnMsg_AST 0;
BA_ "NetworkRequestHoldingTime" SG_ 761 CDM_WarnMsg_AST 5000;
BA_ "RoutingFactor" SG_ 761 CDM_WarnMsg_AST 0;
BA_ "Version" SG_ 761 CDM_WarnMsg_AST "20.12.04";
BA_ "GenSigSendType" SG_ 761 Mirror_RH_FoldingSta 4;
BA_ "UserSigValidity" SG_ 761 Mirror_RH_FoldingSta 0;
BA_ "NetworkRequest" SG_ 761 Mirror_RH_FoldingSta 0;
BA_ "NetworkRequestHoldingTime" SG_ 761 Mirror_RH_FoldingSta 5000;
BA_ "RoutingFactor" SG_ 761 Mirror_RH_FoldingSta 0;
BA_ "Version" SG_ 761 Mirror_RH_FoldingSta "20.12.04";
BA_ "GenSigSendType" SG_ 761 Mirror_RH_UnfoldingSta 4;
BA_ "UserSigValidity" SG_ 761 Mirror_RH_UnfoldingSta 0;
BA_ "NetworkRequest" SG_ 761 Mirror_RH_UnfoldingSta 0;
BA_ "NetworkRequestHoldingTime" SG_ 761 Mirror_RH_UnfoldingSta 5000;
BA_ "RoutingFactor" SG_ 761 Mirror_RH_UnfoldingSta 0;
BA_ "Version" SG_ 761 Mirror_RH_UnfoldingSta "20.12.04";
BA_ "GenSigSendType" SG_ 761 CDM_CmdStatus_AST 4;
BA_ "UserSigValidity" SG_ 761 CDM_CmdStatus_AST 7;
BA_ "NetworkRequest" SG_ 761 CDM_CmdStatus_AST 0;
BA_ "NetworkRequestHoldingTime" SG_ 761 CDM_CmdStatus_AST 5000;
BA_ "RoutingFactor" SG_ 761 CDM_CmdStatus_AST 0;
BA_ "Version" SG_ 761 CDM_CmdStatus_AST "20.12.04";
BA_ "GenSigSendType" SG_ 761 AST_CrashMRActAlarm 4;
BA_ "UserSigValidity" SG_ 761 AST_CrashMRActAlarm 0;
BA_ "NetworkRequest" SG_ 761 AST_CrashMRActAlarm 0;
BA_ "NetworkRequestHoldingTime" SG_ 761 AST_CrashMRActAlarm 5000;
BA_ "RoutingFactor" SG_ 761 AST_CrashMRActAlarm 0;
BA_ "Version" SG_ 761 AST_CrashMRActAlarm "20.12.05";
BA_ "GenSigSendType" SG_ 761 IMS_OSMirPlayBackSta_RH 4;
BA_ "UserSigValidity" SG_ 761 IMS_OSMirPlayBackSta_RH 0;
BA_REL_ "GenSigTimeoutTime" BU_SG_REL_ DPSU SG_ 761 IMS_OSMirPlayBackSta_RH 1500;
BA_ "NetworkRequest" SG_ 761 IMS_OSMirPlayBackSta_RH 0;
BA_ "NetworkRequestHoldingTime" SG_ 761 IMS_OSMirPlayBackSta_RH 5;
BA_ "RoutingFactor" SG_ 761 IMS_OSMirPlayBackSta_RH 0;
BA_ "Version" SG_ 761 IMS_OSMirPlayBackSta_RH "20.12.04";
BA_ "Description" SG_ 761 Mirror_RHVerPosVal "This signal indicates RH Outside Mirror Vertical Position Sensor Voltage";
BA_ "GenSigSendType" SG_ 761 Mirror_RHVerPosVal 4;
BA_ "UserSigValidity" SG_ 761 Mirror_RHVerPosVal 0;
BA_ "NetworkRequest" SG_ 761 Mirror_RHVerPosVal 0;
BA_ "NetworkRequestHoldingTime" SG_ 761 Mirror_RHVerPosVal 5000;
BA_ "RoutingFactor" SG_ 761 Mirror_RHVerPosVal 0;
BA_ "Version" SG_ 761 Mirror_RHVerPosVal "20.12.04";
BA_ "Description" SG_ 761 Mirror_RHHorPosVal "This signal indicates RH Outside Mirror Horizontal Position Sensor Voltage";
BA_ "GenSigSendType" SG_ 761 Mirror_RHHorPosVal 4;
BA_ "UserSigValidity" SG_ 761 Mirror_RHHorPosVal 0;
BA_ "NetworkRequest" SG_ 761 Mirror_RHHorPosVal 0;
BA_ "NetworkRequestHoldingTime" SG_ 761 Mirror_RHHorPosVal 5000;
BA_ "RoutingFactor" SG_ 761 Mirror_RHHorPosVal 0;
BA_ "Version" SG_ 761 Mirror_RHHorPosVal "20.12.04";
BA_ "GenSigSendType" SG_ 761 SBCM_AST_DiagSta 4;
BA_ "UserSigValidity" SG_ 761 SBCM_AST_DiagSta 0;
BA_ "NetworkRequest" SG_ 761 SBCM_AST_DiagSta 0;
BA_ "NetworkRequestHoldingTime" SG_ 761 SBCM_AST_DiagSta 5000;
BA_ "RoutingFactor" SG_ 761 SBCM_AST_DiagSta 0;
BA_ "Version" SG_ 761 SBCM_AST_DiagSta "20.12.04";
BA_ "GenMsgSendType" BO_ 758 0;
BA_ "Description" SG_ 758 SBCM_DRV_Crc2Val "The data area for CRC calculation is based on the data length (DLC) of the message DB.

The CRC shall be calculated over the entire data block (excluding the CRC bytes) including the user data, alive counter and Data ID 

 

- CRC Polynomial (0x1D) , Initial Value : 0x00, XOR value : 0xFF, Data ID Mode : Both, Data ID : Message ID + 0xF800 

- The initial value is for CRC calculation and the message should be sent with the calculated result value. 

The mathematical expression to 8 bit CRC polynomial is given here. G(x) = x8 + x4 + x3 + x2 + 1";
BA_ "GenSigSendType" SG_ 758 SBCM_DRV_Crc2Val 4;
BA_ "GenSigStartValue" SG_ 758 SBCM_DRV_Crc2Val 255;
BA_ "UserSigValidity" SG_ 758 SBCM_DRV_Crc2Val 3;
BA_ "RoutingFactor" SG_ 758 SBCM_DRV_Crc2Val 0;
BA_ "Version" SG_ 758 SBCM_DRV_Crc2Val "20.12.04";
BA_ "Description" SG_ 758 DoorLock_CtrlDrLkUnLkSwSta_SBCM "Central Door Lock/Unlock Switch State";
BA_ "GenSigSendType" SG_ 758 DoorLock_CtrlDrLkUnLkSwSta_SBCM 4;
BA_ "UserSigValidity" SG_ 758 DoorLock_CtrlDrLkUnLkSwSta_SBCM 0;
BA_ "NetworkRequest" SG_ 758 DoorLock_CtrlDrLkUnLkSwSta_SBCM 0;
BA_ "NetworkRequestHoldingTime" SG_ 758 DoorLock_CtrlDrLkUnLkSwSta_SBCM 5000;
BA_ "RoutingFactor" SG_ 758 DoorLock_CtrlDrLkUnLkSwSta_SBCM 0;
BA_ "Version" SG_ 758 DoorLock_CtrlDrLkUnLkSwSta_SBCM "20.12.04";
BA_ "Description" SG_ 758 SBCM_DRV_AlvCnt2Val "For the first transmission request for a data element the counter shall be initialized with 0 and shall be incremented by 1

for every subsequent send request. When the counter reaches the maximum value(0xE), then it shall restart with 0 for the next send request";
BA_ "GenSigSendType" SG_ 758 SBCM_DRV_AlvCnt2Val 4;
BA_ "UserSigValidity" SG_ 758 SBCM_DRV_AlvCnt2Val 3;
BA_ "RoutingFactor" SG_ 758 SBCM_DRV_AlvCnt2Val 0;
BA_ "Version" SG_ 758 SBCM_DRV_AlvCnt2Val "20.12.04";
BA_ "GenSigSendType" SG_ 758 SBCM_PsvDrLkReq 4;
BA_ "UserSigValidity" SG_ 758 SBCM_PsvDrLkReq 0;
BA_ "NetworkRequest" SG_ 758 SBCM_PsvDrLkReq 0;
BA_ "RoutingFactor" SG_ 758 SBCM_PsvDrLkReq 0;
BA_ "Version" SG_ 758 SBCM_PsvDrLkReq "21.01.03";
BA_ "GenSigSendType" SG_ 758 USM_DrvGhostDoorSta 4;
BA_ "UserSigValidity" SG_ 758 USM_DrvGhostDoorSta 0;
BA_ "NetworkRequest" SG_ 758 USM_DrvGhostDoorSta 0;
BA_ "NetworkRequestHoldingTime" SG_ 758 USM_DrvGhostDoorSta 5000;
BA_ "RoutingFactor" SG_ 758 USM_DrvGhostDoorSta 0;
BA_ "Version" SG_ 758 USM_DrvGhostDoorSta "21.03.11";
BA_ "GenSigSendType" SG_ 758 Mirror_LH_FoldingSta 4;
BA_ "UserSigValidity" SG_ 758 Mirror_LH_FoldingSta 0;
BA_ "NetworkRequest" SG_ 758 Mirror_LH_FoldingSta 0;
BA_ "NetworkRequestHoldingTime" SG_ 758 Mirror_LH_FoldingSta 5000;
BA_ "RoutingFactor" SG_ 758 Mirror_LH_FoldingSta 0;
BA_ "Version" SG_ 758 Mirror_LH_FoldingSta "20.12.04";
BA_ "GenSigSendType" SG_ 758 Mirror_LH_UnfoldingSta 4;
BA_ "UserSigValidity" SG_ 758 Mirror_LH_UnfoldingSta 0;
BA_ "NetworkRequest" SG_ 758 Mirror_LH_UnfoldingSta 0;
BA_ "NetworkRequestHoldingTime" SG_ 758 Mirror_LH_UnfoldingSta 5000;
BA_ "RoutingFactor" SG_ 758 Mirror_LH_UnfoldingSta 0;
BA_ "Version" SG_ 758 Mirror_LH_UnfoldingSta "20.12.04";
BA_ "GenSigSendType" SG_ 758 DRV_CrashMRActAlarm 4;
BA_ "UserSigValidity" SG_ 758 DRV_CrashMRActAlarm 0;
BA_ "NetworkRequest" SG_ 758 DRV_CrashMRActAlarm 0;
BA_ "NetworkRequestHoldingTime" SG_ 758 DRV_CrashMRActAlarm 5000;
BA_ "RoutingFactor" SG_ 758 DRV_CrashMRActAlarm 0;
BA_ "Version" SG_ 758 DRV_CrashMRActAlarm "20.12.04";
BA_ "GenSigSendType" SG_ 758 MirrorFldReq 4;
BA_ "UserSigValidity" SG_ 758 MirrorFldReq 0;
BA_ "NetworkRequest" SG_ 758 MirrorFldReq 0;
BA_ "NetworkRequestHoldingTime" SG_ 758 MirrorFldReq 5;
BA_ "RoutingFactor" SG_ 758 MirrorFldReq 0;
BA_ "Version" SG_ 758 MirrorFldReq "20.12.04";
BA_ "GenSigSendType" SG_ 758 OMU_TypeOption_DRV 4;
BA_ "UserSigValidity" SG_ 758 OMU_TypeOption_DRV 0;
BA_ "NetworkRequest" SG_ 758 OMU_TypeOption_DRV 0;
BA_ "NetworkRequestHoldingTime" SG_ 758 OMU_TypeOption_DRV 5000;
BA_ "RoutingFactor" SG_ 758 OMU_TypeOption_DRV 0;
BA_ "Version" SG_ 758 OMU_TypeOption_DRV "20.12.04";
BA_ "GenSigSendType" SG_ 758 IMS_OSMirPlayBackSta_LH 4;
BA_ "UserSigValidity" SG_ 758 IMS_OSMirPlayBackSta_LH 0;
BA_REL_ "GenSigTimeoutTime" BU_SG_REL_ DPSU SG_ 758 IMS_OSMirPlayBackSta_LH 1500;
BA_ "NetworkRequest" SG_ 758 IMS_OSMirPlayBackSta_LH 0;
BA_ "NetworkRequestHoldingTime" SG_ 758 IMS_OSMirPlayBackSta_LH 5;
BA_ "RoutingFactor" SG_ 758 IMS_OSMirPlayBackSta_LH 0;
BA_ "Version" SG_ 758 IMS_OSMirPlayBackSta_LH "20.12.04";
BA_ "Description" SG_ 758 ECMMRR_PLUS "This signal for passenger outside mirror OEC function(or ECM)

SBCM_DRV receive the ECM voltage value via H/wiring and then send this signal to SBCM_AST";
BA_ "GenSigSendType" SG_ 758 ECMMRR_PLUS 4;
BA_ "UserSigValidity" SG_ 758 ECMMRR_PLUS 0;
BA_ "NetworkRequest" SG_ 758 ECMMRR_PLUS 0;
BA_ "NetworkRequestHoldingTime" SG_ 758 ECMMRR_PLUS 5000;
BA_ "RoutingFactor" SG_ 758 ECMMRR_PLUS 0;
BA_ "Version" SG_ 758 ECMMRR_PLUS "20.12.04";
BA_ "Description" SG_ 758 Mirror_LHVerPosVal "This signal indicates LH Outside Mirror Vertical Position Sensor Voltage";
BA_ "GenSigSendType" SG_ 758 Mirror_LHVerPosVal 4;
BA_ "UserSigValidity" SG_ 758 Mirror_LHVerPosVal 0;
BA_ "NetworkRequest" SG_ 758 Mirror_LHVerPosVal 0;
BA_ "NetworkRequestHoldingTime" SG_ 758 Mirror_LHVerPosVal 5000;
BA_ "RoutingFactor" SG_ 758 Mirror_LHVerPosVal 0;
BA_ "Version" SG_ 758 Mirror_LHVerPosVal "20.12.04";
BA_ "Description" SG_ 758 Mirror_LHHorPosVal "This signal indicates LH Outside Mirror Horizontal Position Sensor Voltage";
BA_ "GenSigSendType" SG_ 758 Mirror_LHHorPosVal 4;
BA_ "UserSigValidity" SG_ 758 Mirror_LHHorPosVal 0;
BA_ "NetworkRequest" SG_ 758 Mirror_LHHorPosVal 0;
BA_ "NetworkRequestHoldingTime" SG_ 758 Mirror_LHHorPosVal 5000;
BA_ "RoutingFactor" SG_ 758 Mirror_LHHorPosVal 0;
BA_ "Version" SG_ 758 Mirror_LHHorPosVal "20.12.04";
BA_ "GenSigSendType" SG_ 758 SBCM_DRV_DiagSta 4;
BA_ "UserSigValidity" SG_ 758 SBCM_DRV_DiagSta 0;
BA_ "NetworkRequest" SG_ 758 SBCM_DRV_DiagSta 0;
BA_ "NetworkRequestHoldingTime" SG_ 758 SBCM_DRV_DiagSta 5000;
BA_ "RoutingFactor" SG_ 758 SBCM_DRV_DiagSta 0;
BA_ "Version" SG_ 758 SBCM_DRV_DiagSta "20.12.04";
BA_ "GenMsgSendType" BO_ 763 0;
BA_ "Description" SG_ 763 SBCM_DRV_Crc3Val "The data area for CRC calculation is based on the data length (DLC) of the message DB.

The CRC shall be calculated over the entire data block (excluding the CRC bytes) including the user data, alive counter and Data ID 

 

- CRC Polynomial (0x1D) , Initial Value : 0x00, XOR value : 0xFF, Data ID Mode : Both, Data ID : Message ID + 0xF800 

- The initial value is for CRC calculation and the message should be sent with the calculated result value. 

The mathematical expression to 8 bit CRC polynomial is given here. G(x) = x8 + x4 + x3 + x2 + 1";
BA_ "GenSigSendType" SG_ 763 SBCM_DRV_Crc3Val 4;
BA_ "GenSigStartValue" SG_ 763 SBCM_DRV_Crc3Val 255;
BA_ "UserSigValidity" SG_ 763 SBCM_DRV_Crc3Val 3;
BA_ "Version" SG_ 763 SBCM_DRV_Crc3Val "20.12.04";
BA_ "Description" SG_ 763 CDM_TypeOption "0x1 : On (CDM is applied)";
BA_ "GenSigSendType" SG_ 763 CDM_TypeOption 4;
BA_ "UserSigValidity" SG_ 763 CDM_TypeOption 7;
BA_ "NetworkRequest" SG_ 763 CDM_TypeOption 0;
BA_ "NetworkRequestHoldingTime" SG_ 763 CDM_TypeOption 5000;
BA_ "Version" SG_ 763 CDM_TypeOption "20.12.04";
BA_ "Description" SG_ 763 SBCM_DRV_AlvCnt3Val "For the first transmission request for a data element the counter shall be initialized with 0 and shall be incremented by 1

for every subsequent send request. When the counter reaches the maximum value(0xE), then it shall restart with 0 for the next send request";
BA_ "GenSigSendType" SG_ 763 SBCM_DRV_AlvCnt3Val 4;
BA_ "UserSigValidity" SG_ 763 SBCM_DRV_AlvCnt3Val 3;
BA_ "Version" SG_ 763 SBCM_DRV_AlvCnt3Val "20.12.04";
BA_ "Description" SG_ 763 CDM_ImmeChgSw_SBCM "State of Immediate Charging Switch";
BA_ "GenSigSendType" SG_ 763 CDM_ImmeChgSw_SBCM 4;
BA_ "UserSigValidity" SG_ 763 CDM_ImmeChgSw_SBCM 7;
BA_ "Version" SG_ 763 CDM_ImmeChgSw_SBCM "20.12.04";
BA_ "Description" SG_ 763 CDM_ChgDrSwFrt_SBCM "State of Front Charging Door Open Switch";
BA_ "GenSigSendType" SG_ 763 CDM_ChgDrSwFrt_SBCM 4;
BA_ "UserSigValidity" SG_ 763 CDM_ChgDrSwFrt_SBCM 7;
BA_ "Version" SG_ 763 CDM_ChgDrSwFrt_SBCM "20.12.04";
BA_ "Description" SG_ 763 CDM_OpnClsState_SBCM "This signal indicates CDM Open/Close Status";
BA_ "GenSigSendType" SG_ 763 CDM_OpnClsState_SBCM 4;
BA_ "UserSigValidity" SG_ 763 CDM_OpnClsState_SBCM 7;
BA_ "Version" SG_ 763 CDM_OpnClsState_SBCM "20.12.04";
BA_ "Description" SG_ 763 CDM_WarnMsg_SBCM "Command for CDM Warning on cluster";
BA_ "GenSigSendType" SG_ 763 CDM_WarnMsg_SBCM 4;
BA_ "UserSigValidity" SG_ 763 CDM_WarnMsg_SBCM 7;
BA_ "Version" SG_ 763 CDM_WarnMsg_SBCM "20.12.04";
BA_ "GenSigSendType" SG_ 763 CDM_AutoWashModeSta 4;
BA_ "UserSigValidity" SG_ 763 CDM_AutoWashModeSta 0;
BA_ "NetworkRequest" SG_ 763 CDM_AutoWashModeSta 0;
BA_ "NetworkRequestHoldingTime" SG_ 763 CDM_AutoWashModeSta 5000;
BA_ "Version" SG_ 763 CDM_AutoWashModeSta "22.02.00";
BA_ "Description" SG_ 763 CDM_CmdStatus_SBCM "User Condition Check For CDM Operation";
BA_ "GenSigSendType" SG_ 763 CDM_CmdStatus_SBCM 4;
BA_ "GenSigStartValue" SG_ 763 CDM_CmdStatus_SBCM 15;
BA_ "UserSigValidity" SG_ 763 CDM_CmdStatus_SBCM 7;
BA_ "Version" SG_ 763 CDM_CmdStatus_SBCM "20.12.04";
BA_ "GenSigSendType" SG_ 763 Warn_HoodSwSta_SBCM 4;
BA_ "UserSigValidity" SG_ 763 Warn_HoodSwSta_SBCM 0;
BA_REL_ "GenSigTimeoutTime" BU_SG_REL_ BLTN_CAM SG_ 763 Warn_HoodSwSta_SBCM 1500;
BA_ "NetworkRequest" SG_ 763 Warn_HoodSwSta_SBCM 0;
BA_ "NetworkRequestHoldingTime" SG_ 763 Warn_HoodSwSta_SBCM 5000;
BA_ "Version" SG_ 763 Warn_HoodSwSta_SBCM "21.09.08";
BA_ "Description" SG_ 763 Hood_TypeOption "If the E-Hood is applied, the signal will be send.";
BA_ "GenSigSendType" SG_ 763 Hood_TypeOption 4;
BA_ "UserSigValidity" SG_ 763 Hood_TypeOption 0;
BA_REL_ "GenSigTimeoutTime" BU_SG_REL_ BLTN_CAM SG_ 763 Hood_TypeOption 1500;
BA_ "NetworkRequest" SG_ 763 Hood_TypeOption 0;
BA_ "NetworkRequestHoldingTime" SG_ 763 Hood_TypeOption 5000;
BA_ "Version" SG_ 763 Hood_TypeOption "21.09.08";
BA_ "GenSigSendType" SG_ 763 SBCM_FrunkSta 4;
BA_ "UserSigValidity" SG_ 763 SBCM_FrunkSta 0;
BA_ "NetworkRequest" SG_ 763 SBCM_FrunkSta 0;
BA_ "NetworkRequestHoldingTime" SG_ 763 SBCM_FrunkSta 5000;
BA_ "Version" SG_ 763 SBCM_FrunkSta "22.01.06";
BA_ "GenSigSendType" SG_ 763 Warn_HoodSwFullSta_SBCM 4;
BA_ "UserSigValidity" SG_ 763 Warn_HoodSwFullSta_SBCM 0;
BA_ "NetworkRequest" SG_ 763 Warn_HoodSwFullSta_SBCM 0;
BA_ "NetworkRequestHoldingTime" SG_ 763 Warn_HoodSwFullSta_SBCM 5000;
BA_ "Version" SG_ 763 Warn_HoodSwFullSta_SBCM "22.01.06";
BA_ "GenSigSendType" SG_ 763 CDM_InsideOpnSwSta 4;
BA_ "UserSigValidity" SG_ 763 CDM_InsideOpnSwSta 7;
BA_ "NetworkRequest" SG_ 763 CDM_InsideOpnSwSta 0;
BA_ "NetworkRequestHoldingTime" SG_ 763 CDM_InsideOpnSwSta 5000;
BA_ "Version" SG_ 763 CDM_InsideOpnSwSta "20.12.04";
BA_ "GenMsgSendType" BO_ 742 0;
BA_ "Description" SG_ 742 SGU_OptTyp "This signal indicates if smart glass is installed and whta kind of smart glass is.

bit0 : Smart Glass Installation

bit1 : Smart Roof Glass

bit2 : Rear Smart Door Glass

bit3~bit7 : Reserved";
BA_ "GenSigSendType" SG_ 742 SGU_OptTyp 4;
BA_ "UserSigValidity" SG_ 742 SGU_OptTyp 0;
BA_ "RoutingFactor" SG_ 742 SGU_OptTyp 0;
BA_ "Version" SG_ 742 SGU_OptTyp "21.06.12";
BA_ "Description" SG_ 742 SGU_FltSta "SGU Fault Status";
BA_ "GenSigSendType" SG_ 742 SGU_FltSta 4;
BA_ "UserSigValidity" SG_ 742 SGU_FltSta 0;
BA_ "RoutingFactor" SG_ 742 SGU_FltSta 0;
BA_ "Version" SG_ 742 SGU_FltSta "21.07.04";
BA_ "Description" SG_ 742 SGU_BlindOnOffSet "Roll Blind Open/Close Control Set Value";
BA_ "GenSigSendType" SG_ 742 SGU_BlindOnOffSet 4;
BA_ "UserSigValidity" SG_ 742 SGU_BlindOnOffSet 0;
BA_REL_ "GenSigTimeoutTime" BU_SG_REL_ CGW_CCU SG_ 742 SGU_BlindOnOffSet 1500;
BA_ "RoutingFactor" SG_ 742 SGU_BlindOnOffSet 0;
BA_ "Version" SG_ 742 SGU_BlindOnOffSet "21.07.05";
BA_ "Description" SG_ 742 SGU_BlindOpenReq "This signal is for controlling a blind when SGU controls transparency of smart glass.";
BA_ "GenSigSendType" SG_ 742 SGU_BlindOpenReq 4;
BA_ "UserSigValidity" SG_ 742 SGU_BlindOpenReq 0;
BA_REL_ "GenSigTimeoutTime" BU_SG_REL_ RCM SG_ 742 SGU_BlindOpenReq 1500;
BA_ "RoutingFactor" SG_ 742 SGU_BlindOpenReq 0;
BA_ "Version" SG_ 742 SGU_BlindOpenReq "21.09.05";
BA_ "Description" SG_ 742 SGU_FltVal "SGU Fault Value";
BA_ "GenSigSendType" SG_ 742 SGU_FltVal 4;
BA_ "UserSigValidity" SG_ 742 SGU_FltVal 0;
BA_ "RoutingFactor" SG_ 742 SGU_FltVal 0;
BA_ "Version" SG_ 742 SGU_FltVal "21.07.04";
BA_ "Description" SG_ 742 SGU_Roof_OprLv "Roof Smart Glass Operation Level";
BA_ "GenSigSendType" SG_ 742 SGU_Roof_OprLv 4;
BA_ "UserSigValidity" SG_ 742 SGU_Roof_OprLv 0;
BA_REL_ "GenSigTimeoutTime" BU_SG_REL_ CGW_CCU SG_ 742 SGU_Roof_OprLv 1500;
BA_ "RoutingFactor" SG_ 742 SGU_Roof_OprLv 0;
BA_ "Version" SG_ 742 SGU_Roof_OprLv "21.09.00";
BA_ "Description" SG_ 742 SGU_2ndLeftDoor_OprLv "2nd Row Left Door Smart Glass Operation Level";
BA_ "GenSigSendType" SG_ 742 SGU_2ndLeftDoor_OprLv 4;
BA_ "UserSigValidity" SG_ 742 SGU_2ndLeftDoor_OprLv 0;
BA_REL_ "GenSigTimeoutTime" BU_SG_REL_ CGW_CCU SG_ 742 SGU_2ndLeftDoor_OprLv 1500;
BA_ "RoutingFactor" SG_ 742 SGU_2ndLeftDoor_OprLv 0;
BA_ "Version" SG_ 742 SGU_2ndLeftDoor_OprLv "21.09.00";
BA_ "Description" SG_ 742 SGU_2ndRightDoor_OprLv "2nd Row Right Door Smart Glass Operation Level";
BA_ "GenSigSendType" SG_ 742 SGU_2ndRightDoor_OprLv 4;
BA_ "UserSigValidity" SG_ 742 SGU_2ndRightDoor_OprLv 0;
BA_REL_ "GenSigTimeoutTime" BU_SG_REL_ CGW_CCU SG_ 742 SGU_2ndRightDoor_OprLv 1500;
BA_ "RoutingFactor" SG_ 742 SGU_2ndRightDoor_OprLv 0;
BA_ "Version" SG_ 742 SGU_2ndRightDoor_OprLv "21.09.00";
BA_ "Description" SG_ 742 SGU_3rdLeftDoor_OprLv "3rd Row Left Door Smart Glass Operation Level";
BA_ "GenSigSendType" SG_ 742 SGU_3rdLeftDoor_OprLv 4;
BA_ "UserSigValidity" SG_ 742 SGU_3rdLeftDoor_OprLv 0;
BA_REL_ "GenSigTimeoutTime" BU_SG_REL_ CGW_CCU SG_ 742 SGU_3rdLeftDoor_OprLv 1500;
BA_ "RoutingFactor" SG_ 742 SGU_3rdLeftDoor_OprLv 0;
BA_ "Version" SG_ 742 SGU_3rdLeftDoor_OprLv "21.09.00";
BA_ "Description" SG_ 742 SGU_3rdRightDoor_OprLv "3rd Row Right Door Smart Glass Operation Level";
BA_ "GenSigSendType" SG_ 742 SGU_3rdRightDoor_OprLv 4;
BA_ "UserSigValidity" SG_ 742 SGU_3rdRightDoor_OprLv 0;
BA_REL_ "GenSigTimeoutTime" BU_SG_REL_ CGW_CCU SG_ 742 SGU_3rdRightDoor_OprLv 1500;
BA_ "RoutingFactor" SG_ 742 SGU_3rdRightDoor_OprLv 0;
BA_ "Version" SG_ 742 SGU_3rdRightDoor_OprLv "21.09.00";
BA_ "Description" SG_ 742 SGU_RearWindow_OprLv "Rear Window Smart Glass Operation Level";
BA_ "GenSigSendType" SG_ 742 SGU_RearWindow_OprLv 4;
BA_ "UserSigValidity" SG_ 742 SGU_RearWindow_OprLv 0;
BA_REL_ "GenSigTimeoutTime" BU_SG_REL_ CGW_CCU SG_ 742 SGU_RearWindow_OprLv 1500;
BA_ "RoutingFactor" SG_ 742 SGU_RearWindow_OprLv 0;
BA_ "Version" SG_ 742 SGU_RearWindow_OprLv "21.09.00";
BA_ "Description" SG_ 742 SGU_OprLvVehicleSet "Smart Glass Maximum Operation Level Setting Value for each vechicles";
BA_ "GenSigSendType" SG_ 742 SGU_OprLvVehicleSet 4;
BA_ "UserSigValidity" SG_ 742 SGU_OprLvVehicleSet 0;
BA_REL_ "GenSigTimeoutTime" BU_SG_REL_ CGW_CCU SG_ 742 SGU_OprLvVehicleSet 1500;
BA_ "RoutingFactor" SG_ 742 SGU_OprLvVehicleSet 0;
BA_ "Version" SG_ 742 SGU_OprLvVehicleSet "21.11.05";
BA_ "Description" SG_ 742 SGU_RdySta "SGU Ready Status";
BA_ "GenSigSendType" SG_ 742 SGU_RdySta 4;
BA_ "UserSigValidity" SG_ 742 SGU_RdySta 0;
BA_ "RoutingFactor" SG_ 742 SGU_RdySta 0;
BA_ "Version" SG_ 742 SGU_RdySta "21.07.04";
BA_ "GenMsgSendType" BO_ 2328016129 0;
BA_ "GenMsgCycleTimeFast" BO_ 2328016129 0;
BA_ "GenMsgNrOfRepetition" BO_ 2328016129 0;
BA_ "VFrameFormat" BO_ 2328016129 1;
BA_ "Description" SG_ 2328016129 VCU_Crc5Val "The data area for CRC calculation is based on the data length (DLC) of the message DB.

The CRC shall be calculated over the entire data block (excluding the CRC bytes) including the user data, alive counter and Data ID

 

- CRC Polynomial (0x1021) , Initial Value : 0xFFFF, XOR value : 0x0000, Data ID : Message ID + 0xF800 

- The initial value is for CRC calculation and the message should be sent with the calculated result value. 

- The mathematical expression to 16 bit CRC polynomial is given here. G(x) = x16 + x12 + x5 + 1";
BA_ "GenSigStartValue" SG_ 2328016129 VCU_Crc5Val 65535;
BA_ "UserSigValidity" SG_ 2328016129 VCU_Crc5Val 7;
BA_ "RoutingFactor" SG_ 2328016129 VCU_Crc5Val 2;
BA_ "Version" SG_ 2328016129 VCU_Crc5Val "20.07.05";
BA_ "Description" SG_ 2328016129 VCU_AlvCnt5Val "For the first transmission request for a data element the counter shall be initialized with 0 and shall be incremented by 1 for every subsequent send request. 

When the counter reaches the maximum value(0xFF), then it shall restart with 0 for the next send request";
BA_ "UserSigValidity" SG_ 2328016129 VCU_AlvCnt5Val 7;
BA_ "RoutingFactor" SG_ 2328016129 VCU_AlvCnt5Val 2;
BA_ "Version" SG_ 2328016129 VCU_AlvCnt5Val "20.07.05";
BA_ "Description" SG_ 2328016129 VCU_EvDrvRdyCluDispSta "EV Drive Ready for Cluster Display Only";
BA_ "UserSigValidity" SG_ 2328016129 VCU_EvDrvRdyCluDispSta 7;
BA_REL_ "GenSigTimeoutTime" BU_SG_REL_ SWRC SG_ 2328016129 VCU_EvDrvRdyCluDispSta 1500;
BA_ "RoutingFactor" SG_ 2328016129 VCU_EvDrvRdyCluDispSta 2;
BA_ "Version" SG_ 2328016129 VCU_EvDrvRdyCluDispSta "19.09.05";
BA_ "Description" SG_ 2328016129 VCU_PwrDnModeSta "Power Down Mode";
BA_ "UserSigValidity" SG_ 2328016129 VCU_PwrDnModeSta 7;
BA_ "RoutingFactor" SG_ 2328016129 VCU_PwrDnModeSta 2;
BA_ "Version" SG_ 2328016129 VCU_PwrDnModeSta "19.03.03";
BA_ "Description" SG_ 2328016129 VCU_CluWarnMsgSta "Cluster Warning Message";
BA_ "UserSigValidity" SG_ 2328016129 VCU_CluWarnMsgSta 7;
BA_ "RoutingFactor" SG_ 2328016129 VCU_CluWarnMsgSta 2;
BA_ "Version" SG_ 2328016129 VCU_CluWarnMsgSta "19.03.03";
BA_ "Description" SG_ 2328016129 VCU_DteOffDispSta "DTE Off('---' Display)";
BA_ "UserSigValidity" SG_ 2328016129 VCU_DteOffDispSta 7;
BA_ "RoutingFactor" SG_ 2328016129 VCU_DteOffDispSta 2;
BA_ "Version" SG_ 2328016129 VCU_DteOffDispSta "19.06.02";
BA_ "Description" SG_ 2328016129 VCU_LowSocAlertSta "Low SOC Alert of High-Voltage Battery";
BA_ "UserSigValidity" SG_ 2328016129 VCU_LowSocAlertSta 7;
BA_ "RoutingFactor" SG_ 2328016129 VCU_LowSocAlertSta 2;
BA_ "Version" SG_ 2328016129 VCU_LowSocAlertSta "19.03.03";
BA_ "Description" SG_ 2328016129 VCU_VcrmReq "VCRM Trigger Signal(Request VCRM Data Logging)";
BA_ "UserSigValidity" SG_ 2328016129 VCU_VcrmReq 7;
BA_ "RoutingFactor" SG_ 2328016129 VCU_VcrmReq 2;
BA_ "Version" SG_ 2328016129 VCU_VcrmReq "19.03.03";
BA_ "UserSigValidity" SG_ 2328016129 VCU_PdlWarnMsgSta 7;
BA_ "RoutingFactor" SG_ 2328016129 VCU_PdlWarnMsgSta 2;
BA_ "Version" SG_ 2328016129 VCU_PdlWarnMsgSta "19.03.03";
BA_ "Description" SG_ 2328016129 VCU_AwdDiagDispSta "e4WD Diagnosis Display Status";
BA_ "UserSigValidity" SG_ 2328016129 VCU_AwdDiagDispSta 7;
BA_ "RoutingFactor" SG_ 2328016129 VCU_AwdDiagDispSta 2;
BA_ "Version" SG_ 2328016129 VCU_AwdDiagDispSta "20.01.00";
BA_ "Description" SG_ 2328016129 VCU_AwdLockDispSta "e4WD Lock Mode Display Status";
BA_ "UserSigValidity" SG_ 2328016129 VCU_AwdLockDispSta 7;
BA_ "RoutingFactor" SG_ 2328016129 VCU_AwdLockDispSta 2;
BA_ "Version" SG_ 2328016129 VCU_AwdLockDispSta "20.01.00";
BA_ "Description" SG_ 2328016129 VCU_VirtualApsActSta "Virtual APS Activated";
BA_ "UserSigValidity" SG_ 2328016129 VCU_VirtualApsActSta 7;
BA_ "RoutingFactor" SG_ 2328016129 VCU_VirtualApsActSta 2;
BA_ "Version" SG_ 2328016129 VCU_VirtualApsActSta "19.03.03";
BA_ "Description" SG_ 2328016129 VCU_VirtualApsVal "Estimated Accelerator Pedal Value when Auto Cruise Mode";
BA_ "UserSigValidity" SG_ 2328016129 VCU_VirtualApsVal 7;
BA_ "RoutingFactor" SG_ 2328016129 VCU_VirtualApsVal 2;
BA_ "Version" SG_ 2328016129 VCU_VirtualApsVal "19.03.03";
BA_ "Description" SG_ 2328016129 VCU_ServiceLampReq "Sevice Lamp Request";
BA_ "UserSigValidity" SG_ 2328016129 VCU_ServiceLampReq 7;
BA_ "RoutingFactor" SG_ 2328016129 VCU_ServiceLampReq 2;
BA_ "Version" SG_ 2328016129 VCU_ServiceLampReq "19.03.03";
BA_ "Description" SG_ 2328016129 VCU_ServiceModeSta "Service Mode";
BA_ "UserSigValidity" SG_ 2328016129 VCU_ServiceModeSta 7;
BA_ "RoutingFactor" SG_ 2328016129 VCU_ServiceModeSta 2;
BA_ "Version" SG_ 2328016129 VCU_ServiceModeSta "20.10.00";
BA_ "Description" SG_ 2328016129 VCU_NPosWshModSta "N Wash Mode Status";
BA_ "UserSigValidity" SG_ 2328016129 VCU_NPosWshModSta 7;
BA_ "RoutingFactor" SG_ 2328016129 VCU_NPosWshModSta 2;
BA_ "Version" SG_ 2328016129 VCU_NPosWshModSta "19.07.06";
BA_ "Description" SG_ 2328016129 VCU_PowerTrainType "VCU_PowerTrainType";
BA_ "UserSigValidity" SG_ 2328016129 VCU_PowerTrainType 7;
BA_ "RoutingFactor" SG_ 2328016129 VCU_PowerTrainType 2;
BA_ "Version" SG_ 2328016129 VCU_PowerTrainType "19.03.03";
BA_ "GenMsgSendType" BO_ 2328016130 0;
BA_ "GenMsgCycleTimeFast" BO_ 2328016130 0;
BA_ "GenMsgNrOfRepetition" BO_ 2328016130 0;
BA_ "VFrameFormat" BO_ 2328016130 1;
BA_ "Description" SG_ 2328016130 VCU_DteBaseVal "Maximum Drivable Distance_Adaption";
BA_ "UserSigValidity" SG_ 2328016130 VCU_DteBaseVal 7;
BA_ "RoutingFactor" SG_ 2328016130 VCU_DteBaseVal 2;
BA_ "Version" SG_ 2328016130 VCU_DteBaseVal "19.03.03";
BA_ "Description" SG_ 2328016130 VCU_AvnDteOnCalcSta "DTE calculation status";
BA_ "UserSigValidity" SG_ 2328016130 VCU_AvnDteOnCalcSta 7;
BA_ "RoutingFactor" SG_ 2328016130 VCU_AvnDteOnCalcSta 2;
BA_ "Version" SG_ 2328016130 VCU_AvnDteOnCalcSta "19.03.03";
BA_ "Description" SG_ 2328016130 VCU_SbwWarnMsgSta "SBW Warning Message";
BA_ "UserSigValidity" SG_ 2328016130 VCU_SbwWarnMsgSta 7;
BA_ "RoutingFactor" SG_ 2328016130 VCU_SbwWarnMsgSta 2;
BA_ "Version" SG_ 2328016130 VCU_SbwWarnMsgSta "19.06.02";
BA_ "Description" SG_ 2328016130 VCU_DteNaviRouteVal "Drivable distance for calculation AVN DTE";
BA_ "UserSigValidity" SG_ 2328016130 VCU_DteNaviRouteVal 7;
BA_ "RoutingFactor" SG_ 2328016130 VCU_DteNaviRouteVal 2;
BA_ "Version" SG_ 2328016130 VCU_DteNaviRouteVal "19.03.03";
BA_ "Description" SG_ 2328016130 VCU_DteAddVal "Added Drivable Distance by DATC Off";
BA_ "UserSigValidity" SG_ 2328016130 VCU_DteAddVal 7;
BA_ "RoutingFactor" SG_ 2328016130 VCU_DteAddVal 2;
BA_ "Version" SG_ 2328016130 VCU_DteAddVal "19.03.03";
BA_ "Description" SG_ 2328016130 VCU_PwrGaugeVal "Motor Torque Ratio To Cluster

:VCU send this signal to cluster to show motor power status";
BA_ "UserSigValidity" SG_ 2328016130 VCU_PwrGaugeVal 7;
BA_ "RoutingFactor" SG_ 2328016130 VCU_PwrGaugeVal 2;
BA_ "Version" SG_ 2328016130 VCU_PwrGaugeVal "19.03.03";
BA_ "Description" SG_ 2328016130 VCU_EnergyFlowSta "Energy Flow Display Status";
BA_ "UserSigValidity" SG_ 2328016130 VCU_EnergyFlowSta 7;
BA_ "RoutingFactor" SG_ 2328016130 VCU_EnergyFlowSta 2;
BA_ "Version" SG_ 2328016130 VCU_EnergyFlowSta "20.09.00";
BA_ "Description" SG_ 2328016130 VCU_SbwWarnSndSta "SBW Warning Sound";
BA_ "UserSigValidity" SG_ 2328016130 VCU_SbwWarnSndSta 7;
BA_ "RoutingFactor" SG_ 2328016130 VCU_SbwWarnSndSta 2;
BA_ "Version" SG_ 2328016130 VCU_SbwWarnSndSta "19.06.02";
BA_ "Description" SG_ 2328016130 VCU_EcoGuide_DispReq "Display On/Off";
BA_ "UserSigValidity" SG_ 2328016130 VCU_EcoGuide_DispReq 7;
BA_ "RoutingFactor" SG_ 2328016130 VCU_EcoGuide_DispReq 2;
BA_ "Version" SG_ 2328016130 VCU_EcoGuide_DispReq "19.03.03";
BA_ "Description" SG_ 2328016130 VCU_EcoGuide_ApsGaugeVal "APS Gauge Display for Smart ECO Guide";
BA_ "UserSigValidity" SG_ 2328016130 VCU_EcoGuide_ApsGaugeVal 7;
BA_ "RoutingFactor" SG_ 2328016130 VCU_EcoGuide_ApsGaugeVal 2;
BA_ "Version" SG_ 2328016130 VCU_EcoGuide_ApsGaugeVal "19.03.03";
BA_ "Description" SG_ 2328016130 VCU_EcoGuide_EcoGaugeVal "ECO Range Display for Smart ECO Guide";
BA_ "UserSigValidity" SG_ 2328016130 VCU_EcoGuide_EcoGaugeVal 7;
BA_ "RoutingFactor" SG_ 2328016130 VCU_EcoGuide_EcoGaugeVal 2;
BA_ "Version" SG_ 2328016130 VCU_EcoGuide_EcoGaugeVal "19.03.03";
BA_ "GenMsgSendType" BO_ 2328016131 0;
BA_ "GenMsgCycleTimeFast" BO_ 2328016131 0;
BA_ "GenMsgNrOfRepetition" BO_ 2328016131 0;
BA_ "VFrameFormat" BO_ 2328016131 1;
BA_ "Description" SG_ 2328016131 VCU_TgSocDteAcChgVal "Estimated DTE for slow charger(SC/AC) target SOC";
BA_ "UserSigValidity" SG_ 2328016131 VCU_TgSocDteAcChgVal 7;
BA_ "RoutingFactor" SG_ 2328016131 VCU_TgSocDteAcChgVal 2;
BA_ "Version" SG_ 2328016131 VCU_TgSocDteAcChgVal "19.03.03";
BA_ "Description" SG_ 2328016131 VCU_TgSocDteDcChgVal "Estimated DTE for fast charger(QC/DC) target SOC";
BA_ "UserSigValidity" SG_ 2328016131 VCU_TgSocDteDcChgVal 7;
BA_ "RoutingFactor" SG_ 2328016131 VCU_TgSocDteDcChgVal 2;
BA_ "Version" SG_ 2328016131 VCU_TgSocDteDcChgVal "19.03.03";
BA_ "Description" SG_ 2328016131 VCU_DistFromRegenDispReq "Distance from Regeneration Display status";
BA_ "UserSigValidity" SG_ 2328016131 VCU_DistFromRegenDispReq 7;
BA_ "RoutingFactor" SG_ 2328016131 VCU_DistFromRegenDispReq 2;
BA_ "Version" SG_ 2328016131 VCU_DistFromRegenDispReq "19.03.03";
BA_ "Description" SG_ 2328016131 VCU_DistFromRegenVal "DTE Increment at Regeneration";
BA_ "UserSigValidity" SG_ 2328016131 VCU_DistFromRegenVal 7;
BA_ "RoutingFactor" SG_ 2328016131 VCU_DistFromRegenVal 2;
BA_ "Version" SG_ 2328016131 VCU_DistFromRegenVal "19.03.03";
BA_ "Description" SG_ 2328016131 VCU_DrvStyle_DispReq "Fuel Efficiency Percent Display Status";
BA_ "UserSigValidity" SG_ 2328016131 VCU_DrvStyle_DispReq 7;
BA_ "RoutingFactor" SG_ 2328016131 VCU_DrvStyle_DispReq 2;
BA_ "Version" SG_ 2328016131 VCU_DrvStyle_DispReq "19.03.03";
BA_ "Description" SG_ 2328016131 VCU_DrvStyle_HighLightSta "Fuel Efficiency High Light Status";
BA_ "UserSigValidity" SG_ 2328016131 VCU_DrvStyle_HighLightSta 7;
BA_ "RoutingFactor" SG_ 2328016131 VCU_DrvStyle_HighLightSta 2;
BA_ "Version" SG_ 2328016131 VCU_DrvStyle_HighLightSta "19.03.03";
BA_ "Description" SG_ 2328016131 VCU_DrvStyle_EcoVal "High Fuel Efficiency Percent Value";
BA_ "UserSigValidity" SG_ 2328016131 VCU_DrvStyle_EcoVal 7;
BA_ "RoutingFactor" SG_ 2328016131 VCU_DrvStyle_EcoVal 2;
BA_ "Version" SG_ 2328016131 VCU_DrvStyle_EcoVal "19.03.03";
BA_ "Description" SG_ 2328016131 VCU_DrvStyle_NonEcoVal "Low Fuel Efficiency Percent Value";
BA_ "UserSigValidity" SG_ 2328016131 VCU_DrvStyle_NonEcoVal 7;
BA_ "RoutingFactor" SG_ 2328016131 VCU_DrvStyle_NonEcoVal 2;
BA_ "Version" SG_ 2328016131 VCU_DrvStyle_NonEcoVal "19.03.03";
BA_ "Description" SG_ 2328016131 VCU_DrvStyle_NorVal "Normal Fuel Efficiency Percent Value";
BA_ "UserSigValidity" SG_ 2328016131 VCU_DrvStyle_NorVal 7;
BA_ "RoutingFactor" SG_ 2328016131 VCU_DrvStyle_NorVal 2;
BA_ "Version" SG_ 2328016131 VCU_DrvStyle_NorVal "19.03.03";
VAL_ 223 ALBCU_SmartCtrl_1h 0 "Default" 1 "Group1" 2 "Group2" 3 "Group3" 4 "Group4" 5 "Group5" 6 "Group6" 7 "Group7" 8 "Group8" 9 "Group9" 10 "General Group" 11 "Unused" 12 "Unused" 13 "Unused" 14 "Unused" 15 "Invalid" ;
VAL_ 223 ALBCU_SmartCtrl_2h 0 "Default" 1 "Group1" 2 "Group2" 3 "Group3" 4 "Group4" 5 "Group5" 6 "Group6" 7 "Group7" 8 "Group8" 9 "Group9" 10 "General Group" 11 "Unused" 12 "Unused" 13 "Unused" 14 "Unused" 15 "Invalid" ;
VAL_ 223 ALBCU_SmartCtrl_Status 0 "Default" 1 "Start" 2 "Finished" 3 "Stop" 4 "Unused" 5 "Unused" 6 "Unused" 7 "Invalid" ;
VAL_ 1180 SHVU_Ast_Beep1Sound 0 "Beep1 mode Off" 1 "Beep1 mode On" 2 "Unused" 3 "Invalid" ;
VAL_ 1180 Ast_SHVU_SeatEcoSta 0 "Off(Initial Value)" 1 "On" 2 "Not Used" 3 "Error Indicator" ;
VAL_ 2315421697 CCU_OTA_mode 0 "idle" 1 "Download" 2 "BackgroundSend" 3 "UpdateReady_bf_apv" 4 "UpdateReady_af_apv" 5 "Update_preprocess" 6 "Update_PE" 7 "Update_other" ;
VAL_ 2315421697 CCU_OTA_IG3On_request 0 "off(Default)" 1 "on" 2 "Not used" 3 "Error Indicator" ;
VAL_ 2315421697 OTA_Cond_Vehicle_Pwr 0 "NoDisplay" 1 "OK" 2 "NOK" 3 "Reserved" ;
VAL_ 2315421697 OTA_Cond_Gear_P 0 "NoDisplay" 1 "OK" 2 "NOK" 3 "Reserved" ;
VAL_ 2315421697 OTA_Cond_Parking_Brk 0 "NoDisplay" 1 "OK" 2 "NOK" 3 "Reserved" ;
VAL_ 2315421697 OTA_Cond_Ext_Lamp 0 "NoDisplay" 1 "OK" 2 "NOK" 3 "Reserved" ;
VAL_ 2315421697 OTA_Cond_Hood_Closed 0 "NoDisplay" 1 "OK" 2 "NOK" 3 "Reserved" ;
VAL_ 2315421697 CCU_OTA_Tele_Cranking 0 "default (off)" 1 "IGN1 on, Cranking" 2 "IGN1 on" 3 "Stop" 7 "Error Indicator" ;
VAL_ 2315421697 OTA_UI_Ready_request 0 "off (default)" 1 "ON" 2 "Not Used" 3 "Error Indicator" ;
VAL_ 2315421697 OTA_Result 0 "Default" 1 "Success" 2 "failed_rollback_complete" 3 "failed_rollback_failed" ;
VAL_ 2315421697 CF_AVN_InterAutoLockMode_Set2_Copy_1 0 "Default" 1 "Auto Mode" 2 "Lock Mode" 3 "Unlock Mode" 4 "Reserved" 5 "Reserved" 6 "Reserved" 7 "Invalid" ;
VAL_ 2315421697 CCU_OTA_EOU 0 "OFF" 1 "ON" 2 "Reserved" 3 "Invalid" ;
VAL_ 2290230529 CLU_DTEVal 0 "Valid DTE 0 (Display '---')" 1 "0x1~0xFFE:Valid DTE (1 ~ 4094 km)" 4094 "0x1~0xFFE:Valid DTE (1 ~ 4094 km)" 4095 "Invalid(Display '---' Blink)" ;
VAL_ 2290230529 CLU_TripUnitSta 0 "Not Used" 1 "km" 2 "mile" 3 "Invailid" ;
VAL_ 2290230529 CLU_LoFuelWrngSta 0 "Low fuel Warning is off" 1 "Low fuel Warning is on" 2 "Not used" 3 "Invalid" ;
VAL_ 2290230529 CLU_RefuelDetSta 0 "Non refuel detected" 1 "Refuel detected" 2 "Not used" 3 "Error Indicator" ;
VAL_ 2290230529 CLU_TerrainMainSwSta 0 "Default" 1 "On-Road" 2 "Off-Road" 3 "Reserved" ;
VAL_ 2290230530 CLU_LngSta 0 "Off" 1 "Korean" 2 "English(US)" 3 "English(UK)" 4 "Chinese(Mandarin)" 5 "Chinese(Cantonese)" 6 "French(EU)" 7 "Spanish(EU)" 8 "Arabic" 9 "Czech" 10 "Danish" 11 "German" 12 "Italian" 13 "Dutch" 14 "Polish" 15 "Portuguese" 16 "Russian" 17 "Slovak" 18 "Swedish" 19 "Turkish" 20 "French(US)" 21 "Spanish(US)" 22 "Reserved" 23 "Reserved" 24 "Reserved" 25 "Reserved" 26 "Reserved" 27 "Reserved" 28 "Reserved" 29 "Reserved" 30 "Reserved" 31 "Invalid" ;
VAL_ 2290230530 CLU_RefuelWrnSta 0 "Refuel Popup is off" 1 "Refuel Popup is on" 2 "Reserved" 3 "Invalid" ;
VAL_ 2290230530 CLU_IceWrnIndSta 0 "Off" 1 "On" 2 "Not used" 3 "Error Indicator" ;
VAL_ 2290230530 CLU_DrvngModSwSta 0 "Off" 1 "Normal" 2 "Eco" 3 "Sport" 4 "Sport+" 5 "Smart" 6 "Custom(Custom#1_N)" 7 "N-mode" 8 "Reserved" 9 "Custom#2_N" 10 "Reserved" 11 "Reserved" 12 "Reserved" 13 "Reserved" 14 "Reserved" 15 "Invalid" ;
VAL_ 2290230530 CLU_FuelLvlSta 0 "0x0x0~0x64:0%~100%" 100 "0x0x0~0x64:0%~100%" 101 "Reserved" 102 "Reserved" 103 "Reserved" 104 "Reserved" 105 "Reserved" 106 "Reserved" 107 "Reserved" 108 "Reserved" 109 "Reserved" 110 "Reserved" 111 "Reserved" 112 "Reserved" 113 "Reserved" 114 "Reserved" 115 "Reserved" 116 "Reserved" 117 "Reserved" 118 "Reserved" 119 "Reserved" 120 "Reserved" 121 "Reserved" 122 "Reserved" 123 "Reserved" 124 "Reserved" 125 "Reserved" 126 "Reserved" 127 "Invalid(Error)" ;
VAL_ 2290230530 CLU_SRSWrngLmpSta 0 "Lamp OFF" 1 "Lamp On" 2 "Lamp Flashing" 3 "ACU message error" 7 "Lamp Circuit Failure" ;
VAL_ 2290230530 CLU_TerrainModSwSta 0 "Default" 1 "Snow" 2 "Sand" 3 "Mud" 4 "Auto" 5 "Deep Snow" 6 "Reserved" 7 "Reserved" ;
VAL_ 2290230530 CLU_OdoVal 16777215 "Error" ;
VAL_ 2470763009 USM_MdLmpClrSetReq 0 "Default" 1 "color 1" 2 "color 2" 3 "color 3" 4 "color 4" 5 "color 5" 6 "color 6" 7 "color 7" 8 "color 8" 9 "color 9" 10 "color 10" 11 "reserved" 12 "reserved" 13 "reserved" 14 "reserved" 15 "Invalid" ;
VAL_ 2470763009 USM_RrWiperRevSetReq 0 "Default" 1 "Rear Wiper(reverse) Off" 2 "Rear Wiper(reverse) On" 3 "Invalid" ;
VAL_ 2470763009 USM_RrStRemindSetReq 0 "Default" 1 "Off(Disable)" 2 "On(Enable)" 3 "Invalid" ;
VAL_ 2470763009 USM_RrWpcSetReq 0 "Default" 1 "Off(Disable)" 2 "On(Enable)" 3 "Invalid" ;
VAL_ 2470763009 USM_WpcSetReq 0 "Default" 1 "Off(Disable)" 2 "On(Enable)" 3 "Invalid" ;
VAL_ 2470763009 USM_SeqLmpSetReq 0 "Default" 1 "Off" 2 "On" 3 "Invalid" ;
VAL_ 2470763009 USM_UnlckWlcmSetReq 0 "Default Value" 1 "Off" 2 "On" 3 "Invalid" ;
VAL_ 2470763009 USM_SmrtWlcmSetReq 0 "Default Value" 1 "Off" 2 "On" 3 "Invalid" ;
VAL_ 2470763009 USM_UipSetReq 0 "Default(USM¹Ì±¸¼º)" 1 "Off(Disable)" 2 "On(Enable)" 3 "Invalid" ;
VAL_ 2470763009 USM_DigitalKeyEnblSetReq 0 "Default(¹Ì±¸¼º)" 1 "Disable" 2 "Enable" 3 "Invalid" ;
VAL_ 2470763009 USM_OwnerPhnRegSetReq 0 "Default(¹Ì±¸¼º)" 1 "Deleter" 2 "Register" 3 "Invalid" ;
VAL_ 2470763009 USM_NFCCard1RegSetReq 0 "Default(¹Ì±¸¼º)" 1 "Disable" 2 "Enable" 3 "Invalid" ;
VAL_ 2470763009 USM_NFCCard2RegSetReq 0 "Default(¹Ì±¸¼º)" 1 "Disable" 2 "Enable" 3 "Invalid" ;
VAL_ 2470763009 USM_ProcStpReq 0 "Default" 1 "StopReq" ;
VAL_ 2470763009 USM_PwrAutoOffTimeSetReq 0 "Default" 1 "Timer1" 2 "Timer2" 3 "Timer3" 4 "Timer4" 5 "Reserved" 6 "Reserved" 7 "Invalid" ;
VAL_ 2470763009 USM_RrStRemindSetReq_RestMode 0 "Default" 1 "Off(Disable)" 2 "On(Enable)" 3 "Invalid" 4 "Reserved" 5 "Reserved" 6 "Not Used" 7 "Error Indicator" ;
VAL_ 2470763009 USM_1stRrStRemindSetReq 0 "Default" 1 "Off(Disable)" 2 "On(Enable)" 3 "Invalid" ;
VAL_ 2470763009 USM_Wpc2SetReq 0 "Default" 1 "Off(Disable)" 2 "On(Enable)" 3 "Invalid" ;
VAL_ 2382595073 DATC_FrDrvBlwDis 0 "OFF" 1 "Blank Display" 2 "1 Step" 3 "2 Step" 4 "3 Step" 5 "4 Step" 6 "5 Step" 7 "6 Step" 8 "7 Step" 9 "8 Step" 10 "BLOWER AUTO" 11 "Reserved" 12 "Reserved" 13 "Reserved" 14 "Reserved" 15 "Error Indicator" ;
VAL_ 2382595073 DATC_FrPsBlwDis 0 "OFF" 1 "Blank Display(Blower ´Ü¼ö ¹ÌÇ¥½Ã, ¿¹)Auto ½Ã)" 2 "1 Step" 3 "2 Step" 4 "3 Step" 5 "4 Step" 6 "5 Step" 7 "6 Step" 8 "7 Step" 9 "8 Step" 10 "BLOWER AUTO" 11 "Reserved" 12 "Reserved" 13 "Reserved" 14 "Reserved" 15 "Error Indicator" ;
VAL_ 2382595073 DATC_HeatDis 0 "Heat OFF" 1 "Heat ON" 2 "Not used" 3 "Error Indicator" ;
VAL_ 2382595073 DATC_EVScrnDis 0 "Deactivated" 1 "Activated" 2 "Not used" 3 "Error Indicator" ;
VAL_ 2382595073 DATC_DrvOnlyDis 0 "Initial (Dual Temp Display)" 1 "Driver Only Status (Only Display Driver Temp)" 2 "Not used" 3 "Error Indicator" ;
VAL_ 2382595073 DATC_DiagCodeDis 0 "Blank Display(Default)" 1 "0x01~0xFE:0~253(PHY=(HEX*1.0-1.0))" 254 "0x01~0xFE:0~253(PHY=(HEX*1.0-1.0))" 255 "Error Indicator" ;
VAL_ 2382595073 DATC_RrChgReqDis 0 "Not requested" 1 "User Input" 2 "Not used" 3 "Error Indicator" ;
VAL_ 2382595073 DATC_RrClmtScrnDis 0 "Deactived" 1 "Actived" 2 "Not used" 3 "Error Indicator" ;
VAL_ 2382595073 DATC_AUTOStep 0 "Default" 1 "OFF" 2 "1st & 2nd & 3rd On (3 Step Type)" 3 "1st & 2nd On (3 Step Type)" 4 "1st On (3 Step Type)" 5 "1st & 2nd On (2 Step Type)" 6 "1st On (2 Step Type)" 7 "Reserved" 8 "Reserved" 9 "Reserved" 10 "Reserved" 11 "Reserved" 12 "Reserved" 13 "Reserved" 14 "Reserved" 15 "Error Indicator" ;
VAL_ 2382595073 DATC_IntakeDis 0 "Default" 1 "REC (Fresh off)" 2 "FRE (REC off)" 3 "Error indicator" ;
VAL_ 2382595073 DATC_MultiAirModSta 0 "Default" 1 "OFF" 2 "ON" 3 "Error Indicator" ;
VAL_ 1174 Drv_SHVU_SeatOptSta 0 "Init" 1 "Heater only 2step" 2 "Heater only 3step" 3 "Vent only 2step" 4 "Vent only 3step" 5 "Heater and Vent 2step" 6 "Heater and Vent 3step" 7 "Invalid" ;
VAL_ 1174 Drv_SHVU_HtSwHiIndSta 0 "Off(Initial Value)" 1 "On" 2 "RESERVED" 3 "Error Indicator" ;
VAL_ 1174 Drv_SHVU_HtSwMidIndSta 0 "Off(Initial Value)" 1 "On" 2 "RESERVED" 3 "Error Indicator" ;
VAL_ 1174 Drv_SHVU_HtSwLowIndSta 0 "Off(Initial Value)" 1 "On" 2 "RESERVED" 3 "Error Indicator" ;
VAL_ 1174 Drv_SHVU_VntSwHiIndSta 0 "Off(Initial Value)" 1 "On" 2 "RESERVED" 3 "Error Indicator" ;
VAL_ 1174 Drv_SHVU_VntSwMidIndSta 0 "Off(Initial Value)" 1 "On" 2 "RESERVED" 3 "Error Indicator" ;
VAL_ 1174 Drv_SHVU_VntSwLowIndSta 0 "Off(Initial Value)" 1 "On" 2 "RESERVED" 3 "Error Indicator" ;
VAL_ 1174 Drv_SHVU_HtBlcUSMSta 0 "Default" 1 "Normal" 2 "Back 1" 3 "Back 2" 4 "Back 3" 5 "Cush 1" 6 "Cush 2" 7 "Cush 3" 8 "Reserved" 9 "Reserved" 10 "Reserved" 11 "Reserved" 12 "Reserved" 13 "Reserved" 14 "Reserved" 15 "Invalid" ;
VAL_ 1174 Drv_SHVU_SeatHtOperSta 0 "Init" 1 "RESERVED" 2 "Heater & Vent OFF" 3 "Vent Low" 4 "Vent Mid" 5 "Vent High" 6 "Heater Low" 7 "Heater Mid" 8 "Heater High" 9 "RESERVED" 10 "RESERVED" 11 "RESERVED" 12 "RESERVED" 13 "RESERVED" 14 "RESERVED" 15 "Invalid" ;
VAL_ 1174 Drv_SHVU_HtSwHiIndSta_RHD 0 "Off(Initial Value)" 1 "On" 2 "RESERVED" 3 "Error Indicator" ;
VAL_ 1174 Drv_SHVU_HtSwMidIndSta_RHD 0 "Off(Initial Value)" 1 "On" 2 "RESERVED" 3 "Error Indicator" ;
VAL_ 1174 Drv_SHVU_HtSwLowIndSta_RHD 0 "Off(Initial Value)" 1 "On" 2 "RESERVED" 3 "Error Indicator" ;
VAL_ 1174 Drv_SHVU_VntSwHiIndSta_RHD 0 "Off(Initial Value)" 1 "On" 2 "RESERVED" 3 "Error Indicator" ;
VAL_ 1174 Drv_SHVU_VntSwMidIndSta_RHD 0 "Off(Initial Value)" 1 "On" 2 "RESERVED" 3 "Error Indicator" ;
VAL_ 1174 Drv_SHVU_VntSwLowIndSta_RHD 0 "Off(Initial Value)" 1 "On" 2 "RESERVED" 3 "Error Indicator" ;
VAL_ 1174 Drv_SHVU_HtBlcUSMSta_RHD 0 "Default" 1 "Normal" 2 "Back 1" 3 "Back 2" 4 "Back 3" 5 "Cush 1" 6 "Cush 2" 7 "Cush 3" 8 "Reserved" 9 "Reserved" 10 "Reserved" 11 "Reserved" 12 "Reserved" 13 "Reserved" 14 "Reserved" 15 "Invalid" ;
VAL_ 1179 Drv_SHVU_SeatEcoSta 0 "Off(Initial Value)" 1 "On" 2 "RESERVED" 3 "Error Indicator" ;
VAL_ 1179 SHVU_Drv_Beep1Sound 0 "Beep1 mode Off" 1 "Beep1 mode On" 2 "RESERVED" 3 "Invalid" ;
VAL_ 1179 SHVU_CtrlScreenDis 0 "Default" 1 "Screen Display On" 2 "RESERVED" 3 "Invalid" ;
VAL_ 1159 C_AstRclBwdSw_HU 0 "Default" 1 "Off" 2 "On" 3 "Invalid" ;
VAL_ 1159 C_AstHeightUpSw_HU 0 "Default" 1 "Off" 2 "On" 3 "Invalid" ;
VAL_ 1159 C_AstTiltDnSw_HU 0 "Default" 1 "Off" 2 "On" 3 "Invalid" ;
VAL_ 1159 C_AstTiltUpSw_HU 0 "Default" 1 "Off" 2 "On" 3 "Invalid" ;
VAL_ 1159 C_AstLumbarDefSw_HU 0 "Default" 1 "Off" 2 "On" 3 "Invalid" ;
VAL_ 1159 C_AstLumbarLowSw_HU 0 "Default" 1 "Off" 2 "On" 3 "Invalid" ;
VAL_ 1159 C_AstRclFwdSw_HU 0 "Default" 1 "Off" 2 "On" 3 "Invalid" ;
VAL_ 1159 C_AstLumbarMidSw_HU 0 "Default" 1 "Off" 2 "On" 3 "Invalid" ;
VAL_ 1159 C_AstLumbarUpSw_HU 0 "Default" 1 "Off" 2 "On" 3 "Invalid" ;
VAL_ 1159 C_RRSlideFwdSw_HU 0 "Default" 1 "Off" 2 "On" 3 "Invalid" ;
VAL_ 1159 C_RRSlideBwdSw_HU 0 "Default" 1 "Off" 2 "On" 3 "Invalid" ;
VAL_ 1159 C_RLSlideFwdSw_HU 0 "Default" 1 "Off" 2 "On" 3 "Invalid" ;
VAL_ 1159 C_RLSlideBwdSw_HU 0 "Default" 1 "Off" 2 "On" 3 "Invalid" ;
VAL_ 1159 C_AstSlideBwdSw_HU 0 "Default" 1 "Off" 2 "On" 3 "Invalid" ;
VAL_ 1159 C_AstSlideFwdSw_HU 0 "Default" 1 "Off" 2 "On" 3 "Invalid" ;
VAL_ 1159 C_AstHeightDnSw_HU 0 "Default" 1 "Off" 2 "On" 3 "Invalid" ;
VAL_ 197 C_DrvRclBwdSw_HU 0 "Default" 1 "Off" 2 "On" 3 "Invalid" ;
VAL_ 197 C_DrvSlideFwdSw_HU 0 "Default" 1 "Off" 2 "On" 3 "Invalid" ;
VAL_ 197 C_RLLegSupFwdSw_HU 0 "Default" 1 "Off" 2 "On" 3 "Invalid" ;
VAL_ 197 C_RLLegSupBwdSw_HU 0 "Default" 1 "Off" 2 "On" 3 "Invalid" ;
VAL_ 197 C_DrvSlideBwdSw_HU 0 "Default" 1 "Off" 2 "On" 3 "Invalid" ;
VAL_ 197 C_RLLegSupUpSw_HU 0 "Default" 1 "Off" 2 "On" 3 "Invalid" ;
VAL_ 197 C_RLLegSupDnSw_HU 0 "Default" 1 "Off" 2 "On" 3 "Invalid" ;
VAL_ 197 C_DrvRclFwdSw_HU 0 "Default" 1 "Off" 2 "On" 3 "Invalid" ;
VAL_ 1278 HU_Type 16 "AVN(Tuner DVD KOR)" 17 "AVN(Tuner DVD EUR)" 18 "AVN(Tuner DVD China)" 19 "AVN(Tuner DVD Japan)" 20 "AVN(Tuner DVD EUR)" 21 "AVN(Tuner CDP KOR)" 22 "AVN(Tuner CDP EUR)" 23 "AVN(Tuner CDP China)" 24 "AVN(Tuner CDP Japan)" 25 "AVN(Tuner CDP EUR)" 32 "AVNT (Open)" 33 "AVNT (Not open)" 48 "Economic Audio" 64 "Standard Audio (3.0 below)" 65 "Standard Audio 4.0" 66 "STD Audio-3.0Below,No interwork" 67 "Audio 4.0 Value" 80 "AV(Tuner DVD KOR)" 81 "AV(Tuner DVD EUR)" 82 "AV(Tuner DVD China)" 83 "AV(Tuner DVD Japan)" 84 "AV(Tuner DVD EUR)" 85 "AV(Tuner CDP KOR)" 86 "AV(Tuner CDP EUR)" 87 "AV(Tuner CDP China)" 88 "AV(Tuner CDP Japan)" 89 "AV(Tuner CDP EUR)" 96 "AVN 4.0" 97 "Premium AVN2.0" 98 "EU AVN 2.0" 99 "Super Premium w Navi" 100 "Super Premium w_o Navi" 101 "Premium w Navi" 102 "Premium w_o Navi" 103 "Display Audio w_o Navi" 104 "Integrated AVN 1.0 Mobis" 105 "Gen5 Standard Nav Wide" 112 "Compact AVN & Integrated AVN 1.0 LG" 113 "Standard-class Gen6 Navigation" 128 "Premium Navi 5th Gen(w_Navi)" 129 "Premium Navi 5th Gen(w_o Navi)" 130 "Premium Navi 6th Gen(w_Navi)" 131 "Premium Navi 6th Gen(w_o Navi)" 132 "ccNC(w Navi)" 133 "ccNC(w_o Navi)" 134 "ccIC(w Navi)" 135 "ccIC(w_o Navi)" 238 "India PIO w_o CLU interface" 239 "India PIO w_CLU interface" 241 "Gen 1 China OEM Navigation" 250 "PIO AVN" 251 "China  Local OEM Display Audio" 252 "China OPIO w_o CLU interface" 253 "China OPIO w_CLU interface" 254 "China Local OEM AVNT" 255 "Invalid" ;
VAL_ 1278 HU_DistributeInfo 0 "Default (Korea)" 1 "Korea" 2 "North America" 3 "Canada" 4 "East Europe" 5 "West Europe" 6 "China" 7 "India" 8 "Australia" 9 "Middle East" 10 "Africa" 11 "South America" 12 "Russia" 13 "Japan" 14 "General" 15 "0x0F~0xFE:Reserved" 254 "0x0F~0xFE:Reserved" 255 "Invalid" ;
VAL_ 1278 HU_OptionInfo 32768 "Invalid" ;
VAL_ 1278 HU_NaviMapInfo 0 "Unknown" 1 "Korea" 2 "North America" 3 "Europe" 4 "Middle East" 5 "Australia" 6 "South America" 7 "China" 8 "Russia" 9 "Turkey" 10 "India" 11 "Japan" 15 "Invalid" ;
VAL_ 1278 HU_NaviHandshakingSupport 0 "Not Support" 1 "Support" 2 "Unknown" 3 "Invalid" ;
VAL_ 1278 HU_AMP_EQVariant 0 "Default" 1 "WGN" 2 "WGN PHEV" 3 "5DR" 4 "SB" 5 "CUV" 6 "HEV" 7 "PHEV" 8 "EV" 9 "Reserved" 10 "Reserved" 11 "Reserved" 12 "Reserved" 13 "Reserved" 14 "Reserved" 15 "Reserved" 16 "Reserved" 17 "Reserved" 18 "Reserved" 19 "Reserved" 20 "Reserved" 21 "Reserved" 22 "Reserved" 23 "Reserved" 24 "Reserved" 25 "Reserved" 26 "Reserved" 27 "Reserved" 28 "Reserved" 29 "Reserved" 30 "Reserved" ;
VAL_ 1278 HU_AdasSupport 0 "Not Support" 1 "ADAS Support(General Map)" 2 "ADAS Support(Map based ADAS v1)" 3 "ADAS Support(Map based ADAS v2)" 4 "ADAS Support(Map based ADAS v2 & Handshaking)" 5 "ADAS Support(Map based ADAS v2_3)" 6 "Reserved" 7 "Invalid" ;
VAL_ 1278 HU_Navi_RspADASMapMsg 0 "0x0x0~0xFFFF:Refer to Signal Description" 65535 "0x0x0~0xFFFF:Refer to Signal Description" ;
VAL_ 1279 USM_SmartRegen_Map_Set 0 "Default" 1 "Off(Disbaled)" 2 "On(Enabled)" 3 "Invalid" ;
VAL_ 1279 USM_SmartRegen_Sens_Set 0 "Default" 1 "Slow" 2 "Normal" 3 "Fast" 4 "Reserved" 5 "Reserved" 6 "Reserved" 7 "Invalid" ;
VAL_ 1279 AVN_SeatPosMemory_Btn 0 "Default" 1 "Memory 1" 2 "Memory 2" 3 "Memory 3" 4 "Reserved" 5 "Reserved" 6 "Reserved" 7 "Invalid" ;
VAL_ 1279 AVN_SeatPosPlyBck_Btn 0 "Default" 1 "Memory 1" 2 "Memory 2" 3 "Memory 3" 4 "Reserved" 5 "Reserved" 6 "Stop" 7 "Invalid" ;
VAL_ 1279 USM_RhstaLvlEnaSetReq 0 "Default" 1 "Off" 2 "On" 3 "Invalid" ;
VAL_ 1279 USM_CMSDayBrgtnsLvlLHSetReq 0 "-5 Level" 1 "-4 Level" 2 "-3 Level" 3 "-2 Level" 4 "-1 Level" 5 "0 Level" 6 "1 Level" 7 "2 Level" 8 "3 Level" 9 "4 Level" 10 "5 Level" 11 "Not Used" 12 "Not Used" 13 "Not Used" 14 "Error Indicator" 15 "Invalid" ;
VAL_ 1279 USM_CMSNgtBrgtnsLvlLHSetReq 0 "-5 Level" 1 "-4 Level" 2 "-3 Level" 3 "-2 Level" 4 "-1 Level" 5 "0 Level" 6 "1 Level" 7 "2 Level" 8 "3 Level" 9 "4 Level" 10 "5 Level" 11 "Not Used" 12 "Not Used" 13 "Not Used" 14 "Error Indicator" 15 "Invalid" ;
VAL_ 1279 USM_CMSDayBrgtnsLvlRHSetReq 0 "-5 Level" 1 "-4 Level" 2 "-3 Level" 3 "-2 Level" 4 "-1 Level" 5 "0 Level" 6 "1 Level" 7 "2 Level" 8 "3 Level" 9 "4 Level" 10 "5 Level" 11 "Not Used" 12 "Not Used" 13 "Not Used" 14 "Error Indicator" 15 "Invalid" ;
VAL_ 1279 USM_CMSNgtBrgtnsLvlRHSetReq 0 "-5 Level" 1 "-4 Level" 2 "-3 Level" 3 "-2 Level" 4 "-1 Level" 5 "0 Level" 6 "1 Level" 7 "2 Level" 8 "3 Level" 9 "4 Level" 10 "5 Level" 11 "Not Used" 12 "Not Used" 13 "Not Used" 14 "Error Indicator" 15 "Invalid" ;
VAL_ 1279 USM_CMSBrgtnsReset 0 "Default" 1 "Reset" 2 "Reserved" 3 "Invalid" ;
VAL_ 1279 USM_TurnDistLnDispSetReq 0 "Default" 1 "Off" 2 "On" 3 "Invalid" ;
VAL_ 1279 PCA_FrSd_NValueSet 0 "Default" 1 "Off" 2 "On" 3 "Invalid" ;
VAL_ 1279 CF_AVN_1stRrStRmndNValueSet 0 "Default" 1 "Off" 2 "On" 3 "Invalid" ;
VAL_ 1279 C_AllDrOpnNValueSet 0 "Default" 1 "Off" 2 "PSD Open" 3 "PSD PTG Open" 4 "Reserved" 5 "Reserved" 6 "Reserved" 7 "Invalid" ;
VAL_ 1279 USM_RpmECOSet 0 "Default" 1 "Off" 2 "On(RPM Gauge Display)" 3 "Invalid" ;
VAL_ 1279 VESS_ChgGuideMdLvl 0 "Default" 1 "Level 1(¾àÇÏ°Ô)" 2 "Level 2(Áß°£)" 3 "Level 3(°­ÇÏ°Ô)" 4 "Reserved" 5 "Reserved" 6 "Off" 7 "Invalid" ;
VAL_ 1279 Usm_RpmSPORTSet 0 "Default" 1 "Off" 2 "On(RPM Gauge Display)" 3 "Invalid" ;
VAL_ 1279 Usm_RpmSPORTPLUSSet 0 "Default" 1 "Off" 2 "On(RPM Gauge Display)" 3 "Invalid" ;
VAL_ 200 CF_AVN_ADrLNValueSet_2 0 "Default" 1 "Off" 2 "Vehicle Speed On (15km/h)" 3 "Vehicle Speed On and Shift Lever On" 4 "Invalid" 5 "Reserved" 6 "Reserved" 7 "Reserved" ;
VAL_ 200 CF_AVN_FCA_JC_OnOffEquipNvalueSet 0 "Default" 1 "Off" 2 "On" 3 "Invalid" ;
VAL_ 200 CF_AVN_FCA_FrSdOnOffEquipNvalueSet 0 "Default" 1 "Off" 2 "On" 3 "Invalid" ;
VAL_ 200 CF_AVN_LKA_OnOffEquip2NvalueSet 0 "Default" 1 "Off" 2 "On" 3 "Invalid" ;
VAL_ 200 CF_AVN_BCA_OnOffEquip2NvalueSet 0 "Default" 1 "Off" 2 "On" 3 "Invalid" ;
VAL_ 200 CF_AVN_BVM_OnOffEquipNvalueSet 0 "Default" 1 "Off" 2 "On" 3 "Invalid" ;
VAL_ 200 CF_AVN_SEA_OnOffEquip3NvalueSet 0 "Default" 1 "Off" 2 "On" 3 "Invalid" ;
VAL_ 200 CF_AVN_BodySpprtSet_AST 0 "Default" 1 "Off" 2 "On" 3 "Invalid" ;
VAL_ 200 CF_AVN_SEW_OnOffEquip3NvalueSet 0 "Default" 1 "Off" 2 "On" 3 "Invalid" ;
VAL_ 200 CF_AVN_HudImsAutoSave 0 "Default" 1 "Off" 2 "On" 3 "Invalid" ;
VAL_ 200 USM_PwrDrBuzzerNValueSet 0 "Default" 1 "Off" 2 "On" 3 "Invalid" ;
VAL_ 200 CF_AVN_DWLNValueSet 0 "Default" 1 "Comfort" 2 "Natural" 3 "Dynamic" 4 "Reserved" 5 "Reserved" 6 "Reserved" 7 "Invalid" ;
VAL_ 200 CF_AVN_AirSptTimeNValueSet_AST 0 "Default" 1 "Short" 2 "Normal" 3 "Long" 4 "Reserved" 5 "Reserved" 6 "Reserved" 7 "Invalid" ;
VAL_ 200 CF_AVN_AirSptStrNValue_AST 0 "Default" 1 "Normal" 2 "Intense" 3 "Invalid" ;
VAL_ 200 CF_AVN_SeatDrvModNvalueSet_AST 0 "Default" 1 "Off" 2 "On" 3 "Invalid" ;
VAL_ 200 CF_AVN_TPMS_TireReplaceNValueSet 0 "Default" 1 "Off(Standard)" 2 "ON(SnowChain)" 3 "Reserved" 4 "Reserved" 5 "Reserved" 6 "Not Used(Gray)" 7 "Error Indicator" ;
VAL_ 200 CF_AVN_TowModeSet 0 "Default" 1 "Off" 2 "Small Weight" 3 "Medium Weight" 4 "Maximum Weight" 5 "Reserved" 6 "Reserved" 7 "Invalid" ;
VAL_ 200 USM_PwrDrCloseByBraekNValueSet 0 "Default" 1 "Off" 2 "On" 3 "Invalid" ;
VAL_ 200 CF_AVN_ISLANAOffstNvalueSet 0 "Default" 1 "-10kph -10mph" 2 "-5kph -5mph" 3 "0kph 0mph" 4 "5kph 5mph" 5 "10kph 10mph" 6 "Reserved" 7 "Invalid" ;
VAL_ 200 CF_Gway_WPC2_NValueSet 0 "Default" 1 "Off (Disable)" 2 "On (Enable)" 3 "Invalid" ;
VAL_ 200 USM_DrvGhostDoorReq 0 "Default" 1 "Off" 2 "On" 3 "Invalid" ;
VAL_ 200 USM_AstGhostDoorReq 0 "Default" 1 "Off" 2 "On" 3 "Invalid" ;
VAL_ 200 USM_RLGhostDoorReq 0 "Default" 1 "Off" 2 "On" 3 "Invalid" ;
VAL_ 200 CF_AVN_FCA_FrOnOffEquipNvalueSet 0 "Default" 1 "Off" 2 "On" 3 "Invalid" ;
VAL_ 200 CF_AVN_FCA_WarnTimeNvalueSet 0 "Default" 1 "Late" 2 "Normal" 3 "Reserved" 4 "Reserved" 5 "Reserved" 6 "Reserved" 7 "Invalid" ;
VAL_ 1167 Bat_dischrg 0 "Flag OFF" 1 "Flag ON" 2 "Reserved" 3 "Reserved" ;
VAL_ 1167 Batt_SoCWarningValue 0 "0x0x0~0x64:0 ~ 100%" 100 "0x0x0~0x64:0 ~ 100%" 101 "0x65~0xFE:Reserved" 254 "0x65~0xFE:Reserved" 255 "Invalid" ;
VAL_ 1167 C_StrgWhlHeatingOpt 0 "Not Applied" 1 "Applied(steering wheel applied)" 2 "Reserved" 3 "Invalid" ;
VAL_ 1167 C_StrgWhlHeatingSWInf 0 "Default" 1 "1step opt(On/Off)" 2 "2step opt(step1,step2,Off)" 3 "Invalid" ;
VAL_ 1167 ICU_BattAutoCutPreWrng 0 "No Warning" 1 "Warning" 2 "Not Used" 3 "Invalid" ;
VAL_ 1167 IGN_AutoOff_WarnSta_CLU 0 "No Warning" 1 "Power Off Warning" 2 "Reserved" 3 "Error Indicator" ;
VAL_ 1167 PDC_BatPwrStateClassA 0 "Not used" 1 "Low power condition for ClassA-load operation during park mode" 2 "High power condition for ClassA-load operation during park mode" 3 "Invaild" ;
VAL_ 1167 PDC_BatPwrStateClassB 0 "Not used" 1 "Low power condition for ClassB-load operation during park mode" 2 "High power condition for ClassB-load operation during park mode" 3 "Invaild" ;
VAL_ 1167 PDC_BatPwrStateClassC 0 "Not used" 1 "Low power condition for ClassC-load operation during park mode" 2 "High power condition for ClassC-load operation during park mode" 3 "Invaild" ;
VAL_ 1167 PLBMAvailableState 0 "Invaild" 1 "PLBM Power is available" ;
VAL_ 1167 IGN_AutoOff_WarnSta 0 "No Warning" 1 "Power Off Warning" 2 "Reserved" 3 "Error Indicator" ;
VAL_ 1171 RLPSM_SWVerMajor1 0 "0x0x0~0x7F:ASCII Code Value (HEX)" 127 "0x0x0~0x7F:ASCII Code Value (HEX)" ;
VAL_ 1171 RLPSM_SWVerMinor2 0 "0x0x0~0x7F:ASCII Code Value (HEX)" 127 "0x0x0~0x7F:ASCII Code Value (HEX)" ;
VAL_ 1171 RLPSM_SWVerMinor1 0 "0x0x0~0x7F:ASCII Code Value (HEX)" 127 "0x0x0~0x7F:ASCII Code Value (HEX)" ;
VAL_ 1181 RL_SHVU_SeatEcoSta 0 "Off(Initial Value)" 1 "On" 2 "RESERVED" 3 "Error Indicator" ;
VAL_ 1172 RRPSM_SWVerMajor1 0 "0x0x0~0x7F:ASCII Code Value (HEX)" 127 "0x0x0~0x7F:ASCII Code Value (HEX)" ;
VAL_ 1172 RRPSM_SWVerMinor2 0 "0x0x0~0x7F:ASCII Code Value (HEX)" 127 "0x0x0~0x7F:ASCII Code Value (HEX)" ;
VAL_ 1172 RRPSM_SWVerMinor1 0 "0x0x0~0x7F:ASCII Code Value (HEX)" 127 "0x0x0~0x7F:ASCII Code Value (HEX)" ;
VAL_ 1182 RR_SHVU_SeatEcoSta 0 "Off(Initial Value)" 1 "On" 2 "RESERVED" 3 "Error Indicator" ;
VAL_ 208 RR_SHVU_DTCdisplay 0 "DTC is not exist(Fail is not exist)" 1 "IGN2 Fuse Open Detection" 2 "Switch Input Detection at Same Time" 3 "NTC/Heating wire Open Detection" 4 "NTC+/NTC- Terminal Short Detection" 5 "NTC+/Heater+ Terminal Short Detection" 6 "NTC+/Heater-, Heater+/Heater-, Heater+/NTC- Terminal Short Detection" 7 "NTC+/Heater- Wiring Short Detection" 8 "NTC+/Heater-, Heater+/Heater-, Heater+/NTC- Wiring Short Detection" 9 "Target Temperature Dissatisfied" 10 "Blower+/Blower- Short, Blower+/Blower Speed, Blower-/Blower Speed Wiring Short Detection" 11 "Blower+/Blower RPM, Blower-/Blower RPM, Blower Speed/Blower RPM Short Detection" 12 "Blower+, Blower-, Blower Speed Signal open Detection" 13 "Blower RPM signal Open Detection" 14 "0xE~0xFD:Unused" 253 "0xE~0xFD:Unused" 254 "No Display" 255 "Invalid" ;
VAL_ 208 RR_SHVU_DiagMode 0 "Default" 1 "DTC Mode" 2 "Normal Mode" 3 "Invalid" ;
VAL_ 761 CDM_TypeOption_AST 0 "Off" 1 "On" 2 "Error Indicator" 3 "Invalid" ;
VAL_ 761 CDM_ImmeChgSw_AST 0 "Default" 1 "Off" 2 "On" 3 "Invalid" ;
VAL_ 761 CDM_ChgDrSwFrt_AST 0 "Default" 1 "Close" 2 "Open" 3 "Invalid" ;
VAL_ 761 CDM_OpnClsState_AST 0 "Default" 1 "Open" 2 "Close" 3 "Invalid" ;
VAL_ 761 CDM_WarnMsg_AST 0 "Default" 1 "Normal" 2 "ChargeDoorErrorState" 3 "Invalid" ;
VAL_ 761 Mirror_RH_FoldingSta 0 "Off" 1 "Folding" 2 "Not Used" 3 "Error Indicator" ;
VAL_ 761 Mirror_RH_UnfoldingSta 0 "Off" 1 "Unfolding" 2 "Not Used" 3 "Error Indicator" ;
VAL_ 761 CDM_CmdStatus_AST 0 "Open (AVN)" 1 "Open (SMK)" 2 "Open (Sensor Switch)" 3 "Open (Command Hard Switch)" 4 "Open (Anti - Pinch)" 5 "Close (AVN)" 6 "Close (SMK)" 7 "Close (Assist Mode)" 8 "Close (Command Hard Switch)" 9 "Close (Connector)" 10 "Close (Gear Position)" 11 "Close (Time Over)" 12 "Close (Anti - Pinch)" 13 "Close (Sensor Switch)" 14 "Stall (Stop)" 15 "Invalid" ;
VAL_ 761 AST_CrashMRActAlarm 0 "Off" 1 "On" 2 "Not Used" 3 "Error Indicator" ;
VAL_ 761 IMS_OSMirPlayBackSta_RH 0 "Stop" 1 "Play 1" 2 "Play 2" 3 "Smart IMS" 4 "Profile 1" 5 "Profile 2" 6 "Guest" 7 "Invalid" ;
VAL_ 761 Mirror_RHVerPosVal 251 "Reserved" 252 "Reserved" 253 "Reserved" 254 "Reserved" 255 "Error Indicator" ;
VAL_ 761 Mirror_RHHorPosVal 251 "Reserved" 252 "Reserved" 253 "Reserved" 254 "Reserved" 255 "Error Indicator" ;
VAL_ 761 SBCM_AST_DiagSta 0 "Default" 1 "Normal Operation" 2 "AST Indicator Circuit Failure" 3 "Invalid" ;
VAL_ 758 DoorLock_CtrlDrLkUnLkSwSta_SBCM 0 "Off" 1 "On" 2 "Not Used" 3 "Error Indicator" ;
VAL_ 758 SBCM_PsvDrLkReq 0 "None" 1 "Lock" 2 "Passive Trunk Lock" 3 "Not Used" ;
VAL_ 758 USM_DrvGhostDoorSta 0 "Default" 1 "Off" 2 "On" 3 "Invalid" ;
VAL_ 758 Mirror_LH_FoldingSta 0 "Off" 1 "Folding" 2 "Not Used" 3 "Error Indicator" ;
VAL_ 758 Mirror_LH_UnfoldingSta 0 "Off" 1 "Unfolding" 2 "Not Used" 3 "Error Indicator" ;
VAL_ 758 DRV_CrashMRActAlarm 0 "Off" 1 "On" 2 "Not Used" 3 "Error Indicator" ;
VAL_ 758 MirrorFldReq 0 "Default" 1 "Folding Request" 2 "Unfolding Request" 3 "Invalid" ;
VAL_ 758 OMU_TypeOption_DRV 0 "Off" 1 "On" 2 "Not Used" 3 "Error Indicator" ;
VAL_ 758 IMS_OSMirPlayBackSta_LH 0 "Stop" 1 "Play 1" 2 "Play 2" 3 "Smart IMS" 4 "Profile 1" 5 "Profile 2" 6 "Guest" 7 "Invalid" ;
VAL_ 758 ECMMRR_PLUS 0 "0x0x0~0x7D:0~1.25 V" 125 "0x0x0~0x7D:0~1.25 V" 126 "0x7E~0xFE:Reserved" 254 "0x7E~0xFE:Reserved" 255 "Invalid" ;
VAL_ 758 Mirror_LHVerPosVal 251 "Reserved" 252 "Reserved" 253 "Reserved" 254 "Reserved" 255 "Error Indicator" ;
VAL_ 758 Mirror_LHHorPosVal 251 "Reserved" 252 "Reserved" 253 "Reserved" 254 "Reserved" 255 "Error Indicator" ;
VAL_ 758 SBCM_DRV_DiagSta 0 "Default" 1 "Normal Operation" 2 "DRV Indicator Circuit Failure" 3 "Invalid" ;
VAL_ 763 CDM_TypeOption 0 "Off" 1 "On" 2 "Error Indicator" 3 "Reserved" ;
VAL_ 763 CDM_ImmeChgSw_SBCM 0 "Default" 1 "Off" 2 "On" 3 "Invalid" ;
VAL_ 763 CDM_ChgDrSwFrt_SBCM 0 "Default" 1 "Close" 2 "Open" 3 "Invalid" ;
VAL_ 763 CDM_OpnClsState_SBCM 0 "Default" 1 "Open" 2 "Close" 3 "Invalid" ;
VAL_ 763 CDM_WarnMsg_SBCM 0 "Default" 1 "Normal" 2 "ChargeDoorErrorState" 3 "Invalid" ;
VAL_ 763 CDM_AutoWashModeSta 0 "Default" 1 "CDM Auto Wash Mode Off (Ready)" 2 "CDM Auto Wash Mode Off (Error)" 3 "CDM Auto Wash Mode On" 4 "RESERVED" 5 "RESERVED" 6 "RESERVED" 7 "Invalid" ;
VAL_ 763 CDM_CmdStatus_SBCM 0 "Open (AVN)" 1 "Open (SMK)" 2 "Open (Sensor Switch)" 3 "Open (Command Hard Switch)" 4 "Open (Anti - Pinch)" 5 "Close (AVN)" 6 "Close (SMK)" 7 "Close (Assist Mode)" 8 "Close (Command Hard Switch)" 9 "Close (Connector)" 10 "Close (Gear Position)" 11 "Close (Time Over)" 12 "Close (Anti - Pinch)" 13 "Close (Sensor Switch)" 14 "Stall (Stop)" 15 "Invalid" ;
VAL_ 763 Warn_HoodSwSta_SBCM 0 "Off" 1 "On" 2 "RESERVED" 3 "Error Indicator" ;
VAL_ 763 Hood_TypeOption 0 "Off" 1 "On" 2 "RESERVED" 3 "Error Indicator" ;
VAL_ 763 SBCM_FrunkSta 0 "Default" 1 "Valid" 2 "RESERVED" 3 "Error Indicator" ;
VAL_ 763 Warn_HoodSwFullSta_SBCM 0 "Off" 1 "On" 2 "RESERVED" 3 "Error Indicator" ;
VAL_ 763 CDM_InsideOpnSwSta 0 "Off" 1 "On" 2 "Not Used" 3 "Error Indicator" ;
VAL_ 742 SGU_FltSta 0 "Normal" 1 "Fault" 2 "Not Used" 3 "Error Indicator" ;
VAL_ 742 SGU_BlindOnOffSet 0 "USM Activation" 1 "Off" 2 "On" 3 "Invalid" ;
VAL_ 742 SGU_BlindOpenReq 0 "Default" 1 "BlindOpen" 2 "Reserved" 3 "Invalid" ;
VAL_ 742 SGU_Roof_OprLv 0 "Default" 1 "OFF" 2 "Level 1" 3 "Level 2" 4 "Level 3" 5 "Reserved" 6 "Reserved" 7 "Invalid" ;
VAL_ 742 SGU_2ndLeftDoor_OprLv 0 "Default" 1 "Off" 2 "Level 1" 3 "Level 2" 4 "Level 3" 5 "Reserved" 6 "Reserved" 7 "Invalid" ;
VAL_ 742 SGU_2ndRightDoor_OprLv 0 "Default" 1 "Off" 2 "Level 1" 3 "Level 2" 4 "Level 3" 5 "Reserved" 6 "Reserved" 7 "Invalid" ;
VAL_ 742 SGU_3rdLeftDoor_OprLv 0 "Default" 1 "Off" 2 "Level 1" 3 "Level 2" 4 "Level 3" 5 "Reserved" 6 "Reserved" 7 "Invalid" ;
VAL_ 742 SGU_3rdRightDoor_OprLv 0 "Default" 1 "Off" 2 "Level 1" 3 "Level 2" 4 "Level 3" 5 "Reserved" 6 "Reserved" 7 "Invalid" ;
VAL_ 742 SGU_RearWindow_OprLv 0 "Default" 1 "Off" 2 "Level 1" 3 "Level 2" 4 "Level 3" 5 "Reserved" 6 "Reserved" 7 "Invalid" ;
VAL_ 742 SGU_OprLvVehicleSet 0 "Default" 1 "Reserved" 2 "Off & Level 1" 3 "Off & Level 1 ~ 2" 4 "Off & Level 1 ~ 3" 5 "Off & Level 1 ~ 4" 6 "Off & Level 1 ~ 5" 7 "Invalid" ;
VAL_ 742 SGU_RdySta 0 "Off" 1 "Ready" 2 "Sleep" 3 "Reserved" ;
VAL_ 2328016129 VCU_EvDrvRdyCluDispSta 0 "Ready Lamp Off" 1 "Ready Lamp On" 2 "Error Indicator" 3 "Blinking" ;
VAL_ 2328016129 VCU_PwrDnModeSta 0 "None" 1 "Set" 2 "Not used" 3 "Error Indicator" ;
VAL_ 2328016129 VCU_CluWarnMsgSta 0 "None(Default)" 1 "Regenerative Braking System Operating Stop" 2 "AC,PTC Controllable when EV_Ready is OFF" 3 "-" 4 "Gear P Change Impossible(VB 10.5V)" 5 "Gear P Change Impossible(VB 9.5V)" 6 "-" 7 "-" 8 "Reserved" 9 "Reserved" 10 "Reserved" 11 "Reserved" 12 "Reserved" 13 "Reserved" 14 "Reserved" 15 "Reserved" ;
VAL_ 2328016129 VCU_DteOffDispSta 0 "None" 1 "DTE Off('---' Display)" 2 "Not used" 3 "Error Indicator" ;
VAL_ 2328016129 VCU_LowSocAlertSta 0 "No Alert" 1 "Low SOC Alert 1" 2 "Low SOC Alert 2" 3 "Low SOC Alert 3" 4 "Reserved" 5 "Reserved" 6 "Reserved" 7 "SOC Unavailable Alert" ;
VAL_ 2328016129 VCU_VcrmReq 0 "Wait(Not Request Logging)" 1 "Service/MIL Lamp On(Request Logging)" 2 "Warning, Abnormal IG Off(Request Logging)" 3 "Reserved" ;
VAL_ 2328016129 VCU_PdlWarnMsgSta 0 "None" 1 "Pop-up Request" 2 "Not used" 3 "Error Indicator" ;
VAL_ 2328016129 VCU_AwdDiagDispSta 0 "Off" 1 "On" 2 "NotUsed" 3 "ErrorIndicator" ;
VAL_ 2328016129 VCU_AwdLockDispSta 0 "Off" 1 "On" 2 "NotUsed" 3 "ErrorIndicator" ;
VAL_ 2328016129 VCU_VirtualApsActSta 0 "Real APS" 1 "Virtual APS for Crz" 2 "Not used" 3 "Error Indicator" ;
VAL_ 2328016129 VCU_ServiceLampReq 0 "None" 1 "Service Lamp On" 2 "Not used" 3 "Error Indicator" ;
VAL_ 2328016129 VCU_ServiceModeSta 0 "Normal" 1 "Certification Mode (F)" 2 "Certification Mode (R)" 3 "Error Indicator" ;
VAL_ 2328016129 VCU_NPosWshModSta 0 "Normal" 1 "Standby" 2 "N Wash Mode" 3 "Reserved" ;
VAL_ 2328016129 VCU_PowerTrainType 0 "One Moter" 1 "Dual Motor(Base)" 2 "Dual Motor(Performance)" 3 "Reserved" ;
VAL_ 2328016130 VCU_AvnDteOnCalcSta 0 "Display DTE Value" 1 "Display 'Recalculating'" 2 "Not used" 3 "Error Indicator" ;
VAL_ 2328016130 VCU_SbwWarnMsgSta 0 "Off" 1 "Warning 1 - SCU/Parking System Failure" 2 "Warning 2 - Unavailable to Shift Gear" 3 "Warning 3 - Brake On for Gear Shift" 4 "Warning 4 - Unavailable to Park" 5 "Warning 5 - Auto Parked" 6 "Warning 6 - Unavailable to Release Park" 7 "Warning 7 - Same Button Re-Entered" ;
VAL_ 2328016130 VCU_EnergyFlowSta 0 "None" 1 "No Flow" 2 "Front Motor Motoring" 3 "Rear Motor Motoring" 4 "Dual Motor Motoring" 5 "Not Used" 6 "Front Motor Generating" 7 "Rear Motor Generating" 8 "Dual Motor Generating" 9 "Not Used" 10 "Reserved" 11 "Reserved" 12 "Reserved" 13 "Reserved" 14 "Reserved" 15 "Reserved" ;
VAL_ 2328016130 VCU_SbwWarnSndSta 0 "Warning Sound Off" 1 "Warning Sound On" 2 "Not used" 3 "Error Indicator" ;
VAL_ 2328016130 VCU_EcoGuide_DispReq 0 "Smart ECO Guide Off" 1 "Smart ECO Guide On" 2 "Not used" 3 "Error Indicator" ;
VAL_ 2328016130 VCU_EcoGuide_ApsGaugeVal 0 "Not Display" 1 "1~100" 2 "1~100" 3 "1~100" 4 "1~100" 5 "1~100" 6 "1~100" 7 "1~100" 8 "1~100" 9 "1~100" 10 "1~100" 11 "1~100" 12 "1~100" 13 "1~100" 14 "1~100" 15 "1~100" 16 "1~100" 17 "1~100" 18 "1~100" 19 "1~100" 20 "1~100" 21 "1~100" 22 "1~100" 23 "1~100" 24 "1~100" 25 "1~100" 26 "1~100" 27 "1~100" 28 "1~100" 29 "1~100" 30 "1~100" 31 "1~100" 32 "1~100" 33 "1~100" 34 "1~100" 35 "1~100" 36 "1~100" 37 "1~100" 38 "1~100" 39 "1~100" 40 "1~100" 41 "1~100" 42 "1~100" 43 "1~100" 44 "1~100" 45 "1~100" 46 "1~100" 47 "1~100" 48 "1~100" 49 "1~100" 50 "1~100" 51 "1~100" 52 "1~100" 53 "1~100" 54 "1~100" 55 "1~100" 56 "1~100" 57 "1~100" 58 "1~100" 59 "1~100" 60 "1~100" 61 "1~100" 62 "1~100" 63 "1~100" 64 "1~100" 65 "1~100" 66 "1~100" 67 "1~100" 68 "1~100" 69 "1~100" 70 "1~100" 71 "1~100" 72 "1~100" 73 "1~100" 74 "1~100" 75 "1~100" 76 "1~100" 77 "1~100" 78 "1~100" 79 "1~100" 80 "1~100" 81 "1~100" 82 "1~100" 83 "1~100" 84 "1~100" 85 "1~100" 86 "1~100" 87 "1~100" 88 "1~100" 89 "1~100" 90 "1~100" 91 "1~100" 92 "1~100" 93 "1~100" 94 "1~100" 95 "1~100" 96 "1~100" 97 "1~100" 98 "1~100" 99 "1~100" 100 "1~100" 101 "Reserved" 102 "Reserved" 103 "Reserved" 104 "Reserved" 105 "Reserved" 106 "Reserved" 107 "Reserved" 108 "Reserved" 109 "Reserved" 110 "Reserved" 111 "Reserved" 112 "Reserved" 113 "Reserved" 114 "Reserved" 115 "Reserved" 116 "Reserved" 117 "Reserved" 118 "Reserved" 119 "Reserved" 120 "Reserved" 121 "Reserved" 122 "Reserved" 123 "Reserved" 124 "Reserved" 125 "Reserved" 126 "Reserved" 127 "Reserved" ;
VAL_ 2328016130 VCU_EcoGuide_EcoGaugeVal 0 "Not Display" 1 "1~100" 2 "1~100" 3 "1~100" 4 "1~100" 5 "1~100" 6 "1~100" 7 "1~100" 8 "1~100" 9 "1~100" 10 "1~100" 11 "1~100" 12 "1~100" 13 "1~100" 14 "1~100" 15 "1~100" 16 "1~100" 17 "1~100" 18 "1~100" 19 "1~100" 20 "1~100" 21 "1~100" 22 "1~100" 23 "1~100" 24 "1~100" 25 "1~100" 26 "1~100" 27 "1~100" 28 "1~100" 29 "1~100" 30 "1~100" 31 "1~100" 32 "1~100" 33 "1~100" 34 "1~100" 35 "1~100" 36 "1~100" 37 "1~100" 38 "1~100" 39 "1~100" 40 "1~100" 41 "1~100" 42 "1~100" 43 "1~100" 44 "1~100" 45 "1~100" 46 "1~100" 47 "1~100" 48 "1~100" 49 "1~100" 50 "1~100" 51 "1~100" 52 "1~100" 53 "1~100" 54 "1~100" 55 "1~100" 56 "1~100" 57 "1~100" 58 "1~100" 59 "1~100" 60 "1~100" 61 "1~100" 62 "1~100" 63 "1~100" 64 "1~100" 65 "1~100" 66 "1~100" 67 "1~100" 68 "1~100" 69 "1~100" 70 "1~100" 71 "1~100" 72 "1~100" 73 "1~100" 74 "1~100" 75 "1~100" 76 "1~100" 77 "1~100" 78 "1~100" 79 "1~100" 80 "1~100" 81 "1~100" 82 "1~100" 83 "1~100" 84 "1~100" 85 "1~100" 86 "1~100" 87 "1~100" 88 "1~100" 89 "1~100" 90 "1~100" 91 "1~100" 92 "1~100" 93 "1~100" 94 "1~100" 95 "1~100" 96 "1~100" 97 "1~100" 98 "1~100" 99 "1~100" 100 "1~100" 101 "Reserved" 102 "Reserved" 103 "Reserved" 104 "Reserved" 105 "Reserved" 106 "Reserved" 107 "Reserved" 108 "Reserved" 109 "Reserved" 110 "Reserved" 111 "Reserved" 112 "Reserved" 113 "Reserved" 114 "Reserved" 115 "Reserved" 116 "Reserved" 117 "Reserved" 118 "Reserved" 119 "Reserved" 120 "Reserved" 121 "Reserved" 122 "Reserved" 123 "Reserved" 124 "Reserved" 125 "Reserved" 126 "Reserved" 127 "Reserved" ;
VAL_ 2328016131 VCU_DistFromRegenDispReq 0 "Default" 1 "Displayed ---" 2 "Positive Value" 3 "Negative Value" ;
VAL_ 2328016131 VCU_DrvStyle_DispReq 0 "Invalid" 1 "Valid" 2 "Not used" 3 "Error Indicator" ;
VAL_ 2328016131 VCU_DrvStyle_HighLightSta 0 "None" 1 "High Fuel Efficiency" 2 "Normal Fuel Efficiency" 3 "Low Fuel Efficiency" ;
VAL_ 2328016131 VCU_DrvStyle_EcoVal 0 "0x0x0~0x64:0~100" 100 "0x0x0~0x64:0~100" 101 "Reserved" 102 "Reserved" 103 "Reserved" 104 "Reserved" 105 "Reserved" 106 "Reserved" 107 "Reserved" 108 "Reserved" 109 "Reserved" 110 "Reserved" 111 "Reserved" 112 "Reserved" 113 "Reserved" 114 "Reserved" 115 "Reserved" 116 "Reserved" 117 "Reserved" 118 "Reserved" 119 "Reserved" 120 "Reserved" 121 "Reserved" 122 "Reserved" 123 "Reserved" 124 "Reserved" 125 "Reserved" 126 "Reserved" 127 "Reserved" ;
VAL_ 2328016131 VCU_DrvStyle_NonEcoVal 0 "0x0x0~0x64:0~100" 100 "0x0x0~0x64:0~100" 101 "Reserved" 102 "Reserved" 103 "Reserved" 104 "Reserved" 105 "Reserved" 106 "Reserved" 107 "Reserved" 108 "Reserved" 109 "Reserved" 110 "Reserved" 111 "Reserved" 112 "Reserved" 113 "Reserved" 114 "Reserved" 115 "Reserved" 116 "Reserved" 117 "Reserved" 118 "Reserved" 119 "Reserved" 120 "Reserved" 121 "Reserved" 122 "Reserved" 123 "Reserved" 124 "Reserved" 125 "Reserved" 126 "Reserved" 127 "Reserved" ;
VAL_ 2328016131 VCU_DrvStyle_NorVal 0 "0x0x0~0x64:0~100" 100 "0x0x0~0x64:0~100" 101 "Reserved" 102 "Reserved" 103 "Reserved" 104 "Reserved" 105 "Reserved" 106 "Reserved" 107 "Reserved" 108 "Reserved" 109 "Reserved" 110 "Reserved" 111 "Reserved" 112 "Reserved" 113 "Reserved" 114 "Reserved" 115 "Reserved" 116 "Reserved" 117 "Reserved" 118 "Reserved" 119 "Reserved" 120 "Reserved" 121 "Reserved" 122 "Reserved" 123 "Reserved" 124 "Reserved" 125 "Reserved" 126 "Reserved" 127 "Reserved" ;
